VERSION "dbc-export 1 2026.26.6.5"

NS_ :

BS_:

BU_: ADSP APB APP APS APSB BB BMS CC CMP CMPD CP DAS DI DIF DIR DPB EPAS3P EPAS3S EPASTP EPASTS EPBL EPBR ESP EVSE FC GTW HCML HCMR HVP IBST ICR IDB LS OCS1P ODIN PARK PCS PCS2 PLG PM PMF PMR PNCD PTC RADC RCM RCM2 RCM3 RCU SCCM SCM SCS SDCR TAS TCU TCU2 TPMS TRCM UDS UI UIS UMC USM V2G VC VCBATT VCBATT0 VCBATT1 VCBATT2 VCCC VCFRONT VCFRONT1 VCFRONT2 VCLEFT VCRIGHT VCSEAT2L VCSEAT2R VCSEC VEH

BO_ 871 DI_alertMatrix: 8 DI
 SG_ DI_matrixIndex M : 0|4@1+ (1,0) [0|15] "" Vector__XXX
 SG_ DI_a001_frunkSpeedLimitActive m0 : 4|1@1+ (1,0) [0|1] "" Vector__XXX
 SG_ DI_a002_parkButtonDuringStalkReq m0 : 5|1@1+ (1,0) [0|1] "" Vector__XXX
 SG_ DI_a003_suggestedGearOverride m0 : 6|1@1+ (1,0) [0|1] "" Vector__XXX
 SG_ DI_a004_smartShiftUnavailable m0 : 7|1@1+ (1,0) [0|1] "" Vector__XXX
 SG_ DI_a005_stalkPanicked m0 : 8|1@1+ (1,0) [0|1] "" Vector__XXX
 SG_ DI_a006_shifterUnavailable m0 : 9|1@1+ (1,0) [0|1] "" Vector__XXX
 SG_ DI_a007_secGearSelButtonStuck m0 : 10|1@1+ (1,0) [0|1] "" Vector__XXX
 SG_ DI_a010_unintendedReset m0 : 13|1@1+ (1,0) [0|1] "" Vector__XXX
 SG_ DI_a012_accel5VSupply m0 : 15|1@1+ (1,0) [0|1] "" Vector__XXX
 SG_ DI_a013_eccError m0 : 16|1@1+ (1,0) [0|1] "" Vector__XXX
 SG_ DI_a014_secGearSelActivated m0 : 17|1@1+ (1,0) [0|1] "" Vector__XXX
 SG_ DI_a015_immobilizer m0 : 18|1@1+ (1,0) [0|1] "" Vector__XXX
 SG_ DI_a016_parkRequestByPM m0 : 19|1@1+ (1,0) [0|1] "" Vector__XXX
 SG_ DI_a017_hwPedalMonitor m0 : 20|1@1+ (1,0) [0|1] "" Vector__XXX
 SG_ DI_a018_hwLVSupplyUV m0 : 21|1@1+ (1,0) [0|1] "" Vector__XXX
 SG_ DI_a019_hwAccelPedalPower m0 : 22|1@1+ (1,0) [0|1] "" Vector__XXX
 SG_ DI_a020_systemHvilNotClosed m0 : 23|1@1+ (1,0) [0|1] "" Vector__XXX
 SG_ DI_a021_packOvervoltage m0 : 24|1@1+ (1,0) [0|1] "" Vector__XXX
 SG_ DI_a022_hw5vSupplyUV m0 : 25|1@1+ (1,0) [0|1] "" Vector__XXX
 SG_ DI_a023_carNotParked m0 : 26|1@1+ (1,0) [0|1] "" Vector__XXX
 SG_ DI_a024_holdNForNeutral m0 : 27|1@1+ (1,0) [0|1] "" Vector__XXX
 SG_ DI_a025_regenBackfillUnavailable m0 : 28|1@1+ (1,0) [0|1] "" Vector__XXX
 SG_ DI_a026_parkPressedWithHighAPeda m0 : 29|1@1+ (1,0) [0|1] "" Vector__XXX
 SG_ DI_a027_steeringAngleOffsetServi m0 : 30|1@1+ (1,0) [0|1] "" Vector__XXX
 SG_ DI_a028_secondaryShifterMuted m0 : 31|1@1+ (1,0) [0|1] "" Vector__XXX
 SG_ DI_a031_closureAccelerationLimit m0 : 34|1@1+ (1,0) [0|1] "" Vector__XXX
 SG_ DI_a036_sysStandbyUnitLimitedWai m0 : 39|1@1+ (1,0) [0|1] "" Vector__XXX
 SG_ DI_a039_exceptionUndefinedInstru m0 : 42|1@1+ (1,0) [0|1] "" Vector__XXX
 SG_ DI_a040_difMIA m0 : 43|1@1+ (1,0) [0|1] "" Vector__XXX
 SG_ DI_a041_driverBrakeApplyStuck m0 : 44|1@1+ (1,0) [0|1] "" Vector__XXX
 SG_ DI_a042_pmfMIA m0 : 45|1@1+ (1,0) [0|1] "" Vector__XXX
 SG_ DI_a043_pmrMIA m0 : 46|1@1+ (1,0) [0|1] "" Vector__XXX
 SG_ DI_d047_interfacePowerSupplyIssu m0 : 50|1@1+ (1,0) [0|1] "" Vector__XXX
 SG_ DI_a048_ecuLogAvailable m0 : 51|1@1+ (1,0) [0|1] "" Vector__XXX
 SG_ DI_d049_invalidOdometerReading m0 : 52|1@1+ (1,0) [0|1] "" Vector__XXX
 SG_ DI_d050_interfaceUnitCommunicati m0 : 53|1@1+ (1,0) [0|1] "" Vector__XXX
 SG_ DI_a051_batteryOvercurrent m0 : 54|1@1+ (1,0) [0|1] "" Vector__XXX
 SG_ DI_a052_dirMIA m0 : 55|1@1+ (1,0) [0|1] "" Vector__XXX
 SG_ DI_a053_canDataBusC m0 : 56|1@1+ (1,0) [0|1] "" Vector__XXX
 SG_ DI_a054_canOverrunBusC m0 : 57|1@1+ (1,0) [0|1] "" Vector__XXX
 SG_ DI_a055_canHardwareBusC m0 : 58|1@1+ (1,0) [0|1] "" Vector__XXX
 SG_ DI_a056_canDataBusD m0 : 59|1@1+ (1,0) [0|1] "" Vector__XXX
 SG_ DI_a057_canOverrunBusD m0 : 60|1@1+ (1,0) [0|1] "" Vector__XXX
 SG_ DI_a058_canHardwareBusD m0 : 61|1@1+ (1,0) [0|1] "" Vector__XXX
 SG_ DI_a059_canDataBusE m0 : 62|1@1+ (1,0) [0|1] "" Vector__XXX
 SG_ DI_a060_canOverrunBusE m0 : 63|1@1+ (1,0) [0|1] "" Vector__XXX
 SG_ DI_a061_canHardwareBusE m1 : 4|1@1+ (1,0) [0|1] "" Vector__XXX
 SG_ DI_a062_systemLimpMode m1 : 5|1@1+ (1,0) [0|1] "" Vector__XXX
 SG_ DI_a063_systemGracefulPowerOff m1 : 6|1@1+ (1,0) [0|1] "" Vector__XXX
 SG_ DI_a064_pmsrmUnitMiaWithHvDown m1 : 7|1@1+ (1,0) [0|1] "" Vector__XXX
 SG_ DI_a065_canHardwareBusB m1 : 8|1@1+ (1,0) [0|1] "" Vector__XXX
 SG_ DI_a066_canDataBusB m1 : 9|1@1+ (1,0) [0|1] "" Vector__XXX
 SG_ DI_a067_canOverrunBusB m1 : 10|1@1+ (1,0) [0|1] "" Vector__XXX
 SG_ DI_a068_secondaryWheelSpeedIrrat m1 : 11|1@1+ (1,0) [0|1] "" Vector__XXX
 SG_ DI_a070_udsTransactionInitiated m1 : 13|1@1+ (1,0) [0|1] "" Vector__XXX
 SG_ DI_d072_accelPedalSensorIssue m1 : 15|1@1+ (1,0) [0|1] "" Vector__XXX
 SG_ DI_d073_accelPedalVoltSupplyIssu m1 : 16|1@1+ (1,0) [0|1] "" Vector__XXX
 SG_ DI_a074_unintendedResetAutoshift m1 : 17|1@1+ (1,0) [0|1] "" Vector__XXX
 SG_ DI_d075_incorrectImmobilizerKey m1 : 18|1@1+ (1,0) [0|1] "" Vector__XXX
 SG_ DI_a076_lvSupplyOV m1 : 19|1@1+ (1,0) [0|1] "" Vector__XXX
 SG_ DI_a077_lvSupplyUV m1 : 20|1@1+ (1,0) [0|1] "" Vector__XXX
 SG_ DI_a078_adcRefLow m1 : 21|1@1+ (1,0) [0|1] "" Vector__XXX
 SG_ DI_a079_adcRefHigh m1 : 22|1@1+ (1,0) [0|1] "" Vector__XXX
 SG_ DI_a080_accelSynch m1 : 23|1@1+ (1,0) [0|1] "" Vector__XXX
 SG_ DI_a081_accelTrack1 m1 : 24|1@1+ (1,0) [0|1] "" Vector__XXX
 SG_ DI_a082_accelTrack2 m1 : 25|1@1+ (1,0) [0|1] "" Vector__XXX
 SG_ DI_a083_brakePedalSensor m1 : 26|1@1+ (1,0) [0|1] "" Vector__XXX
 SG_ DI_a084_eccTestData0 m1 : 27|1@1+ (1,0) [0|1] "" Vector__XXX
 SG_ DI_a085_proximityInEnable m1 : 28|1@1+ (1,0) [0|1] "" Vector__XXX
 SG_ DI_a086_dpbMIA m1 : 29|1@1+ (1,0) [0|1] "" Vector__XXX
 SG_ DI_a087_gtwMIA m1 : 30|1@1+ (1,0) [0|1] "" Vector__XXX
 SG_ DI_a088_uiMIA m1 : 31|1@1+ (1,0) [0|1] "" Vector__XXX
 SG_ DI_a089_sccmMIA m1 : 32|1@1+ (1,0) [0|1] "" Vector__XXX
 SG_ DI_a090_pmMIA m1 : 33|1@1+ (1,0) [0|1] "" Vector__XXX
 SG_ DI_a091_espMIA m1 : 34|1@1+ (1,0) [0|1] "" Vector__XXX
 SG_ DI_a092_bmsMIA m1 : 35|1@1+ (1,0) [0|1] "" Vector__XXX
 SG_ DI_a093_canHardwareBusA m1 : 36|1@1+ (1,0) [0|1] "" Vector__XXX
 SG_ DI_a094_canDataBusA m1 : 37|1@1+ (1,0) [0|1] "" Vector__XXX
 SG_ DI_a095_canOverrunBusA m1 : 38|1@1+ (1,0) [0|1] "" Vector__XXX
 SG_ DI_a096_memoryError m1 : 39|1@1+ (1,0) [0|1] "" Vector__XXX
 SG_ DI_a097_eepromError m1 : 40|1@1+ (1,0) [0|1] "" Vector__XXX
 SG_ DI_a098_eepromManagerError m1 : 41|1@1+ (1,0) [0|1] "" Vector__XXX
 SG_ DI_a099_threadOverrun m1 : 42|1@1+ (1,0) [0|1] "" Vector__XXX
 SG_ DI_a100_nvramError m1 : 43|1@1+ (1,0) [0|1] "" Vector__XXX
 SG_ DI_a101_eccTestData1 m1 : 44|1@1+ (1,0) [0|1] "" Vector__XXX
 SG_ DI_a102_exceptionPrefetchAbort m1 : 45|1@1+ (1,0) [0|1] "" Vector__XXX
 SG_ DI_a103_bbMIA m1 : 46|1@1+ (1,0) [0|1] "" Vector__XXX
 SG_ DI_a104_proximityIrrational m1 : 47|1@1+ (1,0) [0|1] "" Vector__XXX
 SG_ DI_a105_cpMIA m1 : 48|1@1+ (1,0) [0|1] "" Vector__XXX
 SG_ DI_a106_idleTaskStarving m1 : 49|1@1+ (1,0) [0|1] "" Vector__XXX
 SG_ DI_a107_idbBrakeCircuitPressureO m1 : 50|1@1+ (1,0) [0|1] "" Vector__XXX
 SG_ DI_a108_appMIA m1 : 51|1@1+ (1,0) [0|1] "" Vector__XXX
 SG_ DI_a109_ahbWriteError m1 : 52|1@1+ (1,0) [0|1] "" Vector__XXX
 SG_ DI_a110_brakeMIA m1 : 53|1@1+ (1,0) [0|1] "" Vector__XXX
 SG_ DI_a111_idbMIA m1 : 54|1@1+ (1,0) [0|1] "" Vector__XXX
 SG_ DI_a112_accelTrack1Incons m1 : 55|1@1+ (1,0) [0|1] "" Vector__XXX
 SG_ DI_a113_lowBrakeMCPressure m1 : 56|1@1+ (1,0) [0|1] "" Vector__XXX
 SG_ DI_a114_exceptionDataAbort m1 : 57|1@1+ (1,0) [0|1] "" Vector__XXX
 SG_ DI_a115_exceptionDataAbort2 m1 : 58|1@1+ (1,0) [0|1] "" Vector__XXX
 SG_ DI_a116_motorRecovered m1 : 59|1@1+ (1,0) [0|1] "" Vector__XXX
 SG_ DI_a117_latentFaultCheckTripped m1 : 60|1@1+ (1,0) [0|1] "" Vector__XXX
 SG_ DI_a118_diImmobilizedForFactoryF m1 : 61|1@1+ (1,0) [0|1] "" Vector__XXX
 SG_ DI_a119_latentFaultCheckFailedOn m1 : 62|1@1+ (1,0) [0|1] "" Vector__XXX
 SG_ DI_a120_regenBlendingUnavailable m1 : 63|1@1+ (1,0) [0|1] "" Vector__XXX
 SG_ DI_a121_qualifiedBrakeEventMitig m2 : 4|1@1+ (1,0) [0|1] "" Vector__XXX
 SG_ DI_a122_highStackUsage m2 : 5|1@1+ (1,0) [0|1] "" Vector__XXX
 SG_ DI_a124_cruiseFault m2 : 7|1@1+ (1,0) [0|1] "" Vector__XXX
 SG_ DI_a125_noBatteryPower m2 : 8|1@1+ (1,0) [0|1] "" Vector__XXX
 SG_ DI_a129_epbNotApplied m2 : 12|1@1+ (1,0) [0|1] "" Vector__XXX
 SG_ DI_a130_aebFault m2 : 13|1@1+ (1,0) [0|1] "" Vector__XXX
 SG_ DI_a131_highSpeedWearLimit m2 : 14|1@1+ (1,0) [0|1] "" Vector__XXX
 SG_ DI_a133_vehicleHoldTimedOut m2 : 16|1@1+ (1,0) [0|1] "" Vector__XXX
 SG_ DI_a134_wheelSpeedIrrational m2 : 17|1@1+ (1,0) [0|1] "" Vector__XXX
 SG_ DI_a135_vehicleHoldFault m2 : 18|1@1+ (1,0) [0|1] "" Vector__XXX
 SG_ DI_a137_noCapableDriveUnits m2 : 20|1@1+ (1,0) [0|1] "" Vector__XXX
 SG_ DI_a138_frontUnitDisabled m2 : 21|1@1+ (1,0) [0|1] "" Vector__XXX
 SG_ DI_a139_rearUnitDisabled m2 : 22|1@1+ (1,0) [0|1] "" Vector__XXX
 SG_ DI_a140_ptcMIA m2 : 23|1@1+ (1,0) [0|1] "" Vector__XXX
 SG_ DI_a141_dasMIA m2 : 24|1@1+ (1,0) [0|1] "" Vector__XXX
 SG_ DI_a142_potholeDetected m2 : 25|1@1+ (1,0) [0|1] "" Vector__XXX
 SG_ DI_a143_mcuLimitActive m2 : 26|1@1+ (1,0) [0|1] "" Vector__XXX
 SG_ DI_a144_configMismatch m2 : 27|1@1+ (1,0) [0|1] "" Vector__XXX
 SG_ DI_a146_pbrkPanicEpbFault m2 : 29|1@1+ (1,0) [0|1] "" Vector__XXX
 SG_ DI_a154_vdcRearSteering m2 : 37|1@1+ (1,0) [0|1] "" Vector__XXX
 SG_ DI_a155_vcfrontMIA m2 : 38|1@1+ (1,0) [0|1] "" Vector__XXX
 SG_ DI_a157_rcmMIA m2 : 40|1@1+ (1,0) [0|1] "" Vector__XXX
 SG_ DI_a158_ibstMIA m2 : 41|1@1+ (1,0) [0|1] "" Vector__XXX
 SG_ DI_a159_cruiseSelfCheck m2 : 42|1@1+ (1,0) [0|1] "" Vector__XXX
 SG_ DI_a160_fastLearnComplete m2 : 43|1@1+ (1,0) [0|1] "" Vector__XXX
 SG_ DI_a161_epas3pMIA m2 : 44|1@1+ (1,0) [0|1] "" Vector__XXX
 SG_ DI_a162_shiftDenied m2 : 45|1@1+ (1,0) [0|1] "" Vector__XXX
 SG_ DI_a163_shiftMotorSpeed m2 : 46|1@1+ (1,0) [0|1] "" Vector__XXX
 SG_ DI_a164_brakeOverride m2 : 47|1@1+ (1,0) [0|1] "" Vector__XXX
 SG_ DI_a165_cruiseCancelled m2 : 48|1@1+ (1,0) [0|1] "" Vector__XXX
 SG_ DI_a166_driverLeft m2 : 49|1@1+ (1,0) [0|1] "" Vector__XXX
 SG_ DI_a167_keyNotAuthenticated m2 : 50|1@1+ (1,0) [0|1] "" Vector__XXX
 SG_ DI_a168_proximityDriveDenial m2 : 51|1@1+ (1,0) [0|1] "" Vector__XXX
 SG_ DI_a169_regenOffOverride m2 : 52|1@1+ (1,0) [0|1] "" Vector__XXX
 SG_ DI_a170_tireConfigUpdated m2 : 53|1@1+ (1,0) [0|1] "" Vector__XXX
 SG_ DI_a171_driveRailNotRequested m2 : 54|1@1+ (1,0) [0|1] "" Vector__XXX
 SG_ DI_a172_accelPressedInNP m2 : 55|1@1+ (1,0) [0|1] "" Vector__XXX
 SG_ DI_a173_bothPedalsPressed m2 : 56|1@1+ (1,0) [0|1] "" Vector__XXX
 SG_ DI_a174_notOkToStartDrive m2 : 57|1@1+ (1,0) [0|1] "" Vector__XXX
 SG_ DI_a175_crsNotAvailable m2 : 58|1@1+ (1,0) [0|1] "" Vector__XXX
 SG_ DI_a176_EBRreleased m2 : 59|1@1+ (1,0) [0|1] "" Vector__XXX
 SG_ DI_a177_tireFitmentChanged m2 : 60|1@1+ (1,0) [0|1] "" Vector__XXX
 SG_ DI_a178_steeringAngleOffsetFault m2 : 61|1@1+ (1,0) [0|1] "" Vector__XXX
 SG_ DI_a179_steeringAngleOffsetWarni m2 : 62|1@1+ (1,0) [0|1] "" Vector__XXX
 SG_ DI_a180_crsSeatbeltUnbuckled m2 : 63|1@1+ (1,0) [0|1] "" Vector__XXX
 SG_ DI_a181_rearMotorMode m3 : 4|1@1+ (1,0) [0|1] "" Vector__XXX
 SG_ DI_a182_frontMotorMode m3 : 5|1@1+ (1,0) [0|1] "" Vector__XXX
 SG_ DI_a183_holdReleaseRqrd m3 : 6|1@1+ (1,0) [0|1] "" Vector__XXX
 SG_ DI_a184_autoparkCanceled m3 : 7|1@1+ (1,0) [0|1] "" Vector__XXX
 SG_ DI_a185_autoparkAborted m3 : 8|1@1+ (1,0) [0|1] "" Vector__XXX
 SG_ DI_a186_brakeStand m3 : 9|1@1+ (1,0) [0|1] "" Vector__XXX
 SG_ DI_a187_pedalMisapplication m3 : 10|1@1+ (1,0) [0|1] "" Vector__XXX
 SG_ DI_a188_tireRotationRecommendedG m3 : 11|1@1+ (1,0) [0|1] "" Vector__XXX
 SG_ DI_a189_garageShiftWithPedal m3 : 12|1@1+ (1,0) [0|1] "" Vector__XXX
 SG_ DI_a190_tireRotationRecommended m3 : 13|1@1+ (1,0) [0|1] "" Vector__XXX
 SG_ DI_a191_brakeShiftReq m3 : 14|1@1+ (1,0) [0|1] "" Vector__XXX
 SG_ DI_a192_invalidOdometer m3 : 15|1@1+ (1,0) [0|1] "" Vector__XXX
 SG_ DI_a193_vdcBrakeTorqueFr m3 : 16|1@1+ (1,0) [0|1] "" Vector__XXX
 SG_ DI_a194_vdcBrakeTorqueRe m3 : 17|1@1+ (1,0) [0|1] "" Vector__XXX
 SG_ DI_a195_vdcEspSlipFr m3 : 18|1@1+ (1,0) [0|1] "" Vector__XXX
 SG_ DI_a196_vdcEspSlipRe m3 : 19|1@1+ (1,0) [0|1] "" Vector__XXX
 SG_ DI_a197_vdcEspWheelSaturations m3 : 20|1@1+ (1,0) [0|1] "" Vector__XXX
 SG_ DI_a198_vdcEspMCPressAndSteering m3 : 21|1@1+ (1,0) [0|1] "" Vector__XXX
 SG_ DI_a199_vdcFaulted m3 : 22|1@1+ (1,0) [0|1] "" Vector__XXX
 SG_ DI_a200_vdcModelBasedPlausibilit m3 : 23|1@1+ (1,0) [0|1] "" Vector__XXX
 SG_ DI_a201_decelTorqueLimited m3 : 24|1@1+ (1,0) [0|1] "" Vector__XXX
 SG_ DI_a202_excessHeatUnavailable m3 : 25|1@1+ (1,0) [0|1] "" Vector__XXX
 SG_ DI_a203_TCReducedByADD m3 : 26|1@1+ (1,0) [0|1] "" Vector__XXX
 SG_ DI_a204_vdcRcmLongitudinal m3 : 27|1@1+ (1,0) [0|1] "" Vector__XXX
 SG_ DI_a205_vdcRcmLateral m3 : 28|1@1+ (1,0) [0|1] "" Vector__XXX
 SG_ DI_a206_vdcRcmVertical m3 : 29|1@1+ (1,0) [0|1] "" Vector__XXX
 SG_ DI_a207_vdcPowertrainTorque_dif m3 : 30|1@1+ (1,0) [0|1] "" Vector__XXX
 SG_ DI_a208_vdcPowertrainTorque_dir m3 : 31|1@1+ (1,0) [0|1] "" Vector__XXX
 SG_ DI_a210_vdcOtherControllerStates m3 : 33|1@1+ (1,0) [0|1] "" Vector__XXX
 SG_ DI_a211_vdcMotorSpeed_dif m3 : 34|1@1+ (1,0) [0|1] "" Vector__XXX
 SG_ DI_a212_vdcWheelRotations m3 : 35|1@1+ (1,0) [0|1] "" Vector__XXX
 SG_ DI_a213_lowMuProbabilityChange m3 : 36|1@1+ (1,0) [0|1] "" Vector__XXX
 SG_ DI_a214_vdcWheelSpeedFr m3 : 37|1@1+ (1,0) [0|1] "" Vector__XXX
 SG_ DI_a215_vdcWheelSpeedRe m3 : 38|1@1+ (1,0) [0|1] "" Vector__XXX
 SG_ DI_a216_vdcMBPAlmostTripped m3 : 39|1@1+ (1,0) [0|1] "" Vector__XXX
 SG_ DI_a217_vdcOutputIrrational m3 : 40|1@1+ (1,0) [0|1] "" Vector__XXX
 SG_ DI_a218_vdcOSPreControlActive m3 : 41|1@1+ (1,0) [0|1] "" Vector__XXX
 SG_ DI_a219_vdcOversteerdMzActive m3 : 42|1@1+ (1,0) [0|1] "" Vector__XXX
 SG_ DI_a220_vdcUndersteerDecelActive m3 : 43|1@1+ (1,0) [0|1] "" Vector__XXX
 SG_ DI_a221_vdcUndersteerdMzActive m3 : 44|1@1+ (1,0) [0|1] "" Vector__XXX
 SG_ DI_a222_vdcDisabled m3 : 45|1@1+ (1,0) [0|1] "" Vector__XXX
 SG_ DI_a223_tractionControlDisabled m3 : 46|1@1+ (1,0) [0|1] "" Vector__XXX
 SG_ DI_a224_brakeOverTemp m3 : 47|1@1+ (1,0) [0|1] "" Vector__XXX
 SG_ DI_a225_vyEstimatorDegradedDebug m3 : 48|1@1+ (1,0) [0|1] "" Vector__XXX
 SG_ DI_a226_sysStartConditionNotMet m3 : 49|1@1+ (1,0) [0|1] "" Vector__XXX
 SG_ DI_a227_contactorsNotClosed m3 : 50|1@1+ (1,0) [0|1] "" Vector__XXX
 SG_ DI_a228_brakeTempEstUnavailable m3 : 51|1@1+ (1,0) [0|1] "" Vector__XXX
 SG_ DI_a230_cmpMIA m3 : 53|1@1+ (1,0) [0|1] "" Vector__XXX
 SG_ DI_a231_softSystemLimpMode m3 : 54|1@1+ (1,0) [0|1] "" Vector__XXX
 SG_ DI_a232_velocityEstimatorDegrade m3 : 55|1@1+ (1,0) [0|1] "" Vector__XXX
 SG_ DI_a233_frontWheelImpactDetected m3 : 56|1@1+ (1,0) [0|1] "" Vector__XXX
 SG_ DI_a235_trackModeActive m3 : 58|1@1+ (1,0) [0|1] "" Vector__XXX
 SG_ DI_a236_tasMIA m3 : 59|1@1+ (1,0) [0|1] "" Vector__XXX
 SG_ DI_a237_undersideAbuse m3 : 60|1@1+ (1,0) [0|1] "" Vector__XXX
 SG_ DI_a238_secondaryCollisionMitiga m3 : 61|1@1+ (1,0) [0|1] "" Vector__XXX
 SG_ DI_a239_neutralRequestByPM m3 : 62|1@1+ (1,0) [0|1] "" Vector__XXX
 SG_ DI_a240_torqueSplitStuck m3 : 63|1@1+ (1,0) [0|1] "" Vector__XXX
 SG_ DI_a241_vdcMotorSpeed_dir m4 : 4|1@1+ (1,0) [0|1] "" Vector__XXX
 SG_ DI_a242_vdcTrailerSwayDetected m4 : 5|1@1+ (1,0) [0|1] "" Vector__XXX
 SG_ DI_a243_rcuMIA m4 : 6|1@1+ (1,0) [0|1] "" Vector__XXX
 SG_ DI_a244_vseRLSMassMismatch m4 : 7|1@1+ (1,0) [0|1] "" Vector__XXX
 SG_ DI_a245_opdReducedWithoutEbr m4 : 8|1@1+ (1,0) [0|1] "" Vector__XXX
 SG_ DI_a246_opdUnavailable m4 : 9|1@1+ (1,0) [0|1] "" Vector__XXX
 SG_ DI_a248_vdcPreControlHighDynamic m4 : 11|1@1+ (1,0) [0|1] "" Vector__XXX
 SG_ DI_a249_spinDownLearningInProgre m4 : 12|1@1+ (1,0) [0|1] "" Vector__XXX
 SG_ DI_a250_tasSpeedLimitActive m4 : 13|1@1+ (1,0) [0|1] "" Vector__XXX
 SG_ DI_a251_diPowerOnStateMismatch m4 : 14|1@1+ (1,0) [0|1] "" Vector__XXX
 SG_ DI_a253_accelSynchWarn m4 : 16|1@1+ (1,0) [0|1] "" Vector__XXX
 SG_ DI_a254_vehicleStuckDetected m4 : 17|1@1+ (1,0) [0|1] "" Vector__XXX
 SG_ DI_a255_manualRecoveryMode m4 : 18|1@1+ (1,0) [0|1] "" Vector__XXX

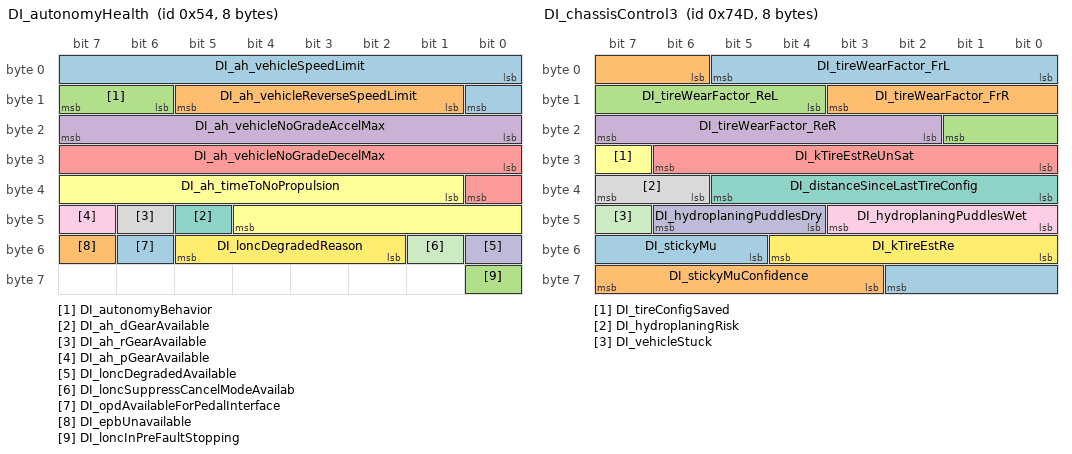
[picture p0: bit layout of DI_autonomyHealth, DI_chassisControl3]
BO_ 84 DI_autonomyHealth: 8 DI
 SG_ DI_ah_vehicleSpeedLimit : 0|9@1+ (1,0) [0|300] "kph" Vector__XXX
 SG_ DI_ah_vehicleReverseSpeedLimit : 9|5@1+ (1,0) [0|31] "kph" Vector__XXX
 SG_ DI_autonomyBehavior : 14|2@1+ (1,0) [0|3] "" Vector__XXX
 SG_ DI_ah_vehicleNoGradeAccelMax : 16|8@1+ (0.04,0) [0|10] "m/s^2" Vector__XXX
 SG_ DI_ah_vehicleNoGradeDecelMax : 24|9@1+ (0.04,0) [0|15] "m/s^2" Vector__XXX
 SG_ DI_ah_timeToNoPropulsion : 33|12@1+ (1,0) [0|4094] "s" Vector__XXX
 SG_ DI_ah_dGearAvailable : 45|1@1+ (1,0) [0|1] "" Vector__XXX
 SG_ DI_ah_rGearAvailable : 46|1@1+ (1,0) [0|1] "" Vector__XXX
 SG_ DI_ah_pGearAvailable : 47|1@1+ (1,0) [0|1] "" Vector__XXX
 SG_ DI_loncDegradedAvailable : 48|1@1+ (1,0) [0|1] "" Vector__XXX
 SG_ DI_loncSuppressCancelModeAvailab : 49|1@1+ (1,0) [0|1] "" Vector__XXX
 SG_ DI_loncDegradedReason : 50|4@1+ (1,0) [0|15] "" Vector__XXX
 SG_ DI_opdAvailableForPedalInterface : 54|1@1+ (1,0) [0|1] "" Vector__XXX
 SG_ DI_epbUnavailable : 55|1@1+ (1,0) [0|1] "" Vector__XXX
 SG_ DI_loncInPreFaultStopping : 56|1@1+ (1,0) [0|1] "" Vector__XXX

BO_ 328 DI_chassisControl: 8 DI
 SG_ DI_chassisControlChecksum : 0|8@1+ (1,0) [0|255] "" Vector__XXX
 SG_ DI_chassisControlCounter : 8|4@1+ (1,0) [0|15] "" Vector__XXX
 SG_ DI_imuOffsetLearnRequest : 12|2@1+ (1,0) [0|3] "" Vector__XXX
 SG_ DI_brakeCommandType : 14|1@1+ (1,0) [0|1] "" Vector__XXX
 SG_ DI_brakeTorqueRequestActive : 15|1@1+ (1,0) [0|1] "" Vector__XXX
 SG_ DI_brakeTorqueCommand : 16|13@1+ (3,0) [0|24573] "Nm" Vector__XXX
 SG_ DI_ptcStateGlobal : 29|2@1+ (1,0) [0|2] "" Vector__XXX
 SG_ DI_ptcActive : 31|1@1+ (1,0) [0|1] "" Vector__XXX
 SG_ DI_vdcState : 32|2@1+ (1,0) [0|3] "" Vector__XXX
 SG_ DI_isAnyVdcControlActive : 34|2@1+ (1,0) [0|3] "" Vector__XXX
 SG_ DI_vdcMode : 36|2@1+ (1,0) [0|3] "" Vector__XXX
 SG_ DI_pedalAssistCurveSelect : 38|4@1+ (1,0) [0|15] "" Vector__XXX
 SG_ DI_isAnyTcActive : 42|1@1+ (1,0) [0|1] "" Vector__XXX
 SG_ DI_VehicleMuConfidence : 43|6@1+ (0.02,0) [0|1.26] "-" Vector__XXX
 SG_ DI_VehicleMu : 49|6@1+ (0.024,0) [0|1.512] "-" Vector__XXX
 SG_ DI_trailerSwayIndex : 55|5@1+ (0.035,0) [0|1] "-" Vector__XXX
 SG_ DI_vdcControlActive : 60|3@1+ (1,0) [0|7] "" Vector__XXX
 SG_ DI_treadDepthAlertSet : 63|1@1+ (1,0) [0|1] "" Vector__XXX

BO_ 1861 DI_chassisControl2: 8 DI
 SG_ DI_gradeAngle : 0|6@1- (0.01,0) [-0.3125|0.31] "rad" Vector__XXX
 SG_ DI_bankAngle : 6|6@1- (0.01,0) [-0.3125|0.31] "rad" Vector__XXX
 SG_ DI_chassisControlVideoRequest : 12|4@1+ (1,0) [0|15] "" Vector__XXX
 SG_ DI_eepDeliveryBitStatus : 16|1@1+ (1,0) [0|1] "" Vector__XXX
 SG_ DI_tireUtilizationRatioFrL : 17|5@1+ (0.0625,0) [0|1.9375] "-" Vector__XXX
 SG_ DI_tireUtilizationRatioFrR : 22|5@1+ (0.0625,0) [0|1.9375] "-" Vector__XXX
 SG_ DI_tireUtilizationRatioReL : 27|5@1+ (0.0625,0) [0|1.9375] "-" Vector__XXX
 SG_ DI_tireUtilizationRatioReR : 32|5@1+ (0.0625,0) [0|1.9375] "-" Vector__XXX
 SG_ DI_counterSteerTarget : 37|2@1+ (1,0) [0|3] "" Vector__XXX
 SG_ DI_splitMuProbability : 39|2@1+ (0.334,0) [0|1] "-" Vector__XXX
 SG_ DI_mzError : 41|2@1+ (1667,0) [0|5000] "Nm" Vector__XXX
 SG_ DI_slipDifferenceFrontRear : 43|3@1- (0.133,0) [-0.52|0.399] "rad" Vector__XXX
 SG_ DI_highFreqYawRate : 46|2@1+ (0.334,0) [0|1] "-" Vector__XXX
 SG_ DI_turnDirection : 48|1@1+ (1,0) [0|1] "" Vector__XXX
 SG_ DI_absolutePreControlRequest : 49|2@1+ (5000,0) [0|15000] "Nm" Vector__XXX
 SG_ DI_oppositeBuildDirFrontAxle : 51|1@1+ (1,0) [0|1] "" Vector__XXX
 SG_ DI_oppositeBuildDirRearAxle : 52|1@1+ (1,0) [0|1] "" Vector__XXX
 SG_ DI_saturatedEffectiveness : 53|1@1+ (1,0) [0|1] "" Vector__XXX
 SG_ DI_driverPanicIndex : 54|2@1+ (0.334,0) [0|1] "-" Vector__XXX
 SG_ DI_learnDownMu : 56|2@1+ (0.334,0) [0|1] "mu" Vector__XXX
 SG_ DI_preControlOpposingTurnDir : 58|1@1+ (1,0) [0|1] "" Vector__XXX
 SG_ DI_driverFxError : 59|2@1+ (1000,0) [0|3000] "N" Vector__XXX
 SG_ DI_targetSaturation : 61|3@1+ (0.572,0) [0|4] "G" Vector__XXX

BO_ 1869 DI_chassisControl3: 8 DI
 SG_ DI_tireWearFactor_FrL : 0|6@1+ (0.00125,0.96) [0.96|1.03875] "ratio" Vector__XXX
 SG_ DI_tireWearFactor_FrR : 6|6@1+ (0.00125,0.96) [0.96|1.03875] "ratio" Vector__XXX
 SG_ DI_tireWearFactor_ReL : 12|6@1+ (0.00125,0.96) [0.96|1.03875] "ratio" Vector__XXX
 SG_ DI_tireWearFactor_ReR : 18|6@1+ (0.00125,0.96) [0.96|1.03875] "ratio" Vector__XXX
 SG_ DI_kTireEstReUnSat : 24|7@1+ (0.001,0.008) [0.008|0.075] "-" Vector__XXX
 SG_ DI_tireConfigSaved : 31|1@1+ (1,0) [0|1] "" Vector__XXX
 SG_ DI_distanceSinceLastTireConfig : 32|6@1+ (500,0) [0|31000] "km" Vector__XXX
 SG_ DI_hydroplaningRisk : 38|2@1+ (0.333333343267,0) [0|1] "-" Vector__XXX
 SG_ DI_hydroplaningPuddlesWet : 40|4@1+ (1,0) [0|15] "-" Vector__XXX
 SG_ DI_hydroplaningPuddlesDry : 44|3@1+ (1,0) [0|7] "-" Vector__XXX
 SG_ DI_vehicleStuck : 47|1@1+ (1,0) [0|1] "" Vector__XXX
 SG_ DI_kTireEstRe : 48|5@1+ (0.001,0.03) [0.03|0.06] "-" Vector__XXX
 SG_ DI_stickyMu : 53|6@1+ (0.025,0) [0|1.575] "-" Vector__XXX
 SG_ DI_stickyMuConfidence : 59|5@1+ (0.1,0) [0|3] "probability" Vector__XXX

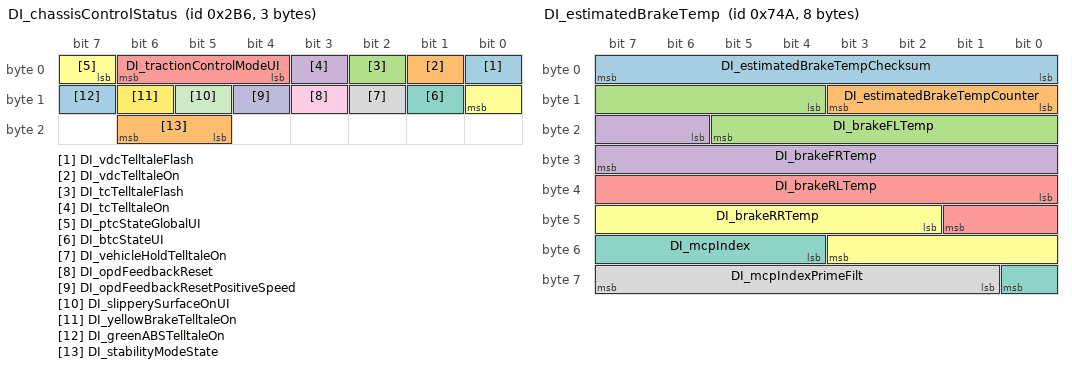
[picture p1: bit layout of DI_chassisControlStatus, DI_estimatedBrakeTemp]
BO_ 694 DI_chassisControlStatus: 3 DI
 SG_ DI_vdcTelltaleFlash : 0|1@1+ (1,0) [0|1] "" Vector__XXX
 SG_ DI_vdcTelltaleOn : 1|1@1+ (1,0) [0|1] "" Vector__XXX
 SG_ DI_tcTelltaleFlash : 2|1@1+ (1,0) [0|1] "" Vector__XXX
 SG_ DI_tcTelltaleOn : 3|1@1+ (1,0) [0|1] "" Vector__XXX
 SG_ DI_tractionControlModeUI : 4|3@1+ (1,0) [0|7] "" Vector__XXX
 SG_ DI_ptcStateGlobalUI : 7|2@1+ (1,0) [0|2] "" Vector__XXX
 SG_ DI_btcStateUI : 9|1@1+ (1,0) [0|1] "" Vector__XXX
 SG_ DI_vehicleHoldTelltaleOn : 10|1@1+ (1,0) [0|1] "" Vector__XXX
 SG_ DI_opdFeedbackReset : 11|1@1+ (1,0) [0|1] "" Vector__XXX
 SG_ DI_opdFeedbackResetPositiveSpeed : 12|1@1+ (1,0) [0|1] "" Vector__XXX
 SG_ DI_slipperySurfaceOnUI : 13|1@1+ (1,0) [0|1] "" Vector__XXX
 SG_ DI_yellowBrakeTelltaleOn : 14|1@1+ (1,0) [0|1] "" Vector__XXX
 SG_ DI_greenABSTelltaleOn : 15|1@1+ (1,0) [0|1] "" Vector__XXX
 SG_ DI_stabilityModeState : 21|2@1+ (1,0) [0|3] "" Vector__XXX

BO_ 2007 DI_debug: 8 DI
 SG_ DI_debugSelector M : 0|8@1+ (1,0) [0|255] "" Vector__XXX
 SG_ DI_regenBackfillCmd m39 : 8|13@1+ (2,0) [0|16382] "Nm" Vector__XXX
 SG_ DI_regenBackfillUnavailableReaso m39 : 21|5@1+ (1,0) [0|31] "" Vector__XXX
 SG_ DI_regenBackfillAbsSatState m39 : 26|2@1+ (1,0) [0|3] "" Vector__XXX
 SG_ DI_sysHeatPowerOptimal m50 : 8|8@1+ (0.08,0) [0|20] "kW" Vector__XXX
 SG_ DI_sysPostPedalMinTorque m53 : 8|15@1+ (0.5,-13000) [-13000|0] "Nm" Vector__XXX
 SG_ DI_sysPostPedalMaxTorque m53 : 24|15@1+ (0.5,0) [0|13000] "Nm" Vector__XXX
 SG_ DI_systemTorqueCommand m53 : 40|16@1- (0.5,0) [-13000|13000] "Nm" Vector__XXX

BO_ 1866 DI_estimatedBrakeTemp: 8 DI
 SG_ DI_estimatedBrakeTempChecksum : 0|8@1+ (1,0) [0|255] "" Vector__XXX
 SG_ DI_estimatedBrakeTempCounter : 8|4@1+ (1,0) [0|15] "" Vector__XXX
 SG_ DI_brakeFLTemp : 12|10@1+ (1,-40) [-40|982] "DegC" Vector__XXX
 SG_ DI_brakeFRTemp : 22|10@1+ (1,-40) [-40|982] "DegC" Vector__XXX
 SG_ DI_brakeRLTemp : 32|10@1+ (1,-40) [-40|982] "DegC" Vector__XXX
 SG_ DI_brakeRRTemp : 42|10@1+ (1,-40) [-40|982] "DegC" Vector__XXX
 SG_ DI_mcpIndex : 52|5@1- (0.05,0.75) [-0.05|1.5] "ratio" Vector__XXX
 SG_ DI_mcpIndexPrimeFilt : 57|7@1- (0.015,0.9) [-0.05|1.84] "ratio" Vector__XXX

BO_ 1623 DI_info: 8 DI
 SG_ DI_infoIndex M : 0|8@1+ (1,0) [0|255] "" Vector__XXX
 SG_ DI_buildType m10 : 8|3@1+ (1,0) [0|7] "" Vector__XXX
 SG_ DI_buildConfigurationId m10 : 16|16@1+ (1,0) [0|65535] "" Vector__XXX
 SG_ DI_hardwareId m10 : 32|8@1+ (1,0) [0|252] "" Vector__XXX
 SG_ DI_componentId m10 : 48|16@1+ (1,0) [0|65535] "" Vector__XXX
 SG_ DI_pcbaId m11 : 16|8@1+ (1,0) [0|255] "" Vector__XXX
 SG_ DI_assemblyId m11 : 24|8@1+ (1,0) [0|255] "" Vector__XXX
 SG_ DI_usageId m11 : 32|16@1+ (1,0) [0|65535] "" Vector__XXX
 SG_ DI_subUsageId m11 : 48|16@1+ (1,0) [0|65535] "" Vector__XXX
 SG_ DI_applicationCrc m13 : 32|32@1+ (1,0) [0|4294967295] "" Vector__XXX
 SG_ DI_appGitHash m17 : 8|56@1+ (1,0) [0|7.20575940379e+16] "" Vector__XXX
 SG_ DI_bootGitHash m18 : 8|56@1+ (1,0) [0|7.20575940379e+16] "" Vector__XXX

BO_ 646 DI_locStatus: 8 DI
 SG_ DI_locStatusChecksum : 0|8@1+ (1,0) [0|255] "" Vector__XXX
 SG_ DI_locStatusCounter : 8|4@1+ (1,0) [0|15] "" Vector__XXX
 SG_ DI_cruiseState : 12|3@1+ (1,0) [0|7] "" Vector__XXX
 SG_ DI_cruiseSetSpeed : 15|9@1+ (0.5,0) [0|255.5] "speed" Vector__XXX
 SG_ DI_cruiseSetSpeedUnits : 24|1@1+ (1,0) [0|1] "" Vector__XXX
 SG_ DI_autoparkState : 25|4@1+ (1,0) [0|14] "" Vector__XXX
 SG_ DI_parkBrakeState : 29|4@1+ (1,0) [0|14] "" Vector__XXX
 SG_ DI_aebState : 33|3@1+ (1,0) [0|6] "" Vector__XXX
 SG_ DI_loncDeactivationReason : 36|2@1+ (1,0) [0|3] "" Vector__XXX
 SG_ DI_vehicleHoldState : 38|3@1+ (1,0) [0|7] "" Vector__XXX
 SG_ DI_summonInPanic : 41|1@1+ (1,0) [0|1] "" Vector__XXX
 SG_ DI_onePedalDrivingState : 42|4@1+ (1,0) [0|15] "" Vector__XXX
 SG_ DI_brakeStandActive : 46|1@1+ (1,0) [0|1] "" Vector__XXX
 SG_ DI_regenBackfillState : 47|2@1+ (1,0) [0|3] "" Vector__XXX
 SG_ DI_cruiseNotAvailableReason : 49|6@1+ (1,0) [0|63] "" Vector__XXX
 SG_ DI_cruiseFaultReason : 55|5@1+ (1,0) [0|31] "" Vector__XXX
 SG_ DI_cruiseCancelReason : 60|4@1+ (1,0) [0|15] "" Vector__XXX

BO_ 1270 DI_locStatus2: 8 DI
 SG_ DI_locStatus2Checksum : 0|8@1+ (1,0) [0|255] "" Vector__XXX
 SG_ DI_locStatus2Counter : 8|4@1+ (1,0) [0|15] "" Vector__XXX
 SG_ DI_doublePedalState : 12|4@1+ (1,0) [0|15] "" Vector__XXX
 SG_ DI_autopilotRequest : 16|1@1+ (1,0) [0|1] "" Vector__XXX
 SG_ DI_rollPreventionState : 17|3@1+ (1,0) [0|7] "" Vector__XXX
 SG_ DI_locIntegratorSaturated : 20|1@1+ (1,0) [0|1] "" Vector__XXX
 SG_ DI_temporaryOpdActiveAfterLoncCa : 21|1@1+ (1,0) [0|1] "" Vector__XXX
 SG_ DI_reapplyOnParkRequest : 22|1@1+ (1,0) [0|1] "" Vector__XXX
 SG_ DI_veDegradedAtStandstill : 23|1@1+ (1,0) [0|1] "" Vector__XXX
 SG_ DI_brakeCpScale : 25|11@1+ (0.005,0) [0|10] "N/N" Vector__XXX
 SG_ DI_rollbackDistance : 36|8@1+ (0.005,0) [0|1.275] "m" Vector__XXX
 SG_ DI_lowMuProbabilityConfidence : 44|4@1+ (0.06666667,0) [0|1] "-" Vector__XXX
 SG_ DI_pedalAssistCurveSelectForSX : 48|4@1+ (1,0) [0|15] "" Vector__XXX
 SG_ DI_longitudinalControlStack : 52|3@1+ (1,0) [1|7] "" Vector__XXX
 SG_ DI_useDasFallbackBrakeCommands : 55|1@1+ (1,0) [0|1] "" Vector__XXX
 SG_ DI_regenBlendingState : 56|2@1+ (1,0) [0|3] "" Vector__XXX
 SG_ DI_executeBatLocStatus2 : 58|1@1+ (1,0) [0|1] "" Vector__XXX

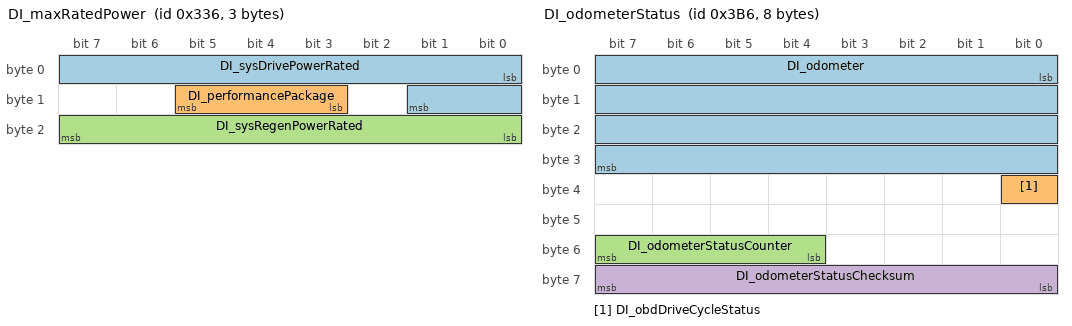
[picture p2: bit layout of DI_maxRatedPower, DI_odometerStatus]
BO_ 822 DI_maxRatedPower: 3 DI
 SG_ DI_sysDrivePowerRated : 0|10@1+ (1,0) [0|1023] "kW" Vector__XXX
 SG_ DI_performancePackage : 11|3@1+ (1,0) [0|6] "" Vector__XXX
 SG_ DI_sysRegenPowerRated : 16|8@1+ (1,-100) [-100|0] "kW" Vector__XXX

BO_ 950 DI_odometerStatus: 8 DI
 SG_ DI_odometer : 0|32@1+ (0.001,0) [0|4294967.294] "km" Vector__XXX
 SG_ DI_obdDriveCycleStatus : 32|1@1+ (1,0) [0|1] "" Vector__XXX
 SG_ DI_odometerStatusCounter : 52|4@1+ (1,0) [0|15] "" Vector__XXX
 SG_ DI_odometerStatusChecksum : 56|8@1+ (1,0) [0|255] "" Vector__XXX

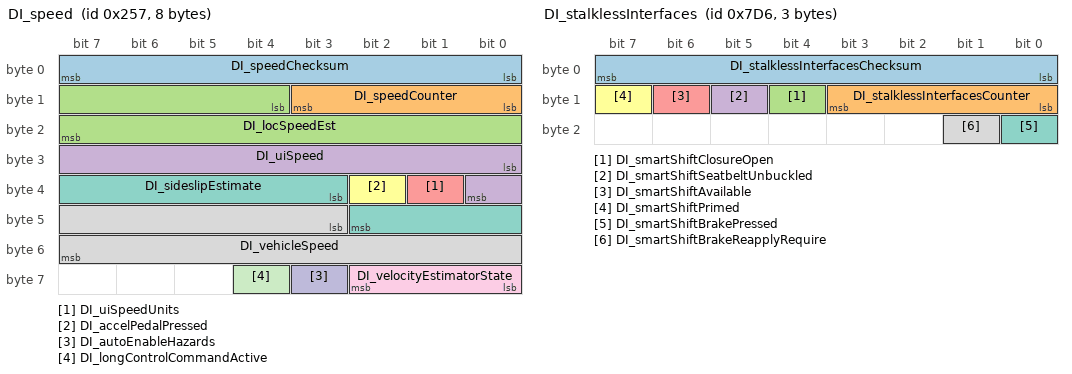
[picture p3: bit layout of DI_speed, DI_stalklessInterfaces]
BO_ 599 DI_speed: 8 DI
 SG_ DI_speedChecksum : 0|8@1+ (1,0) [0|255] "" Vector__XXX
 SG_ DI_speedCounter : 8|4@1+ (1,0) [0|15] "" Vector__XXX
 SG_ DI_locSpeedEst : 12|12@1+ (0.08,-40) [-40|285] "kph" Vector__XXX
 SG_ DI_uiSpeed : 24|9@1+ (1,0) [0|510] "" Vector__XXX
 SG_ DI_uiSpeedUnits : 33|1@1+ (1,0) [0|1] "" Vector__XXX
 SG_ DI_accelPedalPressed : 34|1@1+ (1,0) [0|1] "" Vector__XXX
 SG_ DI_sideslipEstimate : 35|8@1- (0.0025,0) [-0.32|0.3175] "rad" Vector__XXX
 SG_ DI_vehicleSpeed : 43|13@1+ (0.08,-40) [-40|480] "kph" Vector__XXX
 SG_ DI_velocityEstimatorState : 56|3@1+ (1,0) [0|7] "" Vector__XXX
 SG_ DI_autoEnableHazards : 59|1@1+ (1,0) [0|1] "" Vector__XXX
 SG_ DI_longControlCommandActive : 60|1@1+ (1,0) [0|1] "" Vector__XXX

BO_ 2006 DI_stalklessInterfaces: 3 DI
 SG_ DI_stalklessInterfacesChecksum : 0|8@1+ (1,0) [0|255] "" Vector__XXX
 SG_ DI_stalklessInterfacesCounter : 8|4@1+ (1,0) [0|15] "" Vector__XXX
 SG_ DI_smartShiftClosureOpen : 12|1@1+ (1,0) [0|1] "" Vector__XXX
 SG_ DI_smartShiftSeatbeltUnbuckled : 13|1@1+ (1,0) [0|1] "" Vector__XXX
 SG_ DI_smartShiftAvailable : 14|1@1+ (1,0) [0|1] "" Vector__XXX
 SG_ DI_smartShiftPrimed : 15|1@1+ (1,0) [0|1] "" Vector__XXX
 SG_ DI_smartShiftBrakePressed : 16|1@1+ (1,0) [0|1] "" Vector__XXX
 SG_ DI_smartShiftBrakeReapplyRequire : 17|1@1+ (1,0) [0|1] "" Vector__XXX

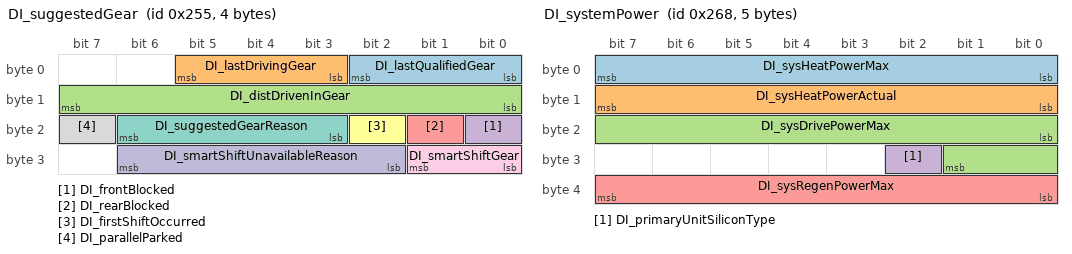
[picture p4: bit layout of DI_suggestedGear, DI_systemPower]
BO_ 597 DI_suggestedGear: 4 DI
 SG_ DI_lastQualifiedGear : 0|3@1+ (1,0) [0|6] "" Vector__XXX
 SG_ DI_lastDrivingGear : 3|3@1+ (1,0) [0|6] "" Vector__XXX
 SG_ DI_distDrivenInGear : 8|8@1+ (0.0235294122249,0) [0|6] "m" Vector__XXX
 SG_ DI_frontBlocked : 16|1@1+ (1,0) [0|1] "" Vector__XXX
 SG_ DI_rearBlocked : 17|1@1+ (1,0) [0|1] "" Vector__XXX
 SG_ DI_firstShiftOccurred : 18|1@1+ (1,0) [0|1] "" Vector__XXX
 SG_ DI_suggestedGearReason : 19|4@1+ (1,0) [0|15] "" Vector__XXX
 SG_ DI_parallelParked : 23|1@1+ (1,0) [0|1] "" Vector__XXX
 SG_ DI_smartShiftGear : 24|2@1+ (1,0) [0|3] "" Vector__XXX
 SG_ DI_smartShiftUnavailableReason : 26|5@1+ (1,0) [1|31] "" Vector__XXX

BO_ 296 DI_systemLimits: 6 DI
 SG_ DI_limitRegenPower : 0|1@1+ (1,0) [0|1] "" Vector__XXX
 SG_ DI_limitIBat : 1|1@1+ (1,0) [0|1] "" Vector__XXX
 SG_ DI_limitVBatLow : 2|1@1+ (1,0) [0|1] "" Vector__XXX
 SG_ DI_limitVBatHigh : 3|1@1+ (1,0) [0|1] "" Vector__XXX
 SG_ DI_limitObstacleDetection : 4|1@1+ (1,0) [0|1] "" Vector__XXX
 SG_ DI_limitSystemLimp : 5|1@1+ (1,0) [0|1] "" Vector__XXX
 SG_ DI_limitSystemGPO : 6|1@1+ (1,0) [0|1] "" Vector__XXX
 SG_ DI_limitShift : 7|1@1+ (1,0) [0|1] "" Vector__XXX
 SG_ DI_limitDriveTorque : 8|1@1+ (1,0) [0|1] "" Vector__XXX
 SG_ DI_limitRegenTorque : 9|1@1+ (1,0) [0|1] "" Vector__XXX
 SG_ DI_limitVehicleSpeed : 10|1@1+ (1,0) [0|1] "" Vector__XXX
 SG_ DI_limitBmsMiaFreeze : 11|1@1+ (1,0) [0|1] "" Vector__XXX
 SG_ DI_limitSystemSpinDownLearning : 12|1@1+ (1,0) [0|1] "" Vector__XXX
 SG_ DI_limitCdp : 13|1@1+ (1,0) [0|1] "" Vector__XXX
 SG_ DI_vehicleSpeedLimitType : 14|2@1+ (1,0) [0|3] "" Vector__XXX
 SG_ DI_vehicleSpeedLimit : 16|9@1+ (1,0) [0|510] "kph" Vector__XXX
 SG_ DI_vehicleSpeedLimitReason : 25|5@1+ (1,0) [0|31] "" Vector__XXX
 SG_ DI_proximity : 30|1@1+ (1,0) [0|1] "" Vector__XXX
 SG_ DI_limitClosureNotClosed : 31|1@1+ (1,0) [0|1] "" Vector__XXX
 SG_ DI_undersideAbuse : 32|1@1+ (1,0) [0|1] "" Vector__XXX
 SG_ DI_immobilizerAuthLevel : 33|2@1+ (1,0) [0|3] "" Vector__XXX
 SG_ DI_manualRecoveryDistanceRemaini : 40|7@1+ (5,0) [0|500] "m" Vector__XXX
 SG_ DI_restrictedDrivingMode : 47|1@1+ (1,0) [0|1] "" Vector__XXX

BO_ 616 DI_systemPower: 5 DI
 SG_ DI_sysHeatPowerMax : 0|8@1+ (0.08,0) [0|20] "kW" Vector__XXX
 SG_ DI_sysHeatPowerActual : 8|8@1+ (0.08,0) [0|20] "kW" Vector__XXX
 SG_ DI_sysDrivePowerMax : 16|10@1+ (1,0) [0|1023] "kW" Vector__XXX
 SG_ DI_primaryUnitSiliconType : 26|1@1+ (1,0) [0|1] "" Vector__XXX
 SG_ DI_sysRegenPowerMax : 32|8@1+ (1,-100) [-100|0] "kW" Vector__XXX

BO_ 280 DI_systemStatus: 8 DI
 SG_ DI_systemStatusChecksum : 0|8@1+ (1,0) [0|255] "" Vector__XXX
 SG_ DI_systemStatusCounter : 8|4@1+ (1,0) [0|15] "" Vector__XXX
 SG_ DI_secondaryGearControlStatus : 12|1@1+ (1,0) [0|1] "" Vector__XXX
 SG_ DI_immobilizerState : 13|3@1+ (1,0) [1|7] "" Vector__XXX
 SG_ DI_systemState : 16|3@1+ (1,0) [0|7] "" Vector__XXX
 SG_ DI_brakePedalState : 19|2@1+ (1,0) [0|3] "" Vector__XXX
 SG_ DI_gear : 21|3@1+ (1,0) [0|6] "" Vector__XXX
 SG_ DI_driveBlocked : 24|3@1+ (1,0) [0|7] "" Vector__XXX
 SG_ DI_hvilSystemStatus : 27|2@1+ (1,0) [0|2] "" Vector__XXX
 SG_ DI_driveModeState : 29|1@1+ (1,0) [0|1] "" Vector__XXX
 SG_ DI_shiftRequestType : 30|2@1+ (1,0) [0|3] "" Vector__XXX
 SG_ DI_accelPedalPos : 32|8@1+ (0.4,0) [0|100] "%" Vector__XXX
 SG_ DI_tractionControlMode : 40|3@1+ (1,0) [0|7] "" Vector__XXX
 SG_ DI_dynoModeAvailable : 43|1@1+ (1,0) [0|1] "" Vector__XXX
 SG_ DI_epbRequest : 44|2@1+ (1,0) [0|3] "" Vector__XXX
 SG_ DI_brakeSource : 46|1@1+ (1,0) [0|1] "" Vector__XXX
 SG_ DI_keepDrivePowerStateRequest : 47|1@1+ (1,0) [0|1] "" Vector__XXX
 SG_ DI_trackModeState : 48|2@1+ (1,0) [0|3] "" Vector__XXX
 SG_ DI_autonomyControlActive : 50|1@1+ (1,0) [0|1] "" Vector__XXX
 SG_ DI_regenLight : 51|1@1+ (1,0) [0|1] "" Vector__XXX
 SG_ DI_vehicleAcceleration : 52|12@1- (0.01,0) [-20.47|20.47] "m/s^2" Vector__XXX

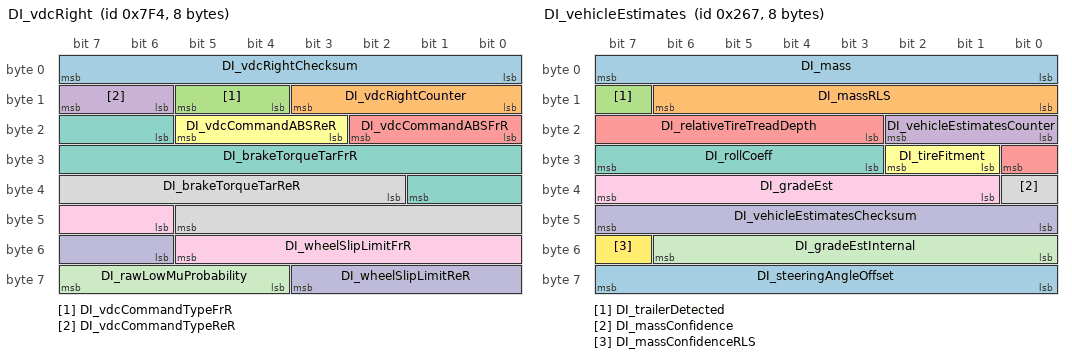
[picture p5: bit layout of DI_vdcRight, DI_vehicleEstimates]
BO_ 2036 DI_vdcRight: 8 DI
 SG_ DI_vdcRightChecksum : 0|8@1+ (1,0) [0|255] "" Vector__XXX
 SG_ DI_vdcRightCounter : 8|4@1+ (1,0) [0|15] "" Vector__XXX
 SG_ DI_vdcCommandTypeFrR : 12|2@1+ (1,0) [0|3] "" Vector__XXX
 SG_ DI_vdcCommandTypeReR : 14|2@1+ (1,0) [0|3] "" Vector__XXX
 SG_ DI_vdcCommandABSFrR : 16|3@1+ (1,0) [0|7] "" Vector__XXX
 SG_ DI_vdcCommandABSReR : 19|3@1+ (1,0) [0|7] "" Vector__XXX
 SG_ DI_brakeTorqueTarFrR : 22|12@1+ (3,-3) [-3|12282] "Nm" Vector__XXX
 SG_ DI_brakeTorqueTarReR : 34|12@1+ (3,-3) [-3|12282] "Nm" Vector__XXX
 SG_ DI_wheelSlipLimitFrR : 46|8@1+ (0.004,-0.004) [-0.004|1] "1" Vector__XXX
 SG_ DI_wheelSlipLimitReR : 54|6@1+ (0.004,-0.004) [-0.004|0.248] "1" Vector__XXX
 SG_ DI_rawLowMuProbability : 60|4@1+ (0.06666667,0) [0|1] "-" Vector__XXX

BO_ 615 DI_vehicleEstimates: 8 DI
 SG_ DI_mass : 0|8@1+ (25,1500) [1500|7850] "kg" Vector__XXX
 SG_ DI_massRLS : 8|7@1+ (45,1500) [1500|7170] "kg" Vector__XXX
 SG_ DI_trailerDetected : 15|1@1+ (1,0) [0|1] "" Vector__XXX
 SG_ DI_vehicleEstimatesCounter : 16|3@1+ (1,0) [0|7] "" Vector__XXX
 SG_ DI_relativeTireTreadDepth : 19|6@1- (0.4,0) [-12.4|12.4] "mm" Vector__XXX
 SG_ DI_tireFitment : 25|2@1+ (1,0) [0|2] "" Vector__XXX
 SG_ DI_rollCoeff : 27|5@1+ (0.001,0) [0|0.03] "g" Vector__XXX
 SG_ DI_massConfidence : 32|1@1+ (1,0) [0|1] "" Vector__XXX
 SG_ DI_gradeEst : 33|7@1- (1,0) [-40|40] "%" Vector__XXX
 SG_ DI_vehicleEstimatesChecksum : 40|8@1+ (1,0) [0|255] "" Vector__XXX
 SG_ DI_gradeEstInternal : 48|7@1- (1,0) [-40|40] "%" Vector__XXX
 SG_ DI_massConfidenceRLS : 55|1@1+ (1,0) [0|1] "" Vector__XXX
 SG_ DI_steeringAngleOffset : 56|8@1- (0.2,0) [-25.6|25.4] "Deg" Vector__XXX

BO_ 1237 DPB_alertLog: 8 DPB
 SG_ DPB_alertID : 0|9@1+ (1,0) [0|511] "" Vector__XXX
 SG_ DPB_alertState : 15|1@1+ (1,0) [0|1] "" Vector__XXX

BO_ 999 DPB_alertMatrix: 8 DPB
 SG_ DPB_matrixIndex M : 0|4@1+ (1,0) [0|15] "" Vector__XXX
 SG_ DPB_a001_pPlungerSensorOffsetHig m0 : 4|1@1+ (1,0) [0|1] "" Vector__XXX
 SG_ DPB_a002_pMC2SensorOffsetHigh m0 : 5|1@1+ (1,0) [0|1] "" Vector__XXX
 SG_ DPB_a003_AswEEPROMReadFailure m0 : 6|1@1+ (1,0) [0|1] "" Vector__XXX
 SG_ DPB_a004_assertionFault m0 : 7|1@1+ (1,0) [0|1] "" Vector__XXX
 SG_ DPB_a005_hardPedalChar m0 : 8|1@1+ (1,0) [0|1] "" Vector__XXX
 SG_ DPB_a006_hardPedalCharGoodCheck m0 : 9|1@1+ (1,0) [0|1] "" Vector__XXX
 SG_ DPB_a007_PMCLeakageDetected m0 : 10|1@1+ (1,0) [0|1] "" Vector__XXX
 SG_ DPB_a008_LiPSPts1Offset m0 : 11|1@1+ (1,0) [0|1] "" Vector__XXX
 SG_ DPB_a009_LiPSPts2Offset m0 : 12|1@1+ (1,0) [0|1] "" Vector__XXX
 SG_ DPB_a010_LiPSPtsConsistency m0 : 13|1@1+ (1,0) [0|1] "" Vector__XXX
 SG_ DPB_a011_PtsNonZeroStage1 m0 : 14|1@1+ (1,0) [0|1] "" Vector__XXX
 SG_ DPB_a012_PtsNonZeroStage2 m0 : 15|1@1+ (1,0) [0|1] "" Vector__XXX
 SG_ DPB_a013_softPedalChar m0 : 16|1@1+ (1,0) [0|1] "" Vector__XXX
 SG_ DPB_a014_CANControllerHWFault m0 : 17|1@1+ (1,0) [0|1] "" Vector__XXX
 SG_ DPB_a015_CAN1BusOff m0 : 18|1@1+ (1,0) [0|1] "" Vector__XXX
 SG_ DPB_a016_CAN2BusOff m0 : 19|1@1+ (1,0) [0|1] "" Vector__XXX
 SG_ DPB_a017_largeLeakageDetected m0 : 20|1@1+ (1,0) [0|1] "" Vector__XXX
 SG_ DPB_a018_largeLeakageDetectedGoo m0 : 21|1@1+ (1,0) [0|1] "" Vector__XXX
 SG_ DPB_a019_DETReportError m0 : 22|1@1+ (1,0) [0|1] "" Vector__XXX
 SG_ DPB_a020_ecuHuMismatch m0 : 23|1@1+ (1,0) [0|1] "" Vector__XXX
 SG_ DPB_a021_brakeSystemOverheatLvl1 m0 : 24|1@1+ (1,0) [0|1] "" Vector__XXX
 SG_ DPB_a022_brakeSystemOverheatLvl2 m0 : 25|1@1+ (1,0) [0|1] "" Vector__XXX
 SG_ DPB_a023_initialPlungerCheckFail m0 : 26|1@1+ (1,0) [0|1] "" Vector__XXX
 SG_ DPB_a024_ESPLDMFailure m0 : 27|1@1+ (1,0) [0|1] "" Vector__XXX
 SG_ DPB_a025_backupCircuitLeakage m0 : 28|1@1+ (1,0) [0|1] "" Vector__XXX
 SG_ DPB_a026_LiPSIDTimeout m0 : 29|1@1+ (1,0) [0|1] "" Vector__XXX
 SG_ DPB_a027_motorTempHighLevel1 m0 : 30|1@1+ (1,0) [0|1] "" Vector__XXX
 SG_ DPB_a028_motorTempHighLevel2 m0 : 31|1@1+ (1,0) [0|1] "" Vector__XXX
 SG_ DPB_a029_motorTestFault m0 : 32|1@1+ (1,0) [0|1] "" Vector__XXX
 SG_ DPB_a030_notShutDownRight m0 : 33|1@1+ (1,0) [0|1] "" Vector__XXX
 SG_ DPB_a031_HWParamReadFailed m0 : 34|1@1+ (1,0) [0|1] "" Vector__XXX
 SG_ DPB_a032_HWParamWriteFailed m0 : 35|1@1+ (1,0) [0|1] "" Vector__XXX
 SG_ DPB_a033_motorDynamicLimited m0 : 36|1@1+ (1,0) [0|1] "" Vector__XXX
 SG_ DPB_a034_lipsMemoryEmpty m0 : 37|1@1+ (1,0) [0|1] "" Vector__XXX
 SG_ DPB_a035_PDURouterinitialization m0 : 38|1@1+ (1,0) [0|1] "" Vector__XXX
 SG_ DPB_a036_lossOfPDUInstanceDetect m0 : 39|1@1+ (1,0) [0|1] "" Vector__XXX
 SG_ DPB_a037_plungerCircuitPressHigh m0 : 40|1@1+ (1,0) [0|1] "" Vector__XXX
 SG_ DPB_a038_plungerCircuitPressHigh m0 : 41|1@1+ (1,0) [0|1] "" Vector__XXX
 SG_ DPB_a039_plungerCircuitPressLow m0 : 42|1@1+ (1,0) [0|1] "" Vector__XXX
 SG_ DPB_a040_plungerCircuitPressLowG m0 : 43|1@1+ (1,0) [0|1] "" Vector__XXX
 SG_ DPB_a041_PSCGearRatioReadFault m0 : 44|1@1+ (1,0) [0|1] "" Vector__XXX
 SG_ DPB_a042_motorLoadPressImplausib m0 : 45|1@1+ (1,0) [0|1] "" Vector__XXX
 SG_ DPB_a043_PSCMotorSizeReadFault m0 : 46|1@1+ (1,0) [0|1] "" Vector__XXX
 SG_ DPB_a044_supplyOvervoltageLvl1 m0 : 47|1@1+ (1,0) [0|1] "" Vector__XXX
 SG_ DPB_a045_supplyOvervoltageLvl2 m0 : 48|1@1+ (1,0) [0|1] "" Vector__XXX
 SG_ DPB_a046_supplyOvervoltageLvl3 m0 : 49|1@1+ (1,0) [0|1] "" Vector__XXX
 SG_ DPB_a047_pPlungerPlausCheckFailu m0 : 50|1@1+ (1,0) [0|1] "" Vector__XXX
 SG_ DPB_a048_supplyUndervoltageLvl1 m0 : 51|1@1+ (1,0) [0|1] "" Vector__XXX
 SG_ DPB_a049_supplyUndervoltageLvl2 m0 : 52|1@1+ (1,0) [0|1] "" Vector__XXX
 SG_ DPB_a050_supplyUndervoltageLvl3 m0 : 53|1@1+ (1,0) [0|1] "" Vector__XXX
 SG_ DPB_a051_PSCVoltageImplausible m0 : 54|1@1+ (1,0) [0|1] "" Vector__XXX
 SG_ DPB_a052_PSIDTimeOut m0 : 55|1@1+ (1,0) [0|1] "" Vector__XXX
 SG_ DPB_a053_hydraulicAssemblyModeAc m0 : 56|1@1+ (1,0) [0|1] "" Vector__XXX
 SG_ DPB_a054_unsupportedHW m0 : 57|1@1+ (1,0) [0|1] "" Vector__XXX
 SG_ DPB_a055_unsupportedSeriesHWDete m0 : 58|1@1+ (1,0) [0|1] "" Vector__XXX
 SG_ DPB_a056_AdcPeripheralFault m0 : 59|1@1+ (1,0) [0|1] "" Vector__XXX
 SG_ DPB_a057_AdcPinTest m0 : 60|1@1+ (1,0) [0|1] "" Vector__XXX
 SG_ DPB_a058_AdcSelftestC5P m0 : 61|1@1+ (1,0) [0|1] "" Vector__XXX
 SG_ DPB_a059_factoryModeActive m0 : 62|1@1+ (1,0) [0|1] "" Vector__XXX
 SG_ DPB_a060_motorBridgeDriverFault m0 : 63|1@1+ (1,0) [0|1] "" Vector__XXX
 SG_ DPB_a061_bridgeSwitchInitError m1 : 4|1@1+ (1,0) [0|1] "" Vector__XXX
 SG_ DPB_a062_loadDumpOnFSLTest m1 : 5|1@1+ (1,0) [0|1] "" Vector__XXX
 SG_ DPB_a063_motorConfigMismatch m1 : 6|1@1+ (1,0) [0|1] "" Vector__XXX
 SG_ DPB_a064_current1OffsetHigh m1 : 7|1@1+ (1,0) [0|1] "" Vector__XXX
 SG_ DPB_a065_current1OffsetLow m1 : 8|1@1+ (1,0) [0|1] "" Vector__XXX
 SG_ DPB_a066_current2OffsetHigh m1 : 9|1@1+ (1,0) [0|1] "" Vector__XXX
 SG_ DPB_a067_current2OffsetLow m1 : 10|1@1+ (1,0) [0|1] "" Vector__XXX
 SG_ DPB_a068_BLMMuxerTimeoutError m1 : 11|1@1+ (1,0) [0|1] "" Vector__XXX
 SG_ DPB_a069_OBDCurrent1OORHigh m1 : 12|1@1+ (1,0) [0|1] "" Vector__XXX
 SG_ DPB_a070_OBDCurrent1OORLow m1 : 13|1@1+ (1,0) [0|1] "" Vector__XXX
 SG_ DPB_a071_OBDCurrent2OORHigh m1 : 14|1@1+ (1,0) [0|1] "" Vector__XXX
 SG_ DPB_a072_OBDCurrent2OORLow m1 : 15|1@1+ (1,0) [0|1] "" Vector__XXX
 SG_ DPB_a073_rotorCosOutOfRangeHigh m1 : 16|1@1+ (1,0) [0|1] "" Vector__XXX
 SG_ DPB_a074_rotorCosOutOfRangeLow m1 : 17|1@1+ (1,0) [0|1] "" Vector__XXX
 SG_ DPB_a075_rotorSinOutOfRangeHigh m1 : 18|1@1+ (1,0) [0|1] "" Vector__XXX
 SG_ DPB_a076_rotorSinOutOfRangeLow m1 : 19|1@1+ (1,0) [0|1] "" Vector__XXX
 SG_ DPB_a077_tempSens1ShortToSupply m1 : 20|1@1+ (1,0) [0|1] "" Vector__XXX
 SG_ DPB_a078_tempSens1ShortToGround m1 : 21|1@1+ (1,0) [0|1] "" Vector__XXX
 SG_ DPB_a079_tempSens2ShortToSupply m1 : 22|1@1+ (1,0) [0|1] "" Vector__XXX
 SG_ DPB_a080_tempSens2ShortToGround m1 : 23|1@1+ (1,0) [0|1] "" Vector__XXX
 SG_ DPB_a081_tempSensImplausVoltage m1 : 24|1@1+ (1,0) [0|1] "" Vector__XXX
 SG_ DPB_a082_chargePumpFault m1 : 25|1@1+ (1,0) [0|1] "" Vector__XXX
 SG_ DPB_a083_chargePumpUndervoltage m1 : 26|1@1+ (1,0) [0|1] "" Vector__XXX
 SG_ DPB_a084_RBCPUException m1 : 27|1@1+ (1,0) [0|1] "" Vector__XXX
 SG_ DPB_a085_infoFailureWrongCUBASHa m1 : 28|1@1+ (1,0) [0|1] "" Vector__XXX
 SG_ DPB_a086_diagHydProtectionPressF m1 : 29|1@1+ (1,0) [0|1] "" Vector__XXX
 SG_ DPB_a087_diagHydProtectionVlvFau m1 : 30|1@1+ (1,0) [0|1] "" Vector__XXX
 SG_ DPB_a088_DMATransferError m1 : 31|1@1+ (1,0) [0|1] "" Vector__XXX
 SG_ DPB_a089_ecuBandgap m1 : 32|1@1+ (1,0) [0|1] "" Vector__XXX
 SG_ DPB_a090_flashFault m1 : 33|1@1+ (1,0) [0|1] "" Vector__XXX
 SG_ DPB_a091_MRGPathTestFault m1 : 34|1@1+ (1,0) [0|1] "" Vector__XXX
 SG_ DPB_a092_decoupleBitTestFault m1 : 35|1@1+ (1,0) [0|1] "" Vector__XXX
 SG_ DPB_a093_ecuBistFaultCtrFault m1 : 36|1@1+ (1,0) [0|1] "" Vector__XXX
 SG_ DPB_a094_ecuClockTestFault m1 : 37|1@1+ (1,0) [0|1] "" Vector__XXX
 SG_ DPB_a095_ecuEnableElHighFault m1 : 38|1@1+ (1,0) [0|1] "" Vector__XXX
 SG_ DPB_a096_ecuEnableElLowFault m1 : 39|1@1+ (1,0) [0|1] "" Vector__XXX
 SG_ DPB_a097_ecuEnableHyHighFault m1 : 40|1@1+ (1,0) [0|1] "" Vector__XXX
 SG_ DPB_a098_ecuEnableHyLowFault m1 : 41|1@1+ (1,0) [0|1] "" Vector__XXX
 SG_ DPB_a099_ecuEnContinuousError m1 : 42|1@1+ (1,0) [0|1] "" Vector__XXX
 SG_ DPB_a100_ecuErrpinCounterFault m1 : 43|1@1+ (1,0) [0|1] "" Vector__XXX
 SG_ DPB_a101_ecuFastWdTestFault m1 : 44|1@1+ (1,0) [0|1] "" Vector__XXX
 SG_ DPB_a102_ecuVrOnWhileWdTimeout m1 : 45|1@1+ (1,0) [0|1] "" Vector__XXX
 SG_ DPB_a103_ecuVrViaSpiFails m1 : 46|1@1+ (1,0) [0|1] "" Vector__XXX
 SG_ DPB_a104_ecuWdStartuptestFault m1 : 47|1@1+ (1,0) [0|1] "" Vector__XXX
 SG_ DPB_a105_ecuWdSContinuousError m1 : 48|1@1+ (1,0) [0|1] "" Vector__XXX
 SG_ DPB_a106_ecuBistCmdTestFault m1 : 49|1@1+ (1,0) [0|1] "" Vector__XXX
 SG_ DPB_a107_vrOnFails m1 : 50|1@1+ (1,0) [0|1] "" Vector__XXX
 SG_ DPB_a108_GTMRefFrequencyError m1 : 51|1@1+ (1,0) [0|1] "" Vector__XXX
 SG_ DPB_a109_GTMTbuMonError m1 : 52|1@1+ (1,0) [0|1] "" Vector__XXX
 SG_ DPB_a110_HWBISTError m1 : 53|1@1+ (1,0) [0|1] "" Vector__XXX
 SG_ DPB_a111_hydraulicHardUndervolta m1 : 54|1@1+ (1,0) [0|1] "" Vector__XXX
 SG_ DPB_a112_hydraulicUndervoltage m1 : 55|1@1+ (1,0) [0|1] "" Vector__XXX
 SG_ DPB_a113_LiPS1SentLineHigh m1 : 56|1@1+ (1,0) [0|1] "" Vector__XXX
 SG_ DPB_a114_LiPS1SentLineLow m1 : 57|1@1+ (1,0) [0|1] "" Vector__XXX
 SG_ DPB_a115_LiPS1SentSensor m1 : 58|1@1+ (1,0) [0|1] "" Vector__XXX
 SG_ DPB_a116_LiPS1SentTransmission m1 : 59|1@1+ (1,0) [0|1] "" Vector__XXX
 SG_ DPB_a117_LiPS2PwmLineHigh m1 : 60|1@1+ (1,0) [0|1] "" Vector__XXX
 SG_ DPB_a118_LiPS2PwmLineLow m1 : 61|1@1+ (1,0) [0|1] "" Vector__XXX
 SG_ DPB_a119_LiPS2PwmTransmission m1 : 62|1@1+ (1,0) [0|1] "" Vector__XXX
 SG_ DPB_a120_LiPSOutOfRangeHigh m1 : 63|1@1+ (1,0) [0|1] "" Vector__XXX
 SG_ DPB_a121_LiPSOutOfRangeLow m2 : 4|1@1+ (1,0) [0|1] "" Vector__XXX
 SG_ DPB_a122_micAsicClkInError m2 : 5|1@1+ (1,0) [0|1] "" Vector__XXX
 SG_ DPB_a123_micAsicInitTestError m2 : 6|1@1+ (1,0) [0|1] "" Vector__XXX
 SG_ DPB_a124_asicOscillatorError m2 : 7|1@1+ (1,0) [0|1] "" Vector__XXX
 SG_ DPB_a125_B6AsicFault m2 : 8|1@1+ (1,0) [0|1] "" Vector__XXX
 SG_ DPB_a126_MICB6TransferError m2 : 9|1@1+ (1,0) [0|1] "" Vector__XXX
 SG_ DPB_a127_hydraulicAsicShortCircu m2 : 10|1@1+ (1,0) [0|1] "" Vector__XXX
 SG_ DPB_a128_micSpiTransferError m2 : 11|1@1+ (1,0) [0|1] "" Vector__XXX
 SG_ DPB_a129_AsicTrimmingNotComplete m2 : 12|1@1+ (1,0) [0|1] "" Vector__XXX
 SG_ DPB_a130_AsicMalfunctionDetected m2 : 13|1@1+ (1,0) [0|1] "" Vector__XXX
 SG_ DPB_a131_ASICOvercurrentOnGPIO25 m2 : 14|1@1+ (1,0) [0|1] "" Vector__XXX
 SG_ DPB_a132_ASICOvercurrentOnGPIO25 m2 : 15|1@1+ (1,0) [0|1] "" Vector__XXX
 SG_ DPB_a133_ASICOvercurrentOnGPIO50 m2 : 16|1@1+ (1,0) [0|1] "" Vector__XXX
 SG_ DPB_a134_ASICOvercurrentOnGPIO50 m2 : 17|1@1+ (1,0) [0|1] "" Vector__XXX
 SG_ DPB_a135_ASICOvercurrentOnGPIO50 m2 : 18|1@1+ (1,0) [0|1] "" Vector__XXX
 SG_ DPB_a136_ASICOvercurrentOnGPIO50 m2 : 19|1@1+ (1,0) [0|1] "" Vector__XXX
 SG_ DPB_a137_ASICOvercurrentOnWRHS m2 : 20|1@1+ (1,0) [0|1] "" Vector__XXX
 SG_ DPB_a138_DIchassisControlCounter m2 : 21|1@1+ (1,0) [0|1] "" Vector__XXX
 SG_ DPB_a139_DIchassisControlChecksu m2 : 22|1@1+ (1,0) [0|1] "" Vector__XXX
 SG_ DPB_a140_DIchassisControlDLC m2 : 23|1@1+ (1,0) [0|1] "" Vector__XXX
 SG_ DPB_a141_DIchassisControlTimeout m2 : 24|1@1+ (1,0) [0|1] "" Vector__XXX
 SG_ DPB_a142_DIsystemStatusCounter m2 : 25|1@1+ (1,0) [0|1] "" Vector__XXX
 SG_ DPB_a143_DIsystemStatusChecksum m2 : 26|1@1+ (1,0) [0|1] "" Vector__XXX
 SG_ DPB_a144_DIsystemStatusDLC m2 : 27|1@1+ (1,0) [0|1] "" Vector__XXX
 SG_ DPB_a145_DIsystemStatusTimeout m2 : 28|1@1+ (1,0) [0|1] "" Vector__XXX
 SG_ DPB_a146_DIFtorqueCounter m2 : 29|1@1+ (1,0) [0|1] "" Vector__XXX
 SG_ DPB_a147_DIFtorqueChecksum m2 : 30|1@1+ (1,0) [0|1] "" Vector__XXX
 SG_ DPB_a148_DIFtorqueDLC m2 : 31|1@1+ (1,0) [0|1] "" Vector__XXX
 SG_ DPB_a149_DIFtorqueTimeout m2 : 32|1@1+ (1,0) [0|1] "" Vector__XXX
 SG_ DPB_a150_DIRtorqueCounter m2 : 33|1@1+ (1,0) [0|1] "" Vector__XXX
 SG_ DPB_a151_DIRtorqueChecksum m2 : 34|1@1+ (1,0) [0|1] "" Vector__XXX
 SG_ DPB_a152_DIRtorqueDLC m2 : 35|1@1+ (1,0) [0|1] "" Vector__XXX
 SG_ DPB_a153_DIRtorqueTimeout m2 : 36|1@1+ (1,0) [0|1] "" Vector__XXX
 SG_ DPB_a154_EPBLstatusCounter m2 : 37|1@1+ (1,0) [0|1] "" Vector__XXX
 SG_ DPB_a155_EPBLstatusChecksum m2 : 38|1@1+ (1,0) [0|1] "" Vector__XXX
 SG_ DPB_a156_EPBLstatusDLC m2 : 39|1@1+ (1,0) [0|1] "" Vector__XXX
 SG_ DPB_a157_EPBLstatusTimeout m2 : 40|1@1+ (1,0) [0|1] "" Vector__XXX
 SG_ DPB_a158_EPBRstatusCounter m2 : 41|1@1+ (1,0) [0|1] "" Vector__XXX
 SG_ DPB_a159_EPBRstatusChecksum m2 : 42|1@1+ (1,0) [0|1] "" Vector__XXX
 SG_ DPB_a160_EPBRstatusDLC m2 : 43|1@1+ (1,0) [0|1] "" Vector__XXX
 SG_ DPB_a161_EPBRstatusTimeout m2 : 44|1@1+ (1,0) [0|1] "" Vector__XXX
 SG_ DPB_a162_ESP_modulator1Counter m2 : 45|1@1+ (1,0) [0|1] "" Vector__XXX
 SG_ DPB_a163_ESP_modulator1Checksum m2 : 46|1@1+ (1,0) [0|1] "" Vector__XXX
 SG_ DPB_a164_ESP_modulator1DLC m2 : 47|1@1+ (1,0) [0|1] "" Vector__XXX
 SG_ DPB_a165_ESP_modulator1Timeout m2 : 48|1@1+ (1,0) [0|1] "" Vector__XXX
 SG_ DPB_a166_ESP_chassis3Counter m2 : 49|1@1+ (1,0) [0|1] "" Vector__XXX
 SG_ DPB_a167_ESP_chassis3Checksum m2 : 50|1@1+ (1,0) [0|1] "" Vector__XXX
 SG_ DPB_a168_ESP_chassis3DLC m2 : 51|1@1+ (1,0) [0|1] "" Vector__XXX
 SG_ DPB_a169_ESP_chassis3Timeout m2 : 52|1@1+ (1,0) [0|1] "" Vector__XXX
 SG_ DPB_a170_ESP_modulator2Counter m2 : 53|1@1+ (1,0) [0|1] "" Vector__XXX
 SG_ DPB_a171_ESP_modulator2Checksum m2 : 54|1@1+ (1,0) [0|1] "" Vector__XXX
 SG_ DPB_a172_ESP_modulator2DLC m2 : 55|1@1+ (1,0) [0|1] "" Vector__XXX
 SG_ DPB_a173_ESP_modulator2Timeout m2 : 56|1@1+ (1,0) [0|1] "" Vector__XXX
 SG_ DPB_a174_ESP_modulator3Counter m2 : 57|1@1+ (1,0) [0|1] "" Vector__XXX
 SG_ DPB_a175_ESP_modulator3Checksum m2 : 58|1@1+ (1,0) [0|1] "" Vector__XXX
 SG_ DPB_a176_ESP_modulator3DLC m2 : 59|1@1+ (1,0) [0|1] "" Vector__XXX
 SG_ DPB_a177_ESP_modulator3Timeout m2 : 60|1@1+ (1,0) [0|1] "" Vector__XXX
 SG_ DPB_a178_PMstate2Counter m2 : 61|1@1+ (1,0) [0|1] "" Vector__XXX
 SG_ DPB_a179_PMstate2Checksum m2 : 62|1@1+ (1,0) [0|1] "" Vector__XXX
 SG_ DPB_a180_PMstate2DLC m2 : 63|1@1+ (1,0) [0|1] "" Vector__XXX
 SG_ DPB_a181_PMstate2Timeout m3 : 4|1@1+ (1,0) [0|1] "" Vector__XXX
 SG_ DPB_a182_RCMInertial2Counter m3 : 5|1@1+ (1,0) [0|1] "" Vector__XXX
 SG_ DPB_a183_RCMInertial2Checksum m3 : 6|1@1+ (1,0) [0|1] "" Vector__XXX
 SG_ DPB_a184_RCMInertial2DLC m3 : 7|1@1+ (1,0) [0|1] "" Vector__XXX
 SG_ DPB_a185_RCMInertial2Timeout m3 : 8|1@1+ (1,0) [0|1] "" Vector__XXX
 SG_ DPB_a186_LVPowerStateTimeout m3 : 9|1@1+ (1,0) [0|1] "" Vector__XXX
 SG_ DPB_a187_LVPowerStateChecksum m3 : 10|1@1+ (1,0) [0|1] "" Vector__XXX
 SG_ DPB_a188_LVPowerStateDLC m3 : 11|1@1+ (1,0) [0|1] "" Vector__XXX
 SG_ DPB_a189_LVPowerStateCounter m3 : 12|1@1+ (1,0) [0|1] "" Vector__XXX
 SG_ DPB_a190_VCLEFTepbmStatusCounter m3 : 13|1@1+ (1,0) [0|1] "" Vector__XXX
 SG_ DPB_a191_VCLEFTepbmStatusChecksu m3 : 14|1@1+ (1,0) [0|1] "" Vector__XXX
 SG_ DPB_a192_VCLEFTepbmStatusDLC m3 : 15|1@1+ (1,0) [0|1] "" Vector__XXX
 SG_ DPB_a193_VCLEFTepbmStatusTimeout m3 : 16|1@1+ (1,0) [0|1] "" Vector__XXX
 SG_ DPB_a194_VCRIGHTepbmStatusCounte m3 : 17|1@1+ (1,0) [0|1] "" Vector__XXX
 SG_ DPB_a195_VCRIGHTepbmStatusChecks m3 : 18|1@1+ (1,0) [0|1] "" Vector__XXX
 SG_ DPB_a196_VCRIGHTepbmStatusDLC m3 : 19|1@1+ (1,0) [0|1] "" Vector__XXX
 SG_ DPB_a197_VCRIGHTepbmStatusTimeou m3 : 20|1@1+ (1,0) [0|1] "" Vector__XXX
 SG_ DPB_a198_CANOvervoltage m3 : 21|1@1+ (1,0) [0|1] "" Vector__XXX
 SG_ DPB_a199_pMC1QFaulty m3 : 22|1@1+ (1,0) [0|1] "" Vector__XXX
 SG_ DPB_a200_ESPRunoutSupportNotAvai m3 : 23|1@1+ (1,0) [0|1] "" Vector__XXX
 SG_ DPB_a201_vehicleSpeedQFaulty m3 : 24|1@1+ (1,0) [0|1] "" Vector__XXX
 SG_ DPB_a202_vehicleStandstillQFault m3 : 25|1@1+ (1,0) [0|1] "" Vector__XXX
 SG_ DPB_a203_ABSNotAvailable m3 : 26|1@1+ (1,0) [0|1] "" Vector__XXX
 SG_ DPB_a204_CANUndervoltage m3 : 27|1@1+ (1,0) [0|1] "" Vector__XXX
 SG_ DPB_a205_NvMWriteCycleExceed m3 : 28|1@1+ (1,0) [0|1] "" Vector__XXX
 SG_ DPB_a206_OSTaskSchemeError m3 : 29|1@1+ (1,0) [0|1] "" Vector__XXX
 SG_ DPB_a207_hydraulicOvervoltage m3 : 30|1@1+ (1,0) [0|1] "" Vector__XXX
 SG_ DPB_a208_pressureSensor1Short m3 : 31|1@1+ (1,0) [0|1] "" Vector__XXX
 SG_ DPB_a209_pressureSensor1High m3 : 32|1@1+ (1,0) [0|1] "" Vector__XXX
 SG_ DPB_a210_pressureSensor1Low m3 : 33|1@1+ (1,0) [0|1] "" Vector__XXX
 SG_ DPB_a211_pressureSensor1Fault m3 : 34|1@1+ (1,0) [0|1] "" Vector__XXX
 SG_ DPB_a212_pressureSensor1Temp m3 : 35|1@1+ (1,0) [0|1] "" Vector__XXX
 SG_ DPB_a213_pressureSensor1Fault m3 : 36|1@1+ (1,0) [0|1] "" Vector__XXX
 SG_ DPB_a214_pressureSensor2Short m3 : 37|1@1+ (1,0) [0|1] "" Vector__XXX
 SG_ DPB_a215_pressureSensor2High m3 : 38|1@1+ (1,0) [0|1] "" Vector__XXX
 SG_ DPB_a216_pressureSensor2Low m3 : 39|1@1+ (1,0) [0|1] "" Vector__XXX
 SG_ DPB_a217_pressureSensor2Fault m3 : 40|1@1+ (1,0) [0|1] "" Vector__XXX
 SG_ DPB_a218_pressureSensor2Temp m3 : 41|1@1+ (1,0) [0|1] "" Vector__XXX
 SG_ DPB_a219_pressureSensor2Fault m3 : 42|1@1+ (1,0) [0|1] "" Vector__XXX
 SG_ DPB_a220_excessiveBoostWakeupsDe m3 : 43|1@1+ (1,0) [0|1] "" Vector__XXX
 SG_ DPB_a221_notShutdownRight m3 : 44|1@1+ (1,0) [0|1] "" Vector__XXX
 SG_ DPB_a222_excessiveEcuResetsDetec m3 : 45|1@1+ (1,0) [0|1] "" Vector__XXX
 SG_ DPB_a223_RAMFault m3 : 46|1@1+ (1,0) [0|1] "" Vector__XXX
 SG_ DPB_a224_brakeBoostLost m3 : 47|1@1+ (1,0) [0|1] "" Vector__XXX
 SG_ DPB_a225_U5VOutOfRange m3 : 48|1@1+ (1,0) [0|1] "" Vector__XXX
 SG_ DPB_a226_U5VTestFault m3 : 49|1@1+ (1,0) [0|1] "" Vector__XXX
 SG_ DPB_a227_brakeFluidLoss m3 : 50|1@1+ (1,0) [0|1] "" Vector__XXX
 SG_ DPB_a228_supplyASICInitFault m3 : 51|1@1+ (1,0) [0|1] "" Vector__XXX
 SG_ DPB_a229_IREFOutOfRange m3 : 52|1@1+ (1,0) [0|1] "" Vector__XXX
 SG_ DPB_a230_OSErrorHook m3 : 53|1@1+ (1,0) [0|1] "" Vector__XXX
 SG_ DPB_a231_stackOverUnderFlow m3 : 54|1@1+ (1,0) [0|1] "" Vector__XXX
 SG_ DPB_a232_systemErrorHook m3 : 55|1@1+ (1,0) [0|1] "" Vector__XXX
 SG_ DPB_a233_systemTaskJitter m3 : 56|1@1+ (1,0) [0|1] "" Vector__XXX
 SG_ DPB_a234_systemTaskOverRun m3 : 57|1@1+ (1,0) [0|1] "" Vector__XXX
 SG_ DPB_a235_UB6PlausiMonFault m3 : 58|1@1+ (1,0) [0|1] "" Vector__XXX
 SG_ DPB_a236_UB6SupplyPathFault m3 : 59|1@1+ (1,0) [0|1] "" Vector__XXX
 SG_ DPB_a237_uCVoltageDividerDrift m3 : 60|1@1+ (1,0) [0|1] "" Vector__XXX
 SG_ DPB_a238_microRegisterFault m3 : 61|1@1+ (1,0) [0|1] "" Vector__XXX
 SG_ DPB_a239_microSafetyFault m3 : 62|1@1+ (1,0) [0|1] "" Vector__XXX
 SG_ DPB_a240_microSafetyLogicFault m3 : 63|1@1+ (1,0) [0|1] "" Vector__XXX
 SG_ DPB_a241_uCSafetyNotification m4 : 4|1@1+ (1,0) [0|1] "" Vector__XXX
 SG_ DPB_a242_uCSafetyNotificationGRA m4 : 5|1@1+ (1,0) [0|1] "" Vector__XXX
 SG_ DPB_a243_microSupplyError m4 : 6|1@1+ (1,0) [0|1] "" Vector__XXX
 SG_ DPB_a244_valvesGenericFault m4 : 7|1@1+ (1,0) [0|1] "" Vector__XXX
 SG_ DPB_a245_valveMV0Fault m4 : 8|1@1+ (1,0) [0|1] "" Vector__XXX
 SG_ DPB_a246_valveMV5Fault m4 : 9|1@1+ (1,0) [0|1] "" Vector__XXX
 SG_ DPB_a247_valveMV6Fault m4 : 10|1@1+ (1,0) [0|1] "" Vector__XXX
 SG_ DPB_a248_valveMV61Fault m4 : 11|1@1+ (1,0) [0|1] "" Vector__XXX
 SG_ DPB_a249_valveMV62Fault m4 : 12|1@1+ (1,0) [0|1] "" Vector__XXX
 SG_ DPB_a250_valveMV7Fault m4 : 13|1@1+ (1,0) [0|1] "" Vector__XXX
 SG_ DPB_a251_valveMV8Fault m4 : 14|1@1+ (1,0) [0|1] "" Vector__XXX
 SG_ DPB_a252_valveMV81Fault m4 : 15|1@1+ (1,0) [0|1] "" Vector__XXX
 SG_ DPB_a253_valveMV82Fault m4 : 16|1@1+ (1,0) [0|1] "" Vector__XXX
 SG_ DPB_a254_valveMV9Fault m4 : 17|1@1+ (1,0) [0|1] "" Vector__XXX
 SG_ DPB_a255_valveRelayShort m4 : 18|1@1+ (1,0) [0|1] "" Vector__XXX
 SG_ DPB_a256_valveRelayActuationFaul m4 : 19|1@1+ (1,0) [0|1] "" Vector__XXX
 SG_ DPB_a257_valveRelayOnContinuous m4 : 20|1@1+ (1,0) [0|1] "" Vector__XXX
 SG_ DPB_a258_valveRelayOffContinuous m4 : 21|1@1+ (1,0) [0|1] "" Vector__XXX
 SG_ DPB_a259_valveRelayTestUndervolt m4 : 22|1@1+ (1,0) [0|1] "" Vector__XXX
 SG_ DPB_a260_valveRelaySafetySwitchF m4 : 23|1@1+ (1,0) [0|1] "" Vector__XXX
 SG_ DPB_a261_WdhAsicWdCmdMissing m4 : 24|1@1+ (1,0) [0|1] "" Vector__XXX
 SG_ DPB_a262_WdhAsicWdErrorCntLimit m4 : 25|1@1+ (1,0) [0|1] "" Vector__XXX
 SG_ DPB_a263_WdhAsicWdErrorCntStuck m4 : 26|1@1+ (1,0) [0|1] "" Vector__XXX
 SG_ DPB_a264_WdhSwBistConCnt m4 : 27|1@1+ (1,0) [0|1] "" Vector__XXX
 SG_ DPB_a265_WdhTaskMonConCnt m4 : 28|1@1+ (1,0) [0|1] "" Vector__XXX
 SG_ DPB_a266_RPSNvMReadFault m4 : 29|1@1+ (1,0) [0|1] "" Vector__XXX
 SG_ DPB_a267_RpsAngleImplausible m4 : 30|1@1+ (1,0) [0|1] "" Vector__XXX
 SG_ DPB_a268_RPSVectorOscillating m4 : 31|1@1+ (1,0) [0|1] "" Vector__XXX
 SG_ DPB_a269_RPSVectorRangeHigh m4 : 32|1@1+ (1,0) [0|1] "" Vector__XXX
 SG_ DPB_a270_RPSVectorRangeLow m4 : 33|1@1+ (1,0) [0|1] "" Vector__XXX
 SG_ DPB_a271_RPSWrongCalibData m4 : 34|1@1+ (1,0) [0|1] "" Vector__XXX
 SG_ DPB_a272_runtimeAssertionFault m4 : 35|1@1+ (1,0) [0|1] "" Vector__XXX
 SG_ DPB_a273_SMMOneRequestsInit m4 : 36|1@1+ (1,0) [0|1] "" Vector__XXX
 SG_ DPB_a274_AswSystemTimeOut m4 : 37|1@1+ (1,0) [0|1] "" Vector__XXX
 SG_ DPB_a275_Ps1Ps2PlausibilityFault m4 : 38|1@1+ (1,0) [0|1] "" Vector__XXX
 SG_ DPB_a276_VCFRONTsensorsCounter m4 : 39|1@1+ (1,0) [0|1] "" Vector__XXX
 SG_ DPB_a277_VCFRONTsensorsChecksum m4 : 40|1@1+ (1,0) [0|1] "" Vector__XXX
 SG_ DPB_a278_VCFRONTsensorsDLC m4 : 41|1@1+ (1,0) [0|1] "" Vector__XXX
 SG_ DPB_a279_VCFRONTsensorsTimeout m4 : 42|1@1+ (1,0) [0|1] "" Vector__XXX
 SG_ DPB_a280_LowBrakeFluid m4 : 43|1@1+ (1,0) [0|1] "" Vector__XXX
 SG_ DPB_a281_brakeFluidOORHigh m4 : 44|1@1+ (1,0) [0|1] "" Vector__XXX
 SG_ DPB_a282_DIbrakeCommandCounter m4 : 45|1@1+ (1,0) [0|1] "" Vector__XXX
 SG_ DPB_a283_DIbrakeCommandChecksum m4 : 46|1@1+ (1,0) [0|1] "" Vector__XXX
 SG_ DPB_a284_DIbrakeCommandDLC m4 : 47|1@1+ (1,0) [0|1] "" Vector__XXX
 SG_ DPB_a285_DIbrakeCommandTimeout m4 : 48|1@1+ (1,0) [0|1] "" Vector__XXX
 SG_ DPB_a286_ebrCmdStateInvalid m4 : 49|1@1+ (1,0) [0|1] "" Vector__XXX
 SG_ DPB_a287_brakeCmdStateInvalid m4 : 50|1@1+ (1,0) [0|1] "" Vector__XXX
 SG_ DPB_a288_PlantDegradedSW m4 : 51|1@1+ (1,0) [0|1] "" Vector__XXX
 SG_ DPB_a289_evacFillNotComplete m4 : 52|1@1+ (1,0) [0|1] "" Vector__XXX
 SG_ DPB_a290_securityInfo m4 : 53|1@1+ (1,0) [0|1] "" Vector__XXX
 SG_ DPB_a291_extDBRRequestTooLow m4 : 54|1@1+ (1,0) [0|1] "" Vector__XXX
 SG_ DPB_a292_CBDS_fillBufferThreshol m4 : 55|1@1+ (1,0) [0|1] "" Vector__XXX
 SG_ DPB_a293_CBDS_fmeInternalEvent m4 : 56|1@1+ (1,0) [0|1] "" Vector__XXX
 SG_ DPB_a294_hbaNormalModeActive m4 : 57|1@1+ (1,0) [0|1] "" Vector__XXX
 SG_ DPB_a295_hbaTrackModeActive m4 : 58|1@1+ (1,0) [0|1] "" Vector__XXX
 SG_ DPB_a296_StatInvalid_DI_FullSNA m4 : 59|1@1+ (1,0) [0|1] "" Vector__XXX
 SG_ DPB_a297_undefinedAlertDetected m4 : 60|1@1+ (1,0) [0|1] "" Vector__XXX
 SG_ DPB_a298_runningPlungerCircuitTe m4 : 61|1@1+ (1,0) [0|1] "" Vector__XXX
 SG_ DPB_a299_PM_locStateCounter m4 : 62|1@1+ (1,0) [0|1] "" Vector__XXX
 SG_ DPB_a300_PM_locStateChecksum m4 : 63|1@1+ (1,0) [0|1] "" Vector__XXX
 SG_ DPB_a301_PM_locStateDLC m5 : 4|1@1+ (1,0) [0|1] "" Vector__XXX
 SG_ DPB_a302_PM_locStateTimeout m5 : 5|1@1+ (1,0) [0|1] "" Vector__XXX
 SG_ DPB_a303_actuatingDIFullTorqueCm m5 : 6|1@1+ (1,0) [0|1] "" Vector__XXX
 SG_ DPB_a304_actuatingDITorqueCmd m5 : 7|1@1+ (1,0) [0|1] "" Vector__XXX
 SG_ DPB_a305_DIbrakeTorqueCommandAnd m5 : 8|1@1+ (1,0) [0|1] "" Vector__XXX
 SG_ DPB_a306_actuatorFallbackBasicMa m5 : 9|1@1+ (1,0) [0|1] "" Vector__XXX
 SG_ DPB_a307_actuatorDegradedMap m5 : 10|1@1+ (1,0) [0|1] "" Vector__XXX
 SG_ DPB_a308_backupMode m5 : 11|1@1+ (1,0) [0|1] "" Vector__XXX
 SG_ DPB_a309_DIFAxleTorqueInvalid m5 : 12|1@1+ (1,0) [0|1] "" Vector__XXX
 SG_ DPB_a310_DIRAxleTorqueInvalid m5 : 13|1@1+ (1,0) [0|1] "" Vector__XXX
 SG_ DPB_a311_postrunDurationTooLong m5 : 14|1@1+ (1,0) [0|1] "" Vector__XXX
 SG_ DPB_a312_continuouslyActivatedVa m5 : 15|1@1+ (1,0) [0|1] "" Vector__XXX
 SG_ DPB_a313_qualifiedBrakeEventDete m5 : 16|1@1+ (1,0) [0|1] "" Vector__XXX
 SG_ DPB_a314_runningCyclicVolumeChec m5 : 17|1@1+ (1,0) [0|1] "" Vector__XXX
 SG_ DPB_a315_runningLeakageAndAirMon m5 : 18|1@1+ (1,0) [0|1] "" Vector__XXX
 SG_ DPB_a316_lowBrakeFluidDetectedOn m5 : 19|1@1+ (1,0) [0|1] "" Vector__XXX
 SG_ DPB_a317_DASredundantBrakingCont m5 : 20|1@1+ (1,0) [0|1] "" Vector__XXX
 SG_ DPB_a318_DASredundantBrakingCont m5 : 21|1@1+ (1,0) [0|1] "" Vector__XXX
 SG_ DPB_a319_DASredundantBrakingCont m5 : 22|1@1+ (1,0) [0|1] "" Vector__XXX
 SG_ DPB_a320_DASredundantBrakingCont m5 : 23|1@1+ (1,0) [0|1] "" Vector__XXX
 SG_ DPB_a321_DASredundantBrakingCont m5 : 24|1@1+ (1,0) [0|1] "" Vector__XXX
 SG_ DPB_a322_DASredundantBrakingCont m5 : 25|1@1+ (1,0) [0|1] "" Vector__XXX
 SG_ DPB_a323_DASredundantBrakingCont m5 : 26|1@1+ (1,0) [0|1] "" Vector__XXX
 SG_ DPB_a324_DASredundantBrakingCont m5 : 27|1@1+ (1,0) [0|1] "" Vector__XXX
 SG_ DPB_a325_DIlocStatus2Checksum m5 : 28|1@1+ (1,0) [0|1] "" Vector__XXX
 SG_ DPB_a326_DIlocStatus2Counter m5 : 29|1@1+ (1,0) [0|1] "" Vector__XXX
 SG_ DPB_a327_DIlocStatus2DLC m5 : 30|1@1+ (1,0) [0|1] "" Vector__XXX
 SG_ DPB_a328_DIlocStatus2Timeout m5 : 31|1@1+ (1,0) [0|1] "" Vector__XXX
 SG_ DPB_a329_standaloneEBRActive m5 : 32|1@1+ (1,0) [0|1] "" Vector__XXX
 SG_ DPB_a330_EMCMain11Checksum m5 : 33|1@1+ (1,0) [0|1] "" Vector__XXX
 SG_ DPB_a331_EMCMain11Counter m5 : 34|1@1+ (1,0) [0|1] "" Vector__XXX
 SG_ DPB_a332_EMCMain11DLC m5 : 35|1@1+ (1,0) [0|1] "" Vector__XXX
 SG_ DPB_a333_EMCMain11Timeout m5 : 36|1@1+ (1,0) [0|1] "" Vector__XXX
 SG_ DPB_a334_EMCMain21Checksum m5 : 37|1@1+ (1,0) [0|1] "" Vector__XXX
 SG_ DPB_a335_EMCMain21Counter m5 : 38|1@1+ (1,0) [0|1] "" Vector__XXX
 SG_ DPB_a336_EMCMain21DLC m5 : 39|1@1+ (1,0) [0|1] "" Vector__XXX
 SG_ DPB_a337_EMCMain21Timeout m5 : 40|1@1+ (1,0) [0|1] "" Vector__XXX

BO_ 1426 EPAS3P_alertLog: 8 EPAS3P
 SG_ EPAS3P_alertID M : 0|8@1+ (1,0) [0|255] "" Vector__XXX
 SG_ EPAS3P_alertState : 15|1@1+ (1,0) [0|1] "" Vector__XXX
 SG_ EPAS3P_a147_transitionReason m147 : 16|2@1+ (1,0) [0|3] "" Vector__XXX
 SG_ EPAS3P_a149_pcbTemp m149 : 16|8@1- (1,60) [-68|187] "degC" Vector__XXX
 SG_ EPAS3P_a150_pcbTemp m150 : 16|8@1- (1,60) [-68|187] "degC" Vector__XXX
 SG_ EPAS3P_a150_phaUMainPathCalcDiff m150 : 24|15@1+ (1,0) [0|32767] "Counts" Vector__XXX
 SG_ EPAS3P_a150_phaVMainPathCalcDiff m150 : 39|15@1+ (1,0) [0|32767] "Counts" Vector__XXX
 SG_ EPAS3P_a150_otherECUAssistStatus m150 : 54|1@1+ (1,0) [0|1] "" Vector__XXX
 SG_ EPAS3P_a155_vehicleSpeed m155 : 16|10@1+ (0.5,0) [0|511.5] "kph" Vector__XXX
 SG_ EPAS3P_a156_vehicleSpeed m156 : 16|10@1+ (0.5,0) [0|511.5] "kph" Vector__XXX
 SG_ EPAS3P_a160_currentSensorStatus m160 : 16|2@1+ (1,0) [0|3] "" Vector__XXX
 SG_ EPAS3P_a160_gateDriverStatus m160 : 18|2@1+ (1,0) [0|3] "" Vector__XXX
 SG_ EPAS3P_a160_highSideDisconnectFe m160 : 20|2@1+ (1,0) [0|3] "" Vector__XXX
 SG_ EPAS3P_a160_phaseDisconnectFetSt m160 : 22|2@1+ (1,0) [0|3] "" Vector__XXX
 SG_ EPAS3P_a160_inverterFetStatus m160 : 24|2@1+ (1,0) [0|3] "" Vector__XXX
 SG_ EPAS3P_a160_hsdFetFailShortTest m160 : 26|2@1+ (1,0) [0|3] "" Vector__XXX
 SG_ EPAS3P_a160_phaDisconnFailOpenTe m160 : 28|2@1+ (1,0) [0|3] "" Vector__XXX
 SG_ EPAS3P_a160_phaDisconnFailShortT m160 : 30|2@1+ (1,0) [0|3] "" Vector__XXX
 SG_ EPAS3P_a160_invFetInitTest m160 : 32|2@1+ (1,0) [0|3] "" Vector__XXX
 SG_ EPAS3P_a160_gateDrvrInitTest m160 : 34|2@1+ (1,0) [0|3] "" Vector__XXX
 SG_ EPAS3P_a160_latentFaultTestTimeo m160 : 36|1@1+ (1,0) [0|1] "" Vector__XXX
 SG_ EPAS3P_a161_pcoMinPhaseBCurrent m161 : 16|12@1- (0.1025,0) [-209.92|209.8175] "Amps" Vector__XXX
 SG_ EPAS3P_a161_pcoMaxPhaseBCurrent m161 : 28|12@1- (0.1025,0) [-209.92|209.8175] "Amps" Vector__XXX
 SG_ EPAS3P_a161_pcoMinPhaseACurrent m161 : 40|12@1- (0.1025,0) [-209.92|209.8175] "Amps" Vector__XXX
 SG_ EPAS3P_a161_pcoMaxPhaseACurrent m161 : 52|12@1- (0.1025,0) [-209.92|209.8175] "Amps" Vector__XXX
 SG_ EPAS3P_a162_vBridgeClosed m162 : 16|16@1+ (0.00537,0) [0|351.92295] "Volts" Vector__XXX
 SG_ EPAS3P_a162_vBridgeOpen m162 : 32|16@1+ (0.00537,0) [0|351.92295] "Volts" Vector__XXX
 SG_ EPAS3P_a163_gateDrvrStatusReg m163 : 16|11@1+ (1,0) [0|2047] "Counts" Vector__XXX
 SG_ EPAS3P_a163_gateDrvrDiag2Reg m163 : 27|9@1+ (1,0) [0|511] "Counts" Vector__XXX
 SG_ EPAS3P_a163_gateDrvrDiag1Reg m163 : 36|9@1+ (1,0) [0|511] "Counts" Vector__XXX
 SG_ EPAS3P_a163_gateDrvrDiag0Reg m163 : 45|9@1+ (1,0) [0|511] "Counts" Vector__XXX
 SG_ EPAS3P_a163_diagStatus m163 : 54|1@1+ (1,0) [0|1] "" Vector__XXX
 SG_ EPAS3P_a163_powerStatus m163 : 55|1@1+ (1,0) [0|1] "" Vector__XXX
 SG_ EPAS3P_a164_dcsRegister0x19 m164 : 16|16@1+ (1,0) [0|65535] "Counts" Vector__XXX
 SG_ EPAS3P_a164_currentSensorRailed m164 : 32|1@1+ (1,0) [0|1] "" Vector__XXX

BO_TX_BU_ 871 : DI;
BO_TX_BU_ 84 : DI;
BO_TX_BU_ 328 : DI;
BO_TX_BU_ 1861 : DI;
BO_TX_BU_ 1869 : DI;
BO_TX_BU_ 694 : DI;
BO_TX_BU_ 2007 : DI;
BO_TX_BU_ 1866 : DI;
BO_TX_BU_ 1623 : DI;
BO_TX_BU_ 646 : DI;
BO_TX_BU_ 1270 : DI;
BO_TX_BU_ 822 : DI;
BO_TX_BU_ 950 : DI;
BO_TX_BU_ 599 : DI;
BO_TX_BU_ 2006 : DI;
BO_TX_BU_ 597 : DI;
BO_TX_BU_ 296 : DI;
BO_TX_BU_ 616 : DI;
BO_TX_BU_ 280 : DI;
BO_TX_BU_ 2036 : DI;
BO_TX_BU_ 615 : DI;
BO_TX_BU_ 1237 : DPB;
BO_TX_BU_ 999 : DPB;
BO_TX_BU_ 1426 : EPAS3P;
CM_ BO_ 871 "Drive inverter message: alert matrix";
CM_ SG_ 871 DI_matrixIndex "Drive inverter: matrix index";
CM_ SG_ 871 DI_a001_frunkSpeedLimitActive "Drive inverter: a001 frunk speed limit active";
CM_ SG_ 871 DI_a002_parkButtonDuringStalkReq "Drive inverter: a002 park button during stalk req";
CM_ SG_ 871 DI_a003_suggestedGearOverride "Drive inverter: a003 suggested gear override";
CM_ SG_ 871 DI_a004_smartShiftUnavailable "Drive inverter: a004 smart shift unavailable";
CM_ SG_ 871 DI_a005_stalkPanicked "Drive inverter: a005 stalk panicked";
CM_ SG_ 871 DI_a006_shifterUnavailable "Drive inverter: a006 shifter unavailable";
CM_ SG_ 871 DI_a007_secGearSelButtonStuck "Drive inverter: a007 sec gear sel button stuck";
CM_ SG_ 871 DI_a010_unintendedReset "Drive inverter: a010 unintended reset";
CM_ SG_ 871 DI_a012_accel5VSupply "Drive inverter: a012 accel5 v supply";
CM_ SG_ 871 DI_a013_eccError "Drive inverter: a013 ecc error";
CM_ SG_ 871 DI_a014_secGearSelActivated "Drive inverter: a014 sec gear sel activated";
CM_ SG_ 871 DI_a015_immobilizer "Drive inverter: a015 immobilizer";
CM_ SG_ 871 DI_a016_parkRequestByPM "Drive inverter: a016 park request by PM";
CM_ SG_ 871 DI_a017_hwPedalMonitor "Drive inverter: a017 hw pedal monitor";
CM_ SG_ 871 DI_a018_hwLVSupplyUV "Drive inverter: a018 hw LV supply UV";
CM_ SG_ 871 DI_a019_hwAccelPedalPower "Drive inverter: a019 hw accel pedal power";
CM_ SG_ 871 DI_a020_systemHvilNotClosed "Drive inverter: a020 system hvil not closed";
CM_ SG_ 871 DI_a021_packOvervoltage "Drive inverter: a021 pack overvoltage";
CM_ SG_ 871 DI_a022_hw5vSupplyUV "Drive inverter: a022 hw5v supply UV";
CM_ SG_ 871 DI_a023_carNotParked "Drive inverter: a023 car not parked";
CM_ SG_ 871 DI_a024_holdNForNeutral "Drive inverter: a024 hold n for neutral";
CM_ SG_ 871 DI_a025_regenBackfillUnavailable "Drive inverter: a025 regen backfill unavailable";
CM_ SG_ 871 DI_a026_parkPressedWithHighAPeda "Drive inverter: a026 park pressed with high a pedal";
CM_ SG_ 871 DI_a027_steeringAngleOffsetServi "Drive inverter: a027 steering angle offset service";
CM_ SG_ 871 DI_a028_secondaryShifterMuted "Drive inverter: a028 secondary shifter muted";
CM_ SG_ 871 DI_a031_closureAccelerationLimit "Drive inverter: a031 closure acceleration limit";
CM_ SG_ 871 DI_a036_sysStandbyUnitLimitedWai "Drive inverter: a036 sys standby unit limited wait";
CM_ SG_ 871 DI_a039_exceptionUndefinedInstru "Drive inverter: a039 exception undefined instruction";
CM_ SG_ 871 DI_a040_difMIA "Drive inverter: a040 dif MIA";
CM_ SG_ 871 DI_a041_driverBrakeApplyStuck "Drive inverter: a041 driver brake apply stuck";
CM_ SG_ 871 DI_a042_pmfMIA "Drive inverter: a042 pmf MIA";
CM_ SG_ 871 DI_a043_pmrMIA "Drive inverter: a043 pmr MIA";
CM_ SG_ 871 DI_d047_interfacePowerSupplyIssu "Drive inverter: d047 interface power supply issue";
CM_ SG_ 871 DI_a048_ecuLogAvailable "Drive inverter: a048 ecu log available";
CM_ SG_ 871 DI_d049_invalidOdometerReading "Drive inverter: d049 invalid odometer reading";
CM_ SG_ 871 DI_d050_interfaceUnitCommunicati "Drive inverter: d050 interface unit communication issue";
CM_ SG_ 871 DI_a051_batteryOvercurrent "Drive inverter: a051 battery overcurrent";
CM_ SG_ 871 DI_a052_dirMIA "Drive inverter: a052 dir MIA";
CM_ SG_ 871 DI_a053_canDataBusC "Drive inverter: a053 can data bus c";
CM_ SG_ 871 DI_a054_canOverrunBusC "Drive inverter: a054 can overrun bus c";
CM_ SG_ 871 DI_a055_canHardwareBusC "Drive inverter: a055 can hardware bus c";
CM_ SG_ 871 DI_a056_canDataBusD "Drive inverter: a056 can data bus d";
CM_ SG_ 871 DI_a057_canOverrunBusD "Drive inverter: a057 can overrun bus d";
CM_ SG_ 871 DI_a058_canHardwareBusD "Drive inverter: a058 can hardware bus d";
CM_ SG_ 871 DI_a059_canDataBusE "Drive inverter: a059 can data bus e";
CM_ SG_ 871 DI_a060_canOverrunBusE "Drive inverter: a060 can overrun bus e";
CM_ SG_ 871 DI_a061_canHardwareBusE "Drive inverter: a061 can hardware bus e";
CM_ SG_ 871 DI_a062_systemLimpMode "Drive inverter: a062 system limp mode";
CM_ SG_ 871 DI_a063_systemGracefulPowerOff "Drive inverter: a063 system graceful power off";
CM_ SG_ 871 DI_a064_pmsrmUnitMiaWithHvDown "Drive inverter: a064 pmsrm unit mia with hv down";
CM_ SG_ 871 DI_a065_canHardwareBusB "Drive inverter: a065 can hardware bus b";
CM_ SG_ 871 DI_a066_canDataBusB "Drive inverter: a066 can data bus b";
CM_ SG_ 871 DI_a067_canOverrunBusB "Drive inverter: a067 can overrun bus b";
CM_ SG_ 871 DI_a068_secondaryWheelSpeedIrrat "Drive inverter: a068 secondary wheel speed irrational";
CM_ SG_ 871 DI_a070_udsTransactionInitiated "Drive inverter: a070 uds transaction initiated";
CM_ SG_ 871 DI_d072_accelPedalSensorIssue "Drive inverter: d072 accel pedal sensor issue";
CM_ SG_ 871 DI_d073_accelPedalVoltSupplyIssu "Drive inverter: d073 accel pedal volt supply issue";
CM_ SG_ 871 DI_a074_unintendedResetAutoshift "Drive inverter: a074 unintended reset autoshift";
CM_ SG_ 871 DI_d075_incorrectImmobilizerKey "Drive inverter: d075 incorrect immobilizer key";
CM_ SG_ 871 DI_a076_lvSupplyOV "Drive inverter: a076 lv supply OV";
CM_ SG_ 871 DI_a077_lvSupplyUV "Drive inverter: a077 lv supply UV";
CM_ SG_ 871 DI_a078_adcRefLow "Drive inverter: a078 adc ref low";
CM_ SG_ 871 DI_a079_adcRefHigh "Drive inverter: a079 adc ref high";
CM_ SG_ 871 DI_a080_accelSynch "Drive inverter: a080 accel synch";
CM_ SG_ 871 DI_a081_accelTrack1 "Drive inverter: a081 accel track1";
CM_ SG_ 871 DI_a082_accelTrack2 "Drive inverter: a082 accel track2";
CM_ SG_ 871 DI_a083_brakePedalSensor "Drive inverter: a083 brake pedal sensor";
CM_ SG_ 871 DI_a084_eccTestData0 "Drive inverter: a084 ecc test data0";
CM_ SG_ 871 DI_a085_proximityInEnable "Drive inverter: a085 proximity in enable";
CM_ SG_ 871 DI_a086_dpbMIA "Drive inverter: a086 dpb MIA";
CM_ SG_ 871 DI_a087_gtwMIA "Drive inverter: a087 gtw MIA";
CM_ SG_ 871 DI_a088_uiMIA "Drive inverter: a088 ui MIA";
CM_ SG_ 871 DI_a089_sccmMIA "Drive inverter: a089 sccm MIA";
CM_ SG_ 871 DI_a090_pmMIA "Drive inverter: a090 pm MIA";
CM_ SG_ 871 DI_a091_espMIA "Drive inverter: a091 esp MIA";
CM_ SG_ 871 DI_a092_bmsMIA "Drive inverter: a092 bms MIA";
CM_ SG_ 871 DI_a093_canHardwareBusA "Drive inverter: a093 can hardware bus a";
CM_ SG_ 871 DI_a094_canDataBusA "Drive inverter: a094 can data bus a";
CM_ SG_ 871 DI_a095_canOverrunBusA "Drive inverter: a095 can overrun bus a";
CM_ SG_ 871 DI_a096_memoryError "Drive inverter: a096 memory error";
CM_ SG_ 871 DI_a097_eepromError "Drive inverter: a097 eeprom error";
CM_ SG_ 871 DI_a098_eepromManagerError "Drive inverter: a098 eeprom manager error";
CM_ SG_ 871 DI_a099_threadOverrun "Drive inverter: a099 thread overrun";
CM_ SG_ 871 DI_a100_nvramError "Drive inverter: a100 nvram error";
CM_ SG_ 871 DI_a101_eccTestData1 "Drive inverter: a101 ecc test data1";
CM_ SG_ 871 DI_a102_exceptionPrefetchAbort "Drive inverter: a102 exception prefetch abort";
CM_ SG_ 871 DI_a103_bbMIA "Drive inverter: a103 bb MIA";
CM_ SG_ 871 DI_a104_proximityIrrational "Drive inverter: a104 proximity irrational";
CM_ SG_ 871 DI_a105_cpMIA "Drive inverter: a105 cp MIA";
CM_ SG_ 871 DI_a106_idleTaskStarving "Drive inverter: a106 idle task starving";
CM_ SG_ 871 DI_a107_idbBrakeCircuitPressureO "Drive inverter: a107 idb brake circuit pressure offset suspect";
CM_ SG_ 871 DI_a108_appMIA "Drive inverter: a108 app MIA";
CM_ SG_ 871 DI_a109_ahbWriteError "Drive inverter: a109 ahb write error";
CM_ SG_ 871 DI_a110_brakeMIA "Drive inverter: a110 brake MIA";
CM_ SG_ 871 DI_a111_idbMIA "Drive inverter: a111 idb MIA";
CM_ SG_ 871 DI_a112_accelTrack1Incons "Drive inverter: a112 accel track1 incons";
CM_ SG_ 871 DI_a113_lowBrakeMCPressure "Drive inverter: a113 low brake MC pressure";
CM_ SG_ 871 DI_a114_exceptionDataAbort "Drive inverter: a114 exception data abort";
CM_ SG_ 871 DI_a115_exceptionDataAbort2 "Drive inverter: a115 exception data abort2";
CM_ SG_ 871 DI_a116_motorRecovered "Drive inverter: a116 motor recovered";
CM_ SG_ 871 DI_a117_latentFaultCheckTripped "Drive inverter: a117 latent fault check tripped";
CM_ SG_ 871 DI_a118_diImmobilizedForFactoryF "Drive inverter: a118 di immobilized for factory failsafe";
CM_ SG_ 871 DI_a119_latentFaultCheckFailedOn "Drive inverter: a119 latent fault check failed once";
CM_ SG_ 871 DI_a120_regenBlendingUnavailable "Drive inverter: a120 regen blending unavailable";
CM_ SG_ 871 DI_a121_qualifiedBrakeEventMitig "Drive inverter: a121 qualified brake event mitigation";
CM_ SG_ 871 DI_a122_highStackUsage "Drive inverter: a122 high stack usage";
CM_ SG_ 871 DI_a124_cruiseFault "Drive inverter: a124 cruise fault";
CM_ SG_ 871 DI_a125_noBatteryPower "Drive inverter: a125 no battery power";
CM_ SG_ 871 DI_a129_epbNotApplied "Drive inverter: a129 epb not applied";
CM_ SG_ 871 DI_a130_aebFault "Drive inverter: a130 aeb fault";
CM_ SG_ 871 DI_a131_highSpeedWearLimit "Drive inverter: a131 high speed wear limit";
CM_ SG_ 871 DI_a133_vehicleHoldTimedOut "Drive inverter: a133 vehicle hold timed out";
CM_ SG_ 871 DI_a134_wheelSpeedIrrational "Drive inverter: a134 wheel speed irrational";
CM_ SG_ 871 DI_a135_vehicleHoldFault "Drive inverter: a135 vehicle hold fault";
CM_ SG_ 871 DI_a137_noCapableDriveUnits "Drive inverter: a137 no capable drive units";
CM_ SG_ 871 DI_a138_frontUnitDisabled "Drive inverter: a138 front unit disabled";
CM_ SG_ 871 DI_a139_rearUnitDisabled "Drive inverter: a139 rear unit disabled";
CM_ SG_ 871 DI_a140_ptcMIA "Drive inverter: a140 ptc MIA";
CM_ SG_ 871 DI_a141_dasMIA "Drive inverter: a141 das MIA";
CM_ SG_ 871 DI_a142_potholeDetected "Drive inverter: a142 pothole detected";
CM_ SG_ 871 DI_a143_mcuLimitActive "Drive inverter: a143 mcu limit active";
CM_ SG_ 871 DI_a144_configMismatch "Drive inverter: a144 config mismatch";
CM_ SG_ 871 DI_a146_pbrkPanicEpbFault "Drive inverter: a146 pbrk panic epb fault";
CM_ SG_ 871 DI_a154_vdcRearSteering "Drive inverter: a154 vdc rear steering";
CM_ SG_ 871 DI_a155_vcfrontMIA "Drive inverter: a155 vcfront MIA";
CM_ SG_ 871 DI_a157_rcmMIA "Drive inverter: a157 rcm MIA";
CM_ SG_ 871 DI_a158_ibstMIA "Drive inverter: a158 ibst MIA";
CM_ SG_ 871 DI_a159_cruiseSelfCheck "Drive inverter: a159 cruise self check";
CM_ SG_ 871 DI_a160_fastLearnComplete "Drive inverter: a160 fast learn complete";
CM_ SG_ 871 DI_a161_epas3pMIA "Drive inverter: a161 epas3p MIA";
CM_ SG_ 871 DI_a162_shiftDenied "Drive inverter: a162 shift denied";
CM_ SG_ 871 DI_a163_shiftMotorSpeed "Drive inverter: a163 shift motor speed";
CM_ SG_ 871 DI_a164_brakeOverride "Drive inverter: a164 brake override";
CM_ SG_ 871 DI_a165_cruiseCancelled "Drive inverter: a165 cruise cancelled";
CM_ SG_ 871 DI_a166_driverLeft "Drive inverter: a166 driver left";
CM_ SG_ 871 DI_a167_keyNotAuthenticated "Drive inverter: a167 key not authenticated";
CM_ SG_ 871 DI_a168_proximityDriveDenial "Drive inverter: a168 proximity drive denial";
CM_ SG_ 871 DI_a169_regenOffOverride "Drive inverter: a169 regen off override";
CM_ SG_ 871 DI_a170_tireConfigUpdated "Drive inverter: a170 tire config updated";
CM_ SG_ 871 DI_a171_driveRailNotRequested "Drive inverter: a171 drive rail not requested";
CM_ SG_ 871 DI_a172_accelPressedInNP "Drive inverter: a172 accel pressed in NP";
CM_ SG_ 871 DI_a173_bothPedalsPressed "Drive inverter: a173 both pedals pressed";
CM_ SG_ 871 DI_a174_notOkToStartDrive "Drive inverter: a174 not ok to start drive";
CM_ SG_ 871 DI_a175_crsNotAvailable "Drive inverter: a175 crs not available";
CM_ SG_ 871 DI_a176_EBRreleased "Drive inverter: a176 EB rreleased";
CM_ SG_ 871 DI_a177_tireFitmentChanged "Drive inverter: a177 tire fitment changed";
CM_ SG_ 871 DI_a178_steeringAngleOffsetFault "Drive inverter: a178 steering angle offset fault";
CM_ SG_ 871 DI_a179_steeringAngleOffsetWarni "Drive inverter: a179 steering angle offset warning";
CM_ SG_ 871 DI_a180_crsSeatbeltUnbuckled "Drive inverter: a180 crs seatbelt unbuckled";
CM_ SG_ 871 DI_a181_rearMotorMode "Drive inverter: a181 rear motor mode";
CM_ SG_ 871 DI_a182_frontMotorMode "Drive inverter: a182 front motor mode";
CM_ SG_ 871 DI_a183_holdReleaseRqrd "Drive inverter: a183 hold release rqrd";
CM_ SG_ 871 DI_a184_autoparkCanceled "Drive inverter: a184 autopark canceled";
CM_ SG_ 871 DI_a185_autoparkAborted "Drive inverter: a185 autopark aborted";
CM_ SG_ 871 DI_a186_brakeStand "Drive inverter: a186 brake stand";
CM_ SG_ 871 DI_a187_pedalMisapplication "Drive inverter: a187 pedal misapplication";
CM_ SG_ 871 DI_a188_tireRotationRecommendedG "Drive inverter: a188 tire rotation recommended ghosted";
CM_ SG_ 871 DI_a189_garageShiftWithPedal "Drive inverter: a189 garage shift with pedal";
CM_ SG_ 871 DI_a190_tireRotationRecommended "Drive inverter: a190 tire rotation recommended";
CM_ SG_ 871 DI_a191_brakeShiftReq "Drive inverter: a191 brake shift req";
CM_ SG_ 871 DI_a192_invalidOdometer "Drive inverter: a192 invalid odometer";
CM_ SG_ 871 DI_a193_vdcBrakeTorqueFr "Drive inverter: a193 vdc brake torque fr";
CM_ SG_ 871 DI_a194_vdcBrakeTorqueRe "Drive inverter: a194 vdc brake torque re";
CM_ SG_ 871 DI_a195_vdcEspSlipFr "Drive inverter: a195 vdc esp slip fr";
CM_ SG_ 871 DI_a196_vdcEspSlipRe "Drive inverter: a196 vdc esp slip re";
CM_ SG_ 871 DI_a197_vdcEspWheelSaturations "Drive inverter: a197 vdc esp wheel saturations";
CM_ SG_ 871 DI_a198_vdcEspMCPressAndSteering "Drive inverter: a198 vdc esp MC press and steering";
CM_ SG_ 871 DI_a199_vdcFaulted "Drive inverter: a199 vdc faulted";
CM_ SG_ 871 DI_a200_vdcModelBasedPlausibilit "Drive inverter: a200 vdc model based plausibility";
CM_ SG_ 871 DI_a201_decelTorqueLimited "Drive inverter: a201 decel torque limited";
CM_ SG_ 871 DI_a202_excessHeatUnavailable "Drive inverter: a202 excess heat unavailable";
CM_ SG_ 871 DI_a203_TCReducedByADD "Drive inverter: a203 TC reduced by ADD";
CM_ SG_ 871 DI_a204_vdcRcmLongitudinal "Drive inverter: a204 vdc rcm longitudinal";
CM_ SG_ 871 DI_a205_vdcRcmLateral "Drive inverter: a205 vdc rcm lateral";
CM_ SG_ 871 DI_a206_vdcRcmVertical "Drive inverter: a206 vdc rcm vertical";
CM_ SG_ 871 DI_a207_vdcPowertrainTorque_dif "Drive inverter: a207 vdc powertrain torque dif";
CM_ SG_ 871 DI_a208_vdcPowertrainTorque_dir "Drive inverter: a208 vdc powertrain torque dir";
CM_ SG_ 871 DI_a210_vdcOtherControllerStates "Drive inverter: a210 vdc other controller states";
CM_ SG_ 871 DI_a211_vdcMotorSpeed_dif "Drive inverter: a211 vdc motor speed dif";
CM_ SG_ 871 DI_a212_vdcWheelRotations "Drive inverter: a212 vdc wheel rotations";
CM_ SG_ 871 DI_a213_lowMuProbabilityChange "Drive inverter: a213 low mu probability change";
CM_ SG_ 871 DI_a214_vdcWheelSpeedFr "Drive inverter: a214 vdc wheel speed fr";
CM_ SG_ 871 DI_a215_vdcWheelSpeedRe "Drive inverter: a215 vdc wheel speed re";
CM_ SG_ 871 DI_a216_vdcMBPAlmostTripped "Drive inverter: a216 vdc MBP almost tripped";
CM_ SG_ 871 DI_a217_vdcOutputIrrational "Drive inverter: a217 vdc output irrational";
CM_ SG_ 871 DI_a218_vdcOSPreControlActive "Drive inverter: a218 vdc OS pre control active";
CM_ SG_ 871 DI_a219_vdcOversteerdMzActive "Drive inverter: a219 vdc oversteerd mz active";
CM_ SG_ 871 DI_a220_vdcUndersteerDecelActive "Drive inverter: a220 vdc understeer decel active";
CM_ SG_ 871 DI_a221_vdcUndersteerdMzActive "Drive inverter: a221 vdc understeerd mz active";
CM_ SG_ 871 DI_a222_vdcDisabled "Drive inverter: a222 vdc disabled";
CM_ SG_ 871 DI_a223_tractionControlDisabled "Drive inverter: a223 traction control disabled";
CM_ SG_ 871 DI_a224_brakeOverTemp "Drive inverter: a224 brake over temp";
CM_ SG_ 871 DI_a225_vyEstimatorDegradedDebug "Drive inverter: a225 vy estimator degraded debug";
CM_ SG_ 871 DI_a226_sysStartConditionNotMet "Drive inverter: a226 sys start condition not met";
CM_ SG_ 871 DI_a227_contactorsNotClosed "Drive inverter: a227 contactors not closed";
CM_ SG_ 871 DI_a228_brakeTempEstUnavailable "Drive inverter: a228 brake temp est unavailable";
CM_ SG_ 871 DI_a230_cmpMIA "Drive inverter: a230 cmp MIA";
CM_ SG_ 871 DI_a231_softSystemLimpMode "Drive inverter: a231 soft system limp mode";
CM_ SG_ 871 DI_a232_velocityEstimatorDegrade "Drive inverter: a232 velocity estimator degraded";
CM_ SG_ 871 DI_a233_frontWheelImpactDetected "Drive inverter: a233 front wheel impact detected";
CM_ SG_ 871 DI_a235_trackModeActive "Drive inverter: a235 track mode active";
CM_ SG_ 871 DI_a236_tasMIA "Drive inverter: a236 tas MIA";
CM_ SG_ 871 DI_a237_undersideAbuse "Drive inverter: a237 underside abuse";
CM_ SG_ 871 DI_a238_secondaryCollisionMitiga "Drive inverter: a238 secondary collision mitigation active";
CM_ SG_ 871 DI_a239_neutralRequestByPM "Drive inverter: a239 neutral request by PM";
CM_ SG_ 871 DI_a240_torqueSplitStuck "Drive inverter: a240 torque split stuck";
CM_ SG_ 871 DI_a241_vdcMotorSpeed_dir "Drive inverter: a241 vdc motor speed dir";
CM_ SG_ 871 DI_a242_vdcTrailerSwayDetected "Drive inverter: a242 vdc trailer sway detected";
CM_ SG_ 871 DI_a243_rcuMIA "Drive inverter: a243 rcu MIA";
CM_ SG_ 871 DI_a244_vseRLSMassMismatch "Drive inverter: a244 vse RLS mass mismatch";
CM_ SG_ 871 DI_a245_opdReducedWithoutEbr "Drive inverter: a245 opd reduced without ebr";
CM_ SG_ 871 DI_a246_opdUnavailable "Drive inverter: a246 opd unavailable";
CM_ SG_ 871 DI_a248_vdcPreControlHighDynamic "Drive inverter: a248 vdc pre control high dynamic active";
CM_ SG_ 871 DI_a249_spinDownLearningInProgre "Drive inverter: a249 spin down learning in progress";
CM_ SG_ 871 DI_a250_tasSpeedLimitActive "Drive inverter: a250 tas speed limit active";
CM_ SG_ 871 DI_a251_diPowerOnStateMismatch "Drive inverter: a251 di power on state mismatch";
CM_ SG_ 871 DI_a253_accelSynchWarn "Drive inverter: a253 accel synch warn";
CM_ SG_ 871 DI_a254_vehicleStuckDetected "Drive inverter: a254 vehicle stuck detected";
CM_ SG_ 871 DI_a255_manualRecoveryMode "Drive inverter: a255 manual recovery mode";
CM_ BO_ 84 "Drive inverter message: autonomy health";
CM_ SG_ 84 DI_ah_vehicleSpeedLimit "Drive inverter: ah vehicle speed limit";
CM_ SG_ 84 DI_ah_vehicleReverseSpeedLimit "Drive inverter: ah vehicle reverse speed limit";
CM_ SG_ 84 DI_autonomyBehavior "Drive inverter: autonomy behavior";
CM_ SG_ 84 DI_ah_vehicleNoGradeAccelMax "Drive inverter: ah vehicle no grade accel max";
CM_ SG_ 84 DI_ah_vehicleNoGradeDecelMax "Drive inverter: ah vehicle no grade decel max";
CM_ SG_ 84 DI_ah_timeToNoPropulsion "Drive inverter: ah time to no propulsion";
CM_ SG_ 84 DI_ah_dGearAvailable "Drive inverter: ah d gear available";
CM_ SG_ 84 DI_ah_rGearAvailable "Drive inverter: ah r gear available";
CM_ SG_ 84 DI_ah_pGearAvailable "Drive inverter: ah p gear available";
CM_ SG_ 84 DI_loncDegradedAvailable "Drive inverter: lonc degraded available";
CM_ SG_ 84 DI_loncSuppressCancelModeAvailab "Drive inverter: lonc suppress cancel mode available";
CM_ SG_ 84 DI_loncDegradedReason "Drive inverter: lonc degraded reason";
CM_ SG_ 84 DI_opdAvailableForPedalInterface "Drive inverter: opd available for pedal interface";
CM_ SG_ 84 DI_epbUnavailable "Drive inverter: epb unavailable";
CM_ SG_ 84 DI_loncInPreFaultStopping "Drive inverter: lonc in pre fault stopping";
CM_ BO_ 328 "Drive inverter message: chassis control";
CM_ SG_ 328 DI_chassisControlChecksum "Drive inverter: chassis control checksum";
CM_ SG_ 328 DI_chassisControlCounter "Drive inverter: chassis control counter";
CM_ SG_ 328 DI_imuOffsetLearnRequest "Drive inverter: imu offset learn request";
CM_ SG_ 328 DI_brakeCommandType "Drive inverter: brake command type";
CM_ SG_ 328 DI_brakeTorqueRequestActive "Drive inverter: brake torque request active";
CM_ SG_ 328 DI_brakeTorqueCommand "Brake torque command to ESP";
CM_ SG_ 328 DI_ptcStateGlobal "Indicates state of Tesla traction control system; raw 3 = signal not available (SNA)";
CM_ SG_ 328 DI_ptcActive "TRUE when pedal-positive (drive) traction control is active";
CM_ SG_ 328 DI_vdcState "Status of VDC";
CM_ SG_ 328 DI_isAnyVdcControlActive "Drive inverter: is any vdc control active";
CM_ SG_ 328 DI_vdcMode "Indicates mode of VDC";
CM_ SG_ 328 DI_pedalAssistCurveSelect "Drive inverter: pedal assist curve select";
CM_ SG_ 328 DI_isAnyTcActive "TRUE when either drive or regen traction control is active";
CM_ SG_ 328 DI_VehicleMuConfidence "Confidence in surface mu estimate for development use only";
CM_ SG_ 328 DI_VehicleMu "Learn-up estimate of surface mu for development use only";
CM_ SG_ 328 DI_trailerSwayIndex "VDC trailer sway index";
CM_ SG_ 328 DI_vdcControlActive "Type of VDC control while VDC is actuating";
CM_ SG_ 328 DI_treadDepthAlertSet "Drive inverter: tread depth alert set";
CM_ BO_ 1861 "Drive inverter message: chassis control2";
CM_ SG_ 1861 DI_gradeAngle "Reports the grade angle.";
CM_ SG_ 1861 DI_bankAngle "Reports the bank angle.";
CM_ SG_ 1861 DI_chassisControlVideoRequest "Drive inverter: chassis control video request";
CM_ SG_ 1861 DI_eepDeliveryBitStatus "Drive inverter: eep delivery bit status";
CM_ SG_ 1861 DI_tireUtilizationRatioFrL "Drive inverter: tire utilization ratio fr l";
CM_ SG_ 1861 DI_tireUtilizationRatioFrR "Drive inverter: tire utilization ratio fr r";
CM_ SG_ 1861 DI_tireUtilizationRatioReL "Drive inverter: tire utilization ratio re l";
CM_ SG_ 1861 DI_tireUtilizationRatioReR "Drive inverter: tire utilization ratio re r";
CM_ SG_ 1861 DI_counterSteerTarget "Drive inverter: counter steer target";
CM_ SG_ 1861 DI_splitMuProbability "Drive inverter: split mu probability";
CM_ SG_ 1861 DI_mzError "Drive inverter: mz error";
CM_ SG_ 1861 DI_slipDifferenceFrontRear "Drive inverter: slip difference front rear";
CM_ SG_ 1861 DI_highFreqYawRate "Drive inverter: high freq yaw rate";
CM_ SG_ 1861 DI_turnDirection "Drive inverter: turn direction";
CM_ SG_ 1861 DI_absolutePreControlRequest "Drive inverter: absolute pre control request";
CM_ SG_ 1861 DI_oppositeBuildDirFrontAxle "Drive inverter: opposite build dir front axle";
CM_ SG_ 1861 DI_oppositeBuildDirRearAxle "Drive inverter: opposite build dir rear axle";
CM_ SG_ 1861 DI_saturatedEffectiveness "Drive inverter: saturated effectiveness";
CM_ SG_ 1861 DI_driverPanicIndex "Drive inverter: driver panic index";
CM_ SG_ 1861 DI_learnDownMu "Drive inverter: learn down mu";
CM_ SG_ 1861 DI_preControlOpposingTurnDir "Drive inverter: pre control opposing turn dir";
CM_ SG_ 1861 DI_driverFxError "Drive inverter: driver fx error";
CM_ SG_ 1861 DI_targetSaturation "Drive inverter: target saturation";
CM_ BO_ 1869 "Drive inverter message: chassis control3";
CM_ SG_ 1869 DI_tireWearFactor_FrL "Drive inverter: tire wear factor fr l";
CM_ SG_ 1869 DI_tireWearFactor_FrR "Drive inverter: tire wear factor fr r";
CM_ SG_ 1869 DI_tireWearFactor_ReL "Drive inverter: tire wear factor re l";
CM_ SG_ 1869 DI_tireWearFactor_ReR "Drive inverter: tire wear factor re r";
CM_ SG_ 1869 DI_kTireEstReUnSat "Drive inverter: k tire est re un sat; raw 127 = signal not available (SNA)";
CM_ SG_ 1869 DI_tireConfigSaved "Drive inverter: tire config saved";
CM_ SG_ 1869 DI_distanceSinceLastTireConfig "distance since odometer reading when Tire Configuration was last run; raw 63 = signal not available (SNA)";
CM_ SG_ 1869 DI_hydroplaningRisk "Drive inverter: hydroplaning risk";
CM_ SG_ 1869 DI_hydroplaningPuddlesWet "Drive inverter: hydroplaning puddles wet";
CM_ SG_ 1869 DI_hydroplaningPuddlesDry "Drive inverter: hydroplaning puddles dry";
CM_ SG_ 1869 DI_vehicleStuck "Drive inverter: vehicle stuck";
CM_ SG_ 1869 DI_kTireEstRe "Drive inverter: k tire est re; raw 31 = signal not available (SNA)";
CM_ SG_ 1869 DI_stickyMu "Drive inverter: sticky mu";
CM_ SG_ 1869 DI_stickyMuConfidence "Drive inverter: sticky mu confidence";
CM_ BO_ 694 "Drive inverter message: chassis control status";
CM_ SG_ 694 DI_vdcTelltaleFlash "Request to flash telltale in UI when VDC is active";
CM_ SG_ 694 DI_vdcTelltaleOn "Request to turn telltale ON in UI when VDC is faulted";
CM_ SG_ 694 DI_tcTelltaleFlash "Request to flash telltale in UI when TC is active";
CM_ SG_ 694 DI_tcTelltaleOn "Request to turn telltale ON in UI when TC is faulted";
CM_ SG_ 694 DI_tractionControlModeUI "Drive inverter: traction control mode UI";
CM_ SG_ 694 DI_ptcStateGlobalUI "Drive inverter: ptc state global UI; raw 3 = signal not available (SNA)";
CM_ SG_ 694 DI_btcStateUI "Drive inverter: btc state UI";
CM_ SG_ 694 DI_vehicleHoldTelltaleOn "Drive inverter: vehicle hold telltale on";
CM_ SG_ 694 DI_opdFeedbackReset "Drive inverter: opd feedback reset";
CM_ SG_ 694 DI_opdFeedbackResetPositiveSpeed "Drive inverter: opd feedback reset positive speeds";
CM_ SG_ 694 DI_slipperySurfaceOnUI "Drive inverter: slippery surface on UI";
CM_ SG_ 694 DI_yellowBrakeTelltaleOn "Request to turn yellow BRAKE telltale ON in UI";
CM_ SG_ 694 DI_greenABSTelltaleOn "Drive inverter: green ABS telltale on";
CM_ SG_ 694 DI_stabilityModeState "Current stability mode setting being honored by the DI";
CM_ BO_ 2007 "Drive inverter message: debug";
CM_ SG_ 2007 DI_debugSelector "Drive inverter: debug selector";
CM_ SG_ 2007 DI_regenBackfillCmd "Drive inverter: regen backfill cmd";
CM_ SG_ 2007 DI_regenBackfillUnavailableReaso "Drive inverter: regen backfill unavailable reason";
CM_ SG_ 2007 DI_regenBackfillAbsSatState "Drive inverter: regen backfill abs sat state";
CM_ SG_ 2007 DI_sysHeatPowerOptimal "Drive inverter: sys heat power optimal";
CM_ SG_ 2007 DI_sysPostPedalMinTorque "Drive inverter: sys post pedal min torque";
CM_ SG_ 2007 DI_sysPostPedalMaxTorque "Drive inverter: sys post pedal max torque";
CM_ SG_ 2007 DI_systemTorqueCommand "Drive inverter: system torque command";
CM_ BO_ 1866 "Drive inverter message: estimated brake temp";
CM_ SG_ 1866 DI_estimatedBrakeTempChecksum "Drive inverter: estimated brake temp checksum";
CM_ SG_ 1866 DI_estimatedBrakeTempCounter "Drive inverter: estimated brake temp counter";
CM_ SG_ 1866 DI_brakeFLTemp "Drive inverter: brake FL temp; raw 1023 = signal not available (SNA)";
CM_ SG_ 1866 DI_brakeFRTemp "Drive inverter: brake FR temp; raw 1023 = signal not available (SNA)";
CM_ SG_ 1866 DI_brakeRLTemp "Drive inverter: brake RL temp; raw 1023 = signal not available (SNA)";
CM_ SG_ 1866 DI_brakeRRTemp "Drive inverter: brake RR temp; raw 1023 = signal not available (SNA)";
CM_ SG_ 1866 DI_mcpIndex "Brake master cylinder pressure index";
CM_ SG_ 1866 DI_mcpIndexPrimeFilt "Filtered brake master cylinder pressure index prime";
CM_ BO_ 1623 "Drive inverter message: info";
CM_ SG_ 1623 DI_infoIndex "Drive inverter: info index";
CM_ SG_ 1623 DI_buildType "Drive inverter: build type";
CM_ SG_ 1623 DI_buildConfigurationId "Drive inverter: build configuration id";
CM_ SG_ 1623 DI_hardwareId "Drive inverter: hardware id";
CM_ SG_ 1623 DI_componentId "Drive inverter: component id";
CM_ SG_ 1623 DI_pcbaId "Drive inverter: pcba id";
CM_ SG_ 1623 DI_assemblyId "Drive inverter: assembly id";
CM_ SG_ 1623 DI_usageId "Drive inverter: usage id";
CM_ SG_ 1623 DI_subUsageId "Drive inverter: sub usage id";
CM_ SG_ 1623 DI_applicationCrc "Drive inverter: application crc";
CM_ SG_ 1623 DI_appGitHash "Drive inverter: app git hash";
CM_ SG_ 1623 DI_bootGitHash "Drive inverter: boot git hash";
CM_ BO_ 646 "Drive inverter message: loc status";
CM_ SG_ 646 DI_locStatusChecksum "Drive inverter: loc status checksum";
CM_ SG_ 646 DI_locStatusCounter "Drive inverter: loc status counter";
CM_ SG_ 646 DI_cruiseState "Cruise control state.";
CM_ SG_ 646 DI_cruiseSetSpeed "Cruise control set point.";
CM_ SG_ 646 DI_cruiseSetSpeedUnits "Drive inverter: cruise set speed units";
CM_ SG_ 646 DI_autoparkState "Drive inverter: autopark state; raw 15 = signal not available (SNA)";
CM_ SG_ 646 DI_parkBrakeState "DI Park Brake control and EPB interface state; raw 15 = signal not available (SNA)";
CM_ SG_ 646 DI_aebState "Reports the Automatic Emergency Braking (AEB) state; raw 7 = signal not available (SNA)";
CM_ SG_ 646 DI_loncDeactivationReason "Drive inverter: lonc deactivation reason";
CM_ SG_ 646 DI_vehicleHoldState "Vehicle hold state.";
CM_ SG_ 646 DI_summonInPanic "Drive inverter: summon in panic";
CM_ SG_ 646 DI_onePedalDrivingState "One Pedal Driving State machine state";
CM_ SG_ 646 DI_brakeStandActive "Detects active brake stand.";
CM_ SG_ 646 DI_regenBackfillState "Regen backfill state";
CM_ SG_ 646 DI_cruiseNotAvailableReason "Drive inverter: cruise not available reason; raw 20 = signal not available (SNA)";
CM_ SG_ 646 DI_cruiseFaultReason "Cruise control fault reason; raw 17 = signal not available (SNA)";
CM_ SG_ 646 DI_cruiseCancelReason "Cruise control cancel reason";
CM_ BO_ 1270 "Drive inverter message: loc status2";
CM_ SG_ 1270 DI_locStatus2Checksum "Drive inverter: loc status2 checksum";
CM_ SG_ 1270 DI_locStatus2Counter "Drive inverter: loc status2 counter";
CM_ SG_ 1270 DI_doublePedalState "Drive inverter: double pedal state";
CM_ SG_ 1270 DI_autopilotRequest "Drive inverter: autopilot request";
CM_ SG_ 1270 DI_rollPreventionState "Drive inverter: roll prevention state";
CM_ SG_ 1270 DI_locIntegratorSaturated "Drive inverter: loc integrator saturated";
CM_ SG_ 1270 DI_temporaryOpdActiveAfterLoncCa "Drive inverter: temporary opd active after lonc cancel";
CM_ SG_ 1270 DI_reapplyOnParkRequest "Drive inverter: reapply on park request";
CM_ SG_ 1270 DI_veDegradedAtStandstill "Drive inverter: ve degraded at standstill";
CM_ SG_ 1270 DI_brakeCpScale "Drive inverter: brake cp scale";
CM_ SG_ 1270 DI_rollbackDistance "Maximum vehicle rollback distance in current stopping event when OPD/Cruise is active";
CM_ SG_ 1270 DI_lowMuProbabilityConfidence "Drive inverter: low mu probability confidence";
CM_ SG_ 1270 DI_pedalAssistCurveSelectForSX "Drive inverter: pedal assist curve select for SX";
CM_ SG_ 1270 DI_longitudinalControlStack "Drive inverter: longitudinal control stack; raw 0 = signal not available (SNA)";
CM_ SG_ 1270 DI_useDasFallbackBrakeCommands "Drive inverter: use das fallback brake commands";
CM_ SG_ 1270 DI_regenBlendingState "Drive inverter: regen blending state";
CM_ SG_ 1270 DI_executeBatLocStatus2 "Drive inverter: execute bat loc status2";
CM_ BO_ 822 "Drive inverter message: max rated power";
CM_ SG_ 822 DI_sysDrivePowerRated "Drive inverter: sys drive power rated; raw 511 = signal not available (SNA)";
CM_ SG_ 822 DI_performancePackage "Drive inverter: performance package; raw 7 = signal not available (SNA)";
CM_ SG_ 822 DI_sysRegenPowerRated "Drive inverter: sys regen power rated; raw 255 = signal not available (SNA)";
CM_ BO_ 950 "Drive inverter message: odometer status";
CM_ SG_ 950 DI_odometer "Total traveled distance; raw 4294967295 = signal not available (SNA)";
CM_ SG_ 950 DI_obdDriveCycleStatus "OBD qualified drive cycle status";
CM_ SG_ 950 DI_odometerStatusCounter "Drive inverter: odometer status counter";
CM_ SG_ 950 DI_odometerStatusChecksum "Drive inverter: odometer status checksum";
CM_ BO_ 599 "Drive inverter message: speed";
CM_ SG_ 599 DI_speedChecksum "Drive inverter: speed checksum";
CM_ SG_ 599 DI_speedCounter "Drive inverter: speed counter";
CM_ SG_ 599 DI_locSpeedEst "Drive inverter: loc speed est; raw 4095 = signal not available (SNA)";
CM_ SG_ 599 DI_uiSpeed "Drive inverter: ui speed; raw 511 = signal not available (SNA)";
CM_ SG_ 599 DI_uiSpeedUnits "Drive inverter: ui speed units";
CM_ SG_ 599 DI_accelPedalPressed "TRUE when the calibrated accel pedal position > 0.0";
CM_ SG_ 599 DI_sideslipEstimate "Drive inverter: sideslip estimate";
CM_ SG_ 599 DI_vehicleSpeed "Reports vehicle speed; raw 8191 = signal not available (SNA)";
CM_ SG_ 599 DI_velocityEstimatorState "Drive inverter: velocity estimator state";
CM_ SG_ 599 DI_autoEnableHazards "Drive inverter: auto enable hazards";
CM_ SG_ 599 DI_longControlCommandActive "Drive inverter: long control command active";
CM_ BO_ 2006 "Drive inverter message: stalkless interfaces";
CM_ SG_ 2006 DI_stalklessInterfacesChecksum "Drive inverter: stalkless interfaces checksum";
CM_ SG_ 2006 DI_stalklessInterfacesCounter "Drive inverter: stalkless interfaces counter";
CM_ SG_ 2006 DI_smartShiftClosureOpen "Drive inverter: smart shift closure open";
CM_ SG_ 2006 DI_smartShiftSeatbeltUnbuckled "Drive inverter: smart shift seatbelt unbuckled";
CM_ SG_ 2006 DI_smartShiftAvailable "Drive inverter: smart shift available";
CM_ SG_ 2006 DI_smartShiftPrimed "Drive inverter: smart shift primed";
CM_ SG_ 2006 DI_smartShiftBrakePressed "Drive inverter: smart shift brake pressed";
CM_ SG_ 2006 DI_smartShiftBrakeReapplyRequire "Drive inverter: smart shift brake reapply required";
CM_ BO_ 597 "Drive inverter message: suggested gear";
CM_ SG_ 597 DI_lastQualifiedGear "Drive inverter: last qualified gear; raw 7 = signal not available (SNA)";
CM_ SG_ 597 DI_lastDrivingGear "Drive inverter: last driving gear; raw 7 = signal not available (SNA)";
CM_ SG_ 597 DI_distDrivenInGear "Drive inverter: dist driven in gear";
CM_ SG_ 597 DI_frontBlocked "Drive inverter: front blocked";
CM_ SG_ 597 DI_rearBlocked "Drive inverter: rear blocked";
CM_ SG_ 597 DI_firstShiftOccurred "Drive inverter: first shift occurred";
CM_ SG_ 597 DI_suggestedGearReason "Reason for the suggested gear";
CM_ SG_ 597 DI_parallelParked "Drive inverter: parallel parked";
CM_ SG_ 597 DI_smartShiftGear "Gear vehicle will shift into if smart shift occurs";
CM_ SG_ 597 DI_smartShiftUnavailableReason "Reports the reason why Smart Shift is unavailable; raw 0 = signal not available (SNA)";
CM_ BO_ 296 "Drive inverter message: system limits";
CM_ SG_ 296 DI_limitRegenPower "TRUE when torque is limited due to regen power limit.";
CM_ SG_ 296 DI_limitIBat "TRUE when torque is limited due to battery current.";
CM_ SG_ 296 DI_limitVBatLow "Drive inverter: limit v bat low";
CM_ SG_ 296 DI_limitVBatHigh "Drive inverter: limit v bat high";
CM_ SG_ 296 DI_limitObstacleDetection "TRUE when torque is limited due to obstacle detected in vehicle path.";
CM_ SG_ 296 DI_limitSystemLimp "Drive inverter: limit system limp";
CM_ SG_ 296 DI_limitSystemGPO "Drive inverter: limit system GPO";
CM_ SG_ 296 DI_limitShift "Drive inverter: limit shift";
CM_ SG_ 296 DI_limitDriveTorque "TRUE when drive torque is limited due to driver torque limit command";
CM_ SG_ 296 DI_limitRegenTorque "TRUE when regen torque is limited due to driver torque limit command";
CM_ SG_ 296 DI_limitVehicleSpeed "Drive inverter: limit vehicle speed";
CM_ SG_ 296 DI_limitBmsMiaFreeze "Drive inverter: limit bms mia freeze";
CM_ SG_ 296 DI_limitSystemSpinDownLearning "Drive inverter: limit system spin down learning";
CM_ SG_ 296 DI_limitCdp "Drive inverter: limit cdp";
CM_ SG_ 296 DI_vehicleSpeedLimitType "Speed limit source/type of DI_vehicleSpeedLimit.";
CM_ SG_ 296 DI_vehicleSpeedLimit "Vehicle speed limit (including powertrain limits) being enforced by the DI and published to the UI; raw 511 = signal not available (SNA)";
CM_ SG_ 296 DI_vehicleSpeedLimitReason "Speed limit reason of DI_vehicleSpeedLimit.";
CM_ SG_ 296 DI_proximity "TRUE if the proximity hardware input signal is active.";
CM_ SG_ 296 DI_limitClosureNotClosed "Drive inverter: limit closure not closed";
CM_ SG_ 296 DI_undersideAbuse "Drive inverter: underside abuse";
CM_ SG_ 296 DI_immobilizerAuthLevel "Immobilizer Authentication Level";
CM_ SG_ 296 DI_manualRecoveryDistanceRemaini "Drive inverter: manual recovery distance remaining; raw 127 = signal not available (SNA)";
CM_ SG_ 296 DI_restrictedDrivingMode "Drive inverter: restricted driving mode";
CM_ BO_ 616 "Drive inverter message: system power";
CM_ SG_ 616 DI_sysHeatPowerMax "Drive inverter: sys heat power max";
CM_ SG_ 616 DI_sysHeatPowerActual "Drive Inverter system heat power";
CM_ SG_ 616 DI_sysDrivePowerMax "Maximum drive power output total for all motors; raw 511 = signal not available (SNA)";
CM_ SG_ 616 DI_primaryUnitSiliconType "Drive inverter: primary unit silicon type";
CM_ SG_ 616 DI_sysRegenPowerMax "Maximum regen power output total for all motors; raw 255 = signal not available (SNA)";
CM_ BO_ 280 "Drive inverter message: system status";
CM_ SG_ 280 DI_systemStatusChecksum "Drive inverter: system status checksum";
CM_ SG_ 280 DI_systemStatusCounter "Drive inverter: system status counter";
CM_ SG_ 280 DI_secondaryGearControlStatus "Indicates if gear control through PRND is being honored";
CM_ SG_ 280 DI_immobilizerState "Detects state of the Drive Inverter (DI) immobilizer; raw 0 = signal not available (SNA)";
CM_ SG_ 280 DI_systemState "DI system state machine state.";
CM_ SG_ 280 DI_brakePedalState "Brake pedal switch signal sensed at the drive inverter.";
CM_ SG_ 280 DI_gear "Detects the current operating gear reported by the drive inverter; raw 7 = signal not available (SNA)";
CM_ SG_ 280 DI_driveBlocked "Reason drive unit is blocked from entering enable";
CM_ SG_ 280 DI_hvilSystemStatus "Aggregated HVIL system status; raw 3 = signal not available (SNA)";
CM_ SG_ 280 DI_driveModeState "System drive mode state";
CM_ SG_ 280 DI_shiftRequestType "Type of most recent shift request";
CM_ SG_ 280 DI_accelPedalPos "Drive Inverter measured accelerator pedal position; raw 255 = signal not available (SNA)";
CM_ SG_ 280 DI_tractionControlMode "Active traction control mode as requested by the driver.";
CM_ SG_ 280 DI_dynoModeAvailable "Reports to the vehicle if the Drive Inverter (DI) will accept a request to enter dyno mode.";
CM_ SG_ 280 DI_epbRequest "Reports Electronic Parking Brake (EPB) requests.";
CM_ SG_ 280 DI_brakeSource "Drive inverter: brake source";
CM_ SG_ 280 DI_keepDrivePowerStateRequest "Reports that the Drive Inverter (DI) expects vehicle power state to remain in drive.";
CM_ SG_ 280 DI_trackModeState "Indicates state of Track mode";
CM_ SG_ 280 DI_autonomyControlActive "Drive inverter: autonomy control active";
CM_ SG_ 280 DI_regenLight "Drive inverter: regen light";
CM_ SG_ 280 DI_vehicleAcceleration "Drive inverter: vehicle acceleration; raw 2048 = signal not available (SNA)";
CM_ BO_ 2036 "Drive inverter message: vdc right";
CM_ SG_ 2036 DI_vdcRightChecksum "Drive inverter: vdc right checksum";
CM_ SG_ 2036 DI_vdcRightCounter "Drive inverter: vdc right counter";
CM_ SG_ 2036 DI_vdcCommandTypeFrR "Drive inverter: vdc command type fr r";
CM_ SG_ 2036 DI_vdcCommandTypeReR "Drive inverter: vdc command type re r";
CM_ SG_ 2036 DI_vdcCommandABSFrR "Drive inverter: vdc command ABS fr r";
CM_ SG_ 2036 DI_vdcCommandABSReR "Drive inverter: vdc command ABS re r";
CM_ SG_ 2036 DI_brakeTorqueTarFrR "Drive inverter: brake torque tar fr r";
CM_ SG_ 2036 DI_brakeTorqueTarReR "Drive inverter: brake torque tar re r";
CM_ SG_ 2036 DI_wheelSlipLimitFrR "Drive inverter: wheel slip limit fr r";
CM_ SG_ 2036 DI_wheelSlipLimitReR "Drive inverter: wheel slip limit re r";
CM_ SG_ 2036 DI_rawLowMuProbability "Drive inverter: raw low mu probability";
CM_ BO_ 615 "Drive inverter message: vehicle estimates";
CM_ SG_ 615 DI_mass "Detects learned mass.";
CM_ SG_ 615 DI_massRLS "Drive inverter: mass RLS";
CM_ SG_ 615 DI_trailerDetected "Drive inverter: trailer detected";
CM_ SG_ 615 DI_vehicleEstimatesCounter "Drive inverter: vehicle estimates counter";
CM_ SG_ 615 DI_relativeTireTreadDepth "Reports estimate of tire wear ratio, represented in estimated tread depth difference between front and rear tires. A positive value indicates the rear tires are more worn than the front tires; raw 32 = signal not available (SNA)";
CM_ SG_ 615 DI_tireFitment "Drive inverter: tire fitment; raw 3 = signal not available (SNA)";
CM_ SG_ 615 DI_rollCoeff "Drive inverter: roll coeff";
CM_ SG_ 615 DI_massConfidence "Drive inverter: mass confidence";
CM_ SG_ 615 DI_gradeEst "Grade estimate reported by the drive inverter.";
CM_ SG_ 615 DI_vehicleEstimatesChecksum "Drive inverter: vehicle estimates checksum";
CM_ SG_ 615 DI_gradeEstInternal "Drive inverter: grade est internal";
CM_ SG_ 615 DI_massConfidenceRLS "Drive inverter: mass confidence RLS";
CM_ SG_ 615 DI_steeringAngleOffset "Steering angle offset learned by vehicle dynamics control (VDC) represented as a hand wheel angle";
CM_ BO_ 1237 "DPB ECU message: alert log";
CM_ SG_ 1237 DPB_alertID "DPB ECU: alert ID";
CM_ SG_ 1237 DPB_alertState "DPB ECU: alert state";
CM_ BO_ 999 "DPB ECU message: alert matrix";
CM_ SG_ 999 DPB_matrixIndex "DPB ECU: matrix index";
CM_ SG_ 999 DPB_a001_pPlungerSensorOffsetHig "DPB ECU: a001 p plunger sensor offset high";
CM_ SG_ 999 DPB_a002_pMC2SensorOffsetHigh "DPB ECU: a002 p MC2 sensor offset high";
CM_ SG_ 999 DPB_a003_AswEEPROMReadFailure "DPB ECU: a003 asw EEPROM read failure";
CM_ SG_ 999 DPB_a004_assertionFault "DPB ECU: a004 assertion fault";
CM_ SG_ 999 DPB_a005_hardPedalChar "DPB ECU: a005 hard pedal char";
CM_ SG_ 999 DPB_a006_hardPedalCharGoodCheck "DPB ECU: a006 hard pedal char good check";
CM_ SG_ 999 DPB_a007_PMCLeakageDetected "DPB ECU: a007 PMC leakage detected";
CM_ SG_ 999 DPB_a008_LiPSPts1Offset "DPB ECU: a008 li PS pts1 offset";
CM_ SG_ 999 DPB_a009_LiPSPts2Offset "DPB ECU: a009 li PS pts2 offset";
CM_ SG_ 999 DPB_a010_LiPSPtsConsistency "DPB ECU: a010 li PS pts consistency";
CM_ SG_ 999 DPB_a011_PtsNonZeroStage1 "DPB ECU: a011 pts non zero stage1";
CM_ SG_ 999 DPB_a012_PtsNonZeroStage2 "DPB ECU: a012 pts non zero stage2";
CM_ SG_ 999 DPB_a013_softPedalChar "DPB ECU: a013 soft pedal char";
CM_ SG_ 999 DPB_a014_CANControllerHWFault "DPB ECU: a014 CAN controller HW fault";
CM_ SG_ 999 DPB_a015_CAN1BusOff "DPB ECU: a015 CAN1 bus off";
CM_ SG_ 999 DPB_a016_CAN2BusOff "DPB ECU: a016 CAN2 bus off";
CM_ SG_ 999 DPB_a017_largeLeakageDetected "DPB ECU: a017 large leakage detected";
CM_ SG_ 999 DPB_a018_largeLeakageDetectedGoo "DPB ECU: a018 large leakage detected good check";
CM_ SG_ 999 DPB_a019_DETReportError "DPB ECU: a019 DET report error";
CM_ SG_ 999 DPB_a020_ecuHuMismatch "DPB ECU: a020 ecu hu mismatch";
CM_ SG_ 999 DPB_a021_brakeSystemOverheatLvl1 "DPB ECU: a021 brake system overheat lvl1";
CM_ SG_ 999 DPB_a022_brakeSystemOverheatLvl2 "DPB ECU: a022 brake system overheat lvl2";
CM_ SG_ 999 DPB_a023_initialPlungerCheckFail "DPB ECU: a023 initial plunger check failed";
CM_ SG_ 999 DPB_a024_ESPLDMFailure "DPB ECU: a024 ESPLDM failure";
CM_ SG_ 999 DPB_a025_backupCircuitLeakage "DPB ECU: a025 backup circuit leakage";
CM_ SG_ 999 DPB_a026_LiPSIDTimeout "DPB ECU: a026 li PSID timeout";
CM_ SG_ 999 DPB_a027_motorTempHighLevel1 "DPB ECU: a027 motor temp high level1";
CM_ SG_ 999 DPB_a028_motorTempHighLevel2 "DPB ECU: a028 motor temp high level2";
CM_ SG_ 999 DPB_a029_motorTestFault "DPB ECU: a029 motor test fault";
CM_ SG_ 999 DPB_a030_notShutDownRight "DPB ECU: a030 not shut down right";
CM_ SG_ 999 DPB_a031_HWParamReadFailed "DPB ECU: a031 HW param read failed";
CM_ SG_ 999 DPB_a032_HWParamWriteFailed "DPB ECU: a032 HW param write failed";
CM_ SG_ 999 DPB_a033_motorDynamicLimited "DPB ECU: a033 motor dynamic limited";
CM_ SG_ 999 DPB_a034_lipsMemoryEmpty "DPB ECU: a034 lips memory empty";
CM_ SG_ 999 DPB_a035_PDURouterinitialization "DPB ECU: a035 PDU routerinitialization failed";
CM_ SG_ 999 DPB_a036_lossOfPDUInstanceDetect "DPB ECU: a036 loss of PDU instance detected";
CM_ SG_ 999 DPB_a037_plungerCircuitPressHigh "DPB ECU: a037 plunger circuit press high";
CM_ SG_ 999 DPB_a038_plungerCircuitPressHigh "DPB ECU: a038 plunger circuit press high good check";
CM_ SG_ 999 DPB_a039_plungerCircuitPressLow "DPB ECU: a039 plunger circuit press low";
CM_ SG_ 999 DPB_a040_plungerCircuitPressLowG "DPB ECU: a040 plunger circuit press low good check";
CM_ SG_ 999 DPB_a041_PSCGearRatioReadFault "DPB ECU: a041 PSC gear ratio read fault";
CM_ SG_ 999 DPB_a042_motorLoadPressImplausib "DPB ECU: a042 motor load press implausible";
CM_ SG_ 999 DPB_a043_PSCMotorSizeReadFault "DPB ECU: a043 PSC motor size read fault";
CM_ SG_ 999 DPB_a044_supplyOvervoltageLvl1 "DPB ECU: a044 supply overvoltage lvl1";
CM_ SG_ 999 DPB_a045_supplyOvervoltageLvl2 "DPB ECU: a045 supply overvoltage lvl2";
CM_ SG_ 999 DPB_a046_supplyOvervoltageLvl3 "DPB ECU: a046 supply overvoltage lvl3";
CM_ SG_ 999 DPB_a047_pPlungerPlausCheckFailu "DPB ECU: a047 p plunger plaus check failure";
CM_ SG_ 999 DPB_a048_supplyUndervoltageLvl1 "DPB ECU: a048 supply undervoltage lvl1";
CM_ SG_ 999 DPB_a049_supplyUndervoltageLvl2 "DPB ECU: a049 supply undervoltage lvl2";
CM_ SG_ 999 DPB_a050_supplyUndervoltageLvl3 "DPB ECU: a050 supply undervoltage lvl3";
CM_ SG_ 999 DPB_a051_PSCVoltageImplausible "DPB ECU: a051 PSC voltage implausible";
CM_ SG_ 999 DPB_a052_PSIDTimeOut "DPB ECU: a052 PSID time out";
CM_ SG_ 999 DPB_a053_hydraulicAssemblyModeAc "DPB ECU: a053 hydraulic assembly mode active";
CM_ SG_ 999 DPB_a054_unsupportedHW "DPB ECU: a054 unsupported HW";
CM_ SG_ 999 DPB_a055_unsupportedSeriesHWDete "DPB ECU: a055 unsupported series HW detected";
CM_ SG_ 999 DPB_a056_AdcPeripheralFault "DPB ECU: a056 adc peripheral fault";
CM_ SG_ 999 DPB_a057_AdcPinTest "DPB ECU: a057 adc pin test";
CM_ SG_ 999 DPB_a058_AdcSelftestC5P "DPB ECU: a058 adc selftest C5 p";
CM_ SG_ 999 DPB_a059_factoryModeActive "DPB ECU: a059 factory mode active";
CM_ SG_ 999 DPB_a060_motorBridgeDriverFault "DPB ECU: a060 motor bridge driver fault";
CM_ SG_ 999 DPB_a061_bridgeSwitchInitError "DPB ECU: a061 bridge switch init error";
CM_ SG_ 999 DPB_a062_loadDumpOnFSLTest "DPB ECU: a062 load dump on FSL test";
CM_ SG_ 999 DPB_a063_motorConfigMismatch "DPB ECU: a063 motor config mismatch";
CM_ SG_ 999 DPB_a064_current1OffsetHigh "DPB ECU: a064 current1 offset high";
CM_ SG_ 999 DPB_a065_current1OffsetLow "DPB ECU: a065 current1 offset low";
CM_ SG_ 999 DPB_a066_current2OffsetHigh "DPB ECU: a066 current2 offset high";
CM_ SG_ 999 DPB_a067_current2OffsetLow "DPB ECU: a067 current2 offset low";
CM_ SG_ 999 DPB_a068_BLMMuxerTimeoutError "DPB ECU: a068 BLM muxer timeout error";
CM_ SG_ 999 DPB_a069_OBDCurrent1OORHigh "DPB ECU: a069 OBD current1 OOR high";
CM_ SG_ 999 DPB_a070_OBDCurrent1OORLow "DPB ECU: a070 OBD current1 OOR low";
CM_ SG_ 999 DPB_a071_OBDCurrent2OORHigh "DPB ECU: a071 OBD current2 OOR high";
CM_ SG_ 999 DPB_a072_OBDCurrent2OORLow "DPB ECU: a072 OBD current2 OOR low";
CM_ SG_ 999 DPB_a073_rotorCosOutOfRangeHigh "DPB ECU: a073 rotor cos out of range high";
CM_ SG_ 999 DPB_a074_rotorCosOutOfRangeLow "DPB ECU: a074 rotor cos out of range low";
CM_ SG_ 999 DPB_a075_rotorSinOutOfRangeHigh "DPB ECU: a075 rotor sin out of range high";
CM_ SG_ 999 DPB_a076_rotorSinOutOfRangeLow "DPB ECU: a076 rotor sin out of range low";
CM_ SG_ 999 DPB_a077_tempSens1ShortToSupply "DPB ECU: a077 temp sens1 short to supply";
CM_ SG_ 999 DPB_a078_tempSens1ShortToGround "DPB ECU: a078 temp sens1 short to ground";
CM_ SG_ 999 DPB_a079_tempSens2ShortToSupply "DPB ECU: a079 temp sens2 short to supply";
CM_ SG_ 999 DPB_a080_tempSens2ShortToGround "DPB ECU: a080 temp sens2 short to ground";
CM_ SG_ 999 DPB_a081_tempSensImplausVoltage "DPB ECU: a081 temp sens implaus voltage";
CM_ SG_ 999 DPB_a082_chargePumpFault "DPB ECU: a082 charge pump fault";
CM_ SG_ 999 DPB_a083_chargePumpUndervoltage "DPB ECU: a083 charge pump undervoltage";
CM_ SG_ 999 DPB_a084_RBCPUException "DPB ECU: a084 RBCPU exception";
CM_ SG_ 999 DPB_a085_infoFailureWrongCUBASHa "DPB ECU: a085 info failure wrong CUBAS handling detected";
CM_ SG_ 999 DPB_a086_diagHydProtectionPressF "DPB ECU: a086 diag hyd protection press fault";
CM_ SG_ 999 DPB_a087_diagHydProtectionVlvFau "DPB ECU: a087 diag hyd protection vlv fault";
CM_ SG_ 999 DPB_a088_DMATransferError "DPB ECU: a088 DMA transfer error";
CM_ SG_ 999 DPB_a089_ecuBandgap "DPB ECU: a089 ecu bandgap";
CM_ SG_ 999 DPB_a090_flashFault "DPB ECU: a090 flash fault";
CM_ SG_ 999 DPB_a091_MRGPathTestFault "DPB ECU: a091 MRG path test fault";
CM_ SG_ 999 DPB_a092_decoupleBitTestFault "DPB ECU: a092 decouple bit test fault";
CM_ SG_ 999 DPB_a093_ecuBistFaultCtrFault "DPB ECU: a093 ecu bist fault ctr fault";
CM_ SG_ 999 DPB_a094_ecuClockTestFault "DPB ECU: a094 ecu clock test fault";
CM_ SG_ 999 DPB_a095_ecuEnableElHighFault "DPB ECU: a095 ecu enable el high fault";
CM_ SG_ 999 DPB_a096_ecuEnableElLowFault "DPB ECU: a096 ecu enable el low fault";
CM_ SG_ 999 DPB_a097_ecuEnableHyHighFault "DPB ECU: a097 ecu enable hy high fault";
CM_ SG_ 999 DPB_a098_ecuEnableHyLowFault "DPB ECU: a098 ecu enable hy low fault";
CM_ SG_ 999 DPB_a099_ecuEnContinuousError "DPB ECU: a099 ecu en continuous error";
CM_ SG_ 999 DPB_a100_ecuErrpinCounterFault "DPB ECU: a100 ecu errpin counter fault";
CM_ SG_ 999 DPB_a101_ecuFastWdTestFault "DPB ECU: a101 ecu fast wd test fault";
CM_ SG_ 999 DPB_a102_ecuVrOnWhileWdTimeout "DPB ECU: a102 ecu vr on while wd timeout";
CM_ SG_ 999 DPB_a103_ecuVrViaSpiFails "DPB ECU: a103 ecu vr via spi fails";
CM_ SG_ 999 DPB_a104_ecuWdStartuptestFault "DPB ECU: a104 ecu wd startuptest fault";
CM_ SG_ 999 DPB_a105_ecuWdSContinuousError "DPB ECU: a105 ecu wd s continuous error";
CM_ SG_ 999 DPB_a106_ecuBistCmdTestFault "DPB ECU: a106 ecu bist cmd test fault";
CM_ SG_ 999 DPB_a107_vrOnFails "DPB ECU: a107 vr on fails";
CM_ SG_ 999 DPB_a108_GTMRefFrequencyError "DPB ECU: a108 GTM ref frequency error";
CM_ SG_ 999 DPB_a109_GTMTbuMonError "DPB ECU: a109 GTM tbu mon error";
CM_ SG_ 999 DPB_a110_HWBISTError "DPB ECU: a110 HWBIST error";
CM_ SG_ 999 DPB_a111_hydraulicHardUndervolta "DPB ECU: a111 hydraulic hard undervoltage";
CM_ SG_ 999 DPB_a112_hydraulicUndervoltage "DPB ECU: a112 hydraulic undervoltage";
CM_ SG_ 999 DPB_a113_LiPS1SentLineHigh "DPB ECU: a113 li PS1 sent line high";
CM_ SG_ 999 DPB_a114_LiPS1SentLineLow "DPB ECU: a114 li PS1 sent line low";
CM_ SG_ 999 DPB_a115_LiPS1SentSensor "DPB ECU: a115 li PS1 sent sensor";
CM_ SG_ 999 DPB_a116_LiPS1SentTransmission "DPB ECU: a116 li PS1 sent transmission";
CM_ SG_ 999 DPB_a117_LiPS2PwmLineHigh "DPB ECU: a117 li PS2 pwm line high";
CM_ SG_ 999 DPB_a118_LiPS2PwmLineLow "DPB ECU: a118 li PS2 pwm line low";
CM_ SG_ 999 DPB_a119_LiPS2PwmTransmission "DPB ECU: a119 li PS2 pwm transmission";
CM_ SG_ 999 DPB_a120_LiPSOutOfRangeHigh "DPB ECU: a120 li PS out of range high";
CM_ SG_ 999 DPB_a121_LiPSOutOfRangeLow "DPB ECU: a121 li PS out of range low";
CM_ SG_ 999 DPB_a122_micAsicClkInError "DPB ECU: a122 mic asic clk in error";
CM_ SG_ 999 DPB_a123_micAsicInitTestError "DPB ECU: a123 mic asic init test error";
CM_ SG_ 999 DPB_a124_asicOscillatorError "DPB ECU: a124 asic oscillator error";
CM_ SG_ 999 DPB_a125_B6AsicFault "DPB ECU: a125 B6 asic fault";
CM_ SG_ 999 DPB_a126_MICB6TransferError "DPB ECU: a126 MICB6 transfer error";
CM_ SG_ 999 DPB_a127_hydraulicAsicShortCircu "DPB ECU: a127 hydraulic asic short circuit";
CM_ SG_ 999 DPB_a128_micSpiTransferError "DPB ECU: a128 mic spi transfer error";
CM_ SG_ 999 DPB_a129_AsicTrimmingNotComplete "DPB ECU: a129 asic trimming not completed";
CM_ SG_ 999 DPB_a130_AsicMalfunctionDetected "DPB ECU: a130 asic malfunction detected";
CM_ SG_ 999 DPB_a131_ASICOvercurrentOnGPIO25 "DPB ECU: a131 ASIC overcurrent on GPIO250 1";
CM_ SG_ 999 DPB_a132_ASICOvercurrentOnGPIO25 "DPB ECU: a132 ASIC overcurrent on GPIO250 2";
CM_ SG_ 999 DPB_a133_ASICOvercurrentOnGPIO50 "DPB ECU: a133 ASIC overcurrent on GPIO50 1";
CM_ SG_ 999 DPB_a134_ASICOvercurrentOnGPIO50 "DPB ECU: a134 ASIC overcurrent on GPIO50 2";
CM_ SG_ 999 DPB_a135_ASICOvercurrentOnGPIO50 "DPB ECU: a135 ASIC overcurrent on GPIO50 3";
CM_ SG_ 999 DPB_a136_ASICOvercurrentOnGPIO50 "DPB ECU: a136 ASIC overcurrent on GPIO50 4";
CM_ SG_ 999 DPB_a137_ASICOvercurrentOnWRHS "DPB ECU: a137 ASIC overcurrent on WRHS";
CM_ SG_ 999 DPB_a138_DIchassisControlCounter "DPB ECU: a138 d ichassis control counter";
CM_ SG_ 999 DPB_a139_DIchassisControlChecksu "DPB ECU: a139 d ichassis control checksum";
CM_ SG_ 999 DPB_a140_DIchassisControlDLC "DPB ECU: a140 d ichassis control DLC";
CM_ SG_ 999 DPB_a141_DIchassisControlTimeout "DPB ECU: a141 d ichassis control timeout";
CM_ SG_ 999 DPB_a142_DIsystemStatusCounter "DPB ECU: a142 d isystem status counter";
CM_ SG_ 999 DPB_a143_DIsystemStatusChecksum "DPB ECU: a143 d isystem status checksum";
CM_ SG_ 999 DPB_a144_DIsystemStatusDLC "DPB ECU: a144 d isystem status DLC";
CM_ SG_ 999 DPB_a145_DIsystemStatusTimeout "DPB ECU: a145 d isystem status timeout";
CM_ SG_ 999 DPB_a146_DIFtorqueCounter "DPB ECU: a146 DI ftorque counter";
CM_ SG_ 999 DPB_a147_DIFtorqueChecksum "DPB ECU: a147 DI ftorque checksum";
CM_ SG_ 999 DPB_a148_DIFtorqueDLC "DPB ECU: a148 DI ftorque DLC";
CM_ SG_ 999 DPB_a149_DIFtorqueTimeout "DPB ECU: a149 DI ftorque timeout";
CM_ SG_ 999 DPB_a150_DIRtorqueCounter "DPB ECU: a150 DI rtorque counter";
CM_ SG_ 999 DPB_a151_DIRtorqueChecksum "DPB ECU: a151 DI rtorque checksum";
CM_ SG_ 999 DPB_a152_DIRtorqueDLC "DPB ECU: a152 DI rtorque DLC";
CM_ SG_ 999 DPB_a153_DIRtorqueTimeout "DPB ECU: a153 DI rtorque timeout";
CM_ SG_ 999 DPB_a154_EPBLstatusCounter "DPB ECU: a154 EPB lstatus counter";
CM_ SG_ 999 DPB_a155_EPBLstatusChecksum "DPB ECU: a155 EPB lstatus checksum";
CM_ SG_ 999 DPB_a156_EPBLstatusDLC "DPB ECU: a156 EPB lstatus DLC";
CM_ SG_ 999 DPB_a157_EPBLstatusTimeout "DPB ECU: a157 EPB lstatus timeout";
CM_ SG_ 999 DPB_a158_EPBRstatusCounter "DPB ECU: a158 EPB rstatus counter";
CM_ SG_ 999 DPB_a159_EPBRstatusChecksum "DPB ECU: a159 EPB rstatus checksum";
CM_ SG_ 999 DPB_a160_EPBRstatusDLC "DPB ECU: a160 EPB rstatus DLC";
CM_ SG_ 999 DPB_a161_EPBRstatusTimeout "DPB ECU: a161 EPB rstatus timeout";
CM_ SG_ 999 DPB_a162_ESP_modulator1Counter "DPB ECU: a162 ESP modulator1 counter";
CM_ SG_ 999 DPB_a163_ESP_modulator1Checksum "DPB ECU: a163 ESP modulator1 checksum";
CM_ SG_ 999 DPB_a164_ESP_modulator1DLC "DPB ECU: a164 ESP modulator1 DLC";
CM_ SG_ 999 DPB_a165_ESP_modulator1Timeout "DPB ECU: a165 ESP modulator1 timeout";
CM_ SG_ 999 DPB_a166_ESP_chassis3Counter "DPB ECU: a166 ESP chassis3 counter";
CM_ SG_ 999 DPB_a167_ESP_chassis3Checksum "DPB ECU: a167 ESP chassis3 checksum";
CM_ SG_ 999 DPB_a168_ESP_chassis3DLC "DPB ECU: a168 ESP chassis3 DLC";
CM_ SG_ 999 DPB_a169_ESP_chassis3Timeout "DPB ECU: a169 ESP chassis3 timeout";
CM_ SG_ 999 DPB_a170_ESP_modulator2Counter "DPB ECU: a170 ESP modulator2 counter";
CM_ SG_ 999 DPB_a171_ESP_modulator2Checksum "DPB ECU: a171 ESP modulator2 checksum";
CM_ SG_ 999 DPB_a172_ESP_modulator2DLC "DPB ECU: a172 ESP modulator2 DLC";
CM_ SG_ 999 DPB_a173_ESP_modulator2Timeout "DPB ECU: a173 ESP modulator2 timeout";
CM_ SG_ 999 DPB_a174_ESP_modulator3Counter "DPB ECU: a174 ESP modulator3 counter";
CM_ SG_ 999 DPB_a175_ESP_modulator3Checksum "DPB ECU: a175 ESP modulator3 checksum";
CM_ SG_ 999 DPB_a176_ESP_modulator3DLC "DPB ECU: a176 ESP modulator3 DLC";
CM_ SG_ 999 DPB_a177_ESP_modulator3Timeout "DPB ECU: a177 ESP modulator3 timeout";
CM_ SG_ 999 DPB_a178_PMstate2Counter "DPB ECU: a178 p mstate2 counter";
CM_ SG_ 999 DPB_a179_PMstate2Checksum "DPB ECU: a179 p mstate2 checksum";
CM_ SG_ 999 DPB_a180_PMstate2DLC "DPB ECU: a180 p mstate2 DLC";
CM_ SG_ 999 DPB_a181_PMstate2Timeout "DPB ECU: a181 p mstate2 timeout";
CM_ SG_ 999 DPB_a182_RCMInertial2Counter "DPB ECU: a182 RCM inertial2 counter";
CM_ SG_ 999 DPB_a183_RCMInertial2Checksum "DPB ECU: a183 RCM inertial2 checksum";
CM_ SG_ 999 DPB_a184_RCMInertial2DLC "DPB ECU: a184 RCM inertial2 DLC";
CM_ SG_ 999 DPB_a185_RCMInertial2Timeout "DPB ECU: a185 RCM inertial2 timeout";
CM_ SG_ 999 DPB_a186_LVPowerStateTimeout "DPB ECU: a186 LV power state timeout";
CM_ SG_ 999 DPB_a187_LVPowerStateChecksum "DPB ECU: a187 LV power state checksum";
CM_ SG_ 999 DPB_a188_LVPowerStateDLC "DPB ECU: a188 LV power state DLC";
CM_ SG_ 999 DPB_a189_LVPowerStateCounter "DPB ECU: a189 LV power state counter";
CM_ SG_ 999 DPB_a190_VCLEFTepbmStatusCounter "DPB ECU: a190 VCLEF tepbm status counter";
CM_ SG_ 999 DPB_a191_VCLEFTepbmStatusChecksu "DPB ECU: a191 VCLEF tepbm status checksum";
CM_ SG_ 999 DPB_a192_VCLEFTepbmStatusDLC "DPB ECU: a192 VCLEF tepbm status DLC";
CM_ SG_ 999 DPB_a193_VCLEFTepbmStatusTimeout "DPB ECU: a193 VCLEF tepbm status timeout";
CM_ SG_ 999 DPB_a194_VCRIGHTepbmStatusCounte "DPB ECU: a194 VCRIGH tepbm status counter";
CM_ SG_ 999 DPB_a195_VCRIGHTepbmStatusChecks "DPB ECU: a195 VCRIGH tepbm status checksum";
CM_ SG_ 999 DPB_a196_VCRIGHTepbmStatusDLC "DPB ECU: a196 VCRIGH tepbm status DLC";
CM_ SG_ 999 DPB_a197_VCRIGHTepbmStatusTimeou "DPB ECU: a197 VCRIGH tepbm status timeout";
CM_ SG_ 999 DPB_a198_CANOvervoltage "DPB ECU: a198 CAN overvoltage";
CM_ SG_ 999 DPB_a199_pMC1QFaulty "DPB ECU: a199 p MC1 q faulty";
CM_ SG_ 999 DPB_a200_ESPRunoutSupportNotAvai "DPB ECU: a200 ESP runout support not available";
CM_ SG_ 999 DPB_a201_vehicleSpeedQFaulty "DPB ECU: a201 vehicle speed q faulty";
CM_ SG_ 999 DPB_a202_vehicleStandstillQFault "DPB ECU: a202 vehicle standstill q faulty";
CM_ SG_ 999 DPB_a203_ABSNotAvailable "DPB ECU: a203 ABS not available";
CM_ SG_ 999 DPB_a204_CANUndervoltage "DPB ECU: a204 CAN undervoltage";
CM_ SG_ 999 DPB_a205_NvMWriteCycleExceed "DPB ECU: a205 nv m write cycle exceed";
CM_ SG_ 999 DPB_a206_OSTaskSchemeError "DPB ECU: a206 OS task scheme error";
CM_ SG_ 999 DPB_a207_hydraulicOvervoltage "DPB ECU: a207 hydraulic overvoltage";
CM_ SG_ 999 DPB_a208_pressureSensor1Short "DPB ECU: a208 pressure sensor1 short";
CM_ SG_ 999 DPB_a209_pressureSensor1High "DPB ECU: a209 pressure sensor1 high";
CM_ SG_ 999 DPB_a210_pressureSensor1Low "DPB ECU: a210 pressure sensor1 low";
CM_ SG_ 999 DPB_a211_pressureSensor1Fault "DPB ECU: a211 pressure sensor1 fault";
CM_ SG_ 999 DPB_a212_pressureSensor1Temp "DPB ECU: a212 pressure sensor1 temp";
CM_ SG_ 999 DPB_a213_pressureSensor1Fault "DPB ECU: a213 pressure sensor1 fault";
CM_ SG_ 999 DPB_a214_pressureSensor2Short "DPB ECU: a214 pressure sensor2 short";
CM_ SG_ 999 DPB_a215_pressureSensor2High "DPB ECU: a215 pressure sensor2 high";
CM_ SG_ 999 DPB_a216_pressureSensor2Low "DPB ECU: a216 pressure sensor2 low";
CM_ SG_ 999 DPB_a217_pressureSensor2Fault "DPB ECU: a217 pressure sensor2 fault";
CM_ SG_ 999 DPB_a218_pressureSensor2Temp "DPB ECU: a218 pressure sensor2 temp";
CM_ SG_ 999 DPB_a219_pressureSensor2Fault "DPB ECU: a219 pressure sensor2 fault";
CM_ SG_ 999 DPB_a220_excessiveBoostWakeupsDe "DPB ECU: a220 excessive boost wakeups detected";
CM_ SG_ 999 DPB_a221_notShutdownRight "DPB ECU: a221 not shutdown right";
CM_ SG_ 999 DPB_a222_excessiveEcuResetsDetec "DPB ECU: a222 excessive ecu resets detected";
CM_ SG_ 999 DPB_a223_RAMFault "DPB ECU: a223 RAM fault";
CM_ SG_ 999 DPB_a224_brakeBoostLost "DPB ECU: a224 brake boost lost";
CM_ SG_ 999 DPB_a225_U5VOutOfRange "DPB ECU: a225 U5 v out of range";
CM_ SG_ 999 DPB_a226_U5VTestFault "DPB ECU: a226 U5 v test fault";
CM_ SG_ 999 DPB_a227_brakeFluidLoss "DPB ECU: a227 brake fluid loss";
CM_ SG_ 999 DPB_a228_supplyASICInitFault "DPB ECU: a228 supply ASIC init fault";
CM_ SG_ 999 DPB_a229_IREFOutOfRange "DPB ECU: a229 IREF out of range";
CM_ SG_ 999 DPB_a230_OSErrorHook "DPB ECU: a230 OS error hook";
CM_ SG_ 999 DPB_a231_stackOverUnderFlow "DPB ECU: a231 stack over under flow";
CM_ SG_ 999 DPB_a232_systemErrorHook "DPB ECU: a232 system error hook";
CM_ SG_ 999 DPB_a233_systemTaskJitter "DPB ECU: a233 system task jitter";
CM_ SG_ 999 DPB_a234_systemTaskOverRun "DPB ECU: a234 system task over run";
CM_ SG_ 999 DPB_a235_UB6PlausiMonFault "DPB ECU: a235 UB6 plausi mon fault";
CM_ SG_ 999 DPB_a236_UB6SupplyPathFault "DPB ECU: a236 UB6 supply path fault";
CM_ SG_ 999 DPB_a237_uCVoltageDividerDrift "DPB ECU: a237 u c voltage divider drift";
CM_ SG_ 999 DPB_a238_microRegisterFault "DPB ECU: a238 micro register fault";
CM_ SG_ 999 DPB_a239_microSafetyFault "DPB ECU: a239 micro safety fault";
CM_ SG_ 999 DPB_a240_microSafetyLogicFault "DPB ECU: a240 micro safety logic fault";
CM_ SG_ 999 DPB_a241_uCSafetyNotification "DPB ECU: a241 u c safety notification";
CM_ SG_ 999 DPB_a242_uCSafetyNotificationGRA "DPB ECU: a242 u c safety notification GRAM";
CM_ SG_ 999 DPB_a243_microSupplyError "DPB ECU: a243 micro supply error";
CM_ SG_ 999 DPB_a244_valvesGenericFault "DPB ECU: a244 valves generic fault";
CM_ SG_ 999 DPB_a245_valveMV0Fault "DPB ECU: a245 valve MV0 fault";
CM_ SG_ 999 DPB_a246_valveMV5Fault "DPB ECU: a246 valve MV5 fault";
CM_ SG_ 999 DPB_a247_valveMV6Fault "DPB ECU: a247 valve MV6 fault";
CM_ SG_ 999 DPB_a248_valveMV61Fault "DPB ECU: a248 valve MV61 fault";
CM_ SG_ 999 DPB_a249_valveMV62Fault "DPB ECU: a249 valve MV62 fault";
CM_ SG_ 999 DPB_a250_valveMV7Fault "DPB ECU: a250 valve MV7 fault";
CM_ SG_ 999 DPB_a251_valveMV8Fault "DPB ECU: a251 valve MV8 fault";
CM_ SG_ 999 DPB_a252_valveMV81Fault "DPB ECU: a252 valve MV81 fault";
CM_ SG_ 999 DPB_a253_valveMV82Fault "DPB ECU: a253 valve MV82 fault";
CM_ SG_ 999 DPB_a254_valveMV9Fault "DPB ECU: a254 valve MV9 fault";
CM_ SG_ 999 DPB_a255_valveRelayShort "DPB ECU: a255 valve relay short";
CM_ SG_ 999 DPB_a256_valveRelayActuationFaul "DPB ECU: a256 valve relay actuation fault";
CM_ SG_ 999 DPB_a257_valveRelayOnContinuous "DPB ECU: a257 valve relay on continuous";
CM_ SG_ 999 DPB_a258_valveRelayOffContinuous "DPB ECU: a258 valve relay off continuous";
CM_ SG_ 999 DPB_a259_valveRelayTestUndervolt "DPB ECU: a259 valve relay test undervoltage";
CM_ SG_ 999 DPB_a260_valveRelaySafetySwitchF "DPB ECU: a260 valve relay safety switch fault";
CM_ SG_ 999 DPB_a261_WdhAsicWdCmdMissing "DPB ECU: a261 wdh asic wd cmd missing";
CM_ SG_ 999 DPB_a262_WdhAsicWdErrorCntLimit "DPB ECU: a262 wdh asic wd error cnt limit";
CM_ SG_ 999 DPB_a263_WdhAsicWdErrorCntStuck "DPB ECU: a263 wdh asic wd error cnt stuck";
CM_ SG_ 999 DPB_a264_WdhSwBistConCnt "DPB ECU: a264 wdh sw bist con cnt";
CM_ SG_ 999 DPB_a265_WdhTaskMonConCnt "DPB ECU: a265 wdh task mon con cnt";
CM_ SG_ 999 DPB_a266_RPSNvMReadFault "DPB ECU: a266 RPS nv m read fault";
CM_ SG_ 999 DPB_a267_RpsAngleImplausible "DPB ECU: a267 rps angle implausible";
CM_ SG_ 999 DPB_a268_RPSVectorOscillating "DPB ECU: a268 RPS vector oscillating";
CM_ SG_ 999 DPB_a269_RPSVectorRangeHigh "DPB ECU: a269 RPS vector range high";
CM_ SG_ 999 DPB_a270_RPSVectorRangeLow "DPB ECU: a270 RPS vector range low";
CM_ SG_ 999 DPB_a271_RPSWrongCalibData "DPB ECU: a271 RPS wrong calib data";
CM_ SG_ 999 DPB_a272_runtimeAssertionFault "DPB ECU: a272 runtime assertion fault";
CM_ SG_ 999 DPB_a273_SMMOneRequestsInit "DPB ECU: a273 SMM one requests init";
CM_ SG_ 999 DPB_a274_AswSystemTimeOut "DPB ECU: a274 asw system time out";
CM_ SG_ 999 DPB_a275_Ps1Ps2PlausibilityFault "DPB ECU: a275 ps1 ps2 plausibility fault";
CM_ SG_ 999 DPB_a276_VCFRONTsensorsCounter "DPB ECU: a276 VCFRON tsensors counter";
CM_ SG_ 999 DPB_a277_VCFRONTsensorsChecksum "DPB ECU: a277 VCFRON tsensors checksum";
CM_ SG_ 999 DPB_a278_VCFRONTsensorsDLC "DPB ECU: a278 VCFRON tsensors DLC";
CM_ SG_ 999 DPB_a279_VCFRONTsensorsTimeout "DPB ECU: a279 VCFRON tsensors timeout";
CM_ SG_ 999 DPB_a280_LowBrakeFluid "DPB ECU: a280 low brake fluid";
CM_ SG_ 999 DPB_a281_brakeFluidOORHigh "DPB ECU: a281 brake fluid OOR high";
CM_ SG_ 999 DPB_a282_DIbrakeCommandCounter "DPB ECU: a282 d ibrake command counter";
CM_ SG_ 999 DPB_a283_DIbrakeCommandChecksum "DPB ECU: a283 d ibrake command checksum";
CM_ SG_ 999 DPB_a284_DIbrakeCommandDLC "DPB ECU: a284 d ibrake command DLC";
CM_ SG_ 999 DPB_a285_DIbrakeCommandTimeout "DPB ECU: a285 d ibrake command timeout";
CM_ SG_ 999 DPB_a286_ebrCmdStateInvalid "DPB ECU: a286 ebr cmd state invalid";
CM_ SG_ 999 DPB_a287_brakeCmdStateInvalid "DPB ECU: a287 brake cmd state invalid";
CM_ SG_ 999 DPB_a288_PlantDegradedSW "DPB ECU: a288 plant degraded SW";
CM_ SG_ 999 DPB_a289_evacFillNotComplete "DPB ECU: a289 evac fill not complete";
CM_ SG_ 999 DPB_a290_securityInfo "DPB ECU: a290 security info";
CM_ SG_ 999 DPB_a291_extDBRRequestTooLow "DPB ECU: a291 ext DBR request too low";
CM_ SG_ 999 DPB_a292_CBDS_fillBufferThreshol "DPB ECU: a292 CBDS fill buffer threshold";
CM_ SG_ 999 DPB_a293_CBDS_fmeInternalEvent "DPB ECU: a293 CBDS fme internal event";
CM_ SG_ 999 DPB_a294_hbaNormalModeActive "DPB ECU: a294 hba normal mode active";
CM_ SG_ 999 DPB_a295_hbaTrackModeActive "DPB ECU: a295 hba track mode active";
CM_ SG_ 999 DPB_a296_StatInvalid_DI_FullSNA "DPB ECU: a296 stat invalid DI full SNA";
CM_ SG_ 999 DPB_a297_undefinedAlertDetected "DPB ECU: a297 undefined alert detected";
CM_ SG_ 999 DPB_a298_runningPlungerCircuitTe "DPB ECU: a298 running plunger circuit test";
CM_ SG_ 999 DPB_a299_PM_locStateCounter "DPB ECU: a299 PM loc state counter";
CM_ SG_ 999 DPB_a300_PM_locStateChecksum "DPB ECU: a300 PM loc state checksum";
CM_ SG_ 999 DPB_a301_PM_locStateDLC "DPB ECU: a301 PM loc state DLC";
CM_ SG_ 999 DPB_a302_PM_locStateTimeout "DPB ECU: a302 PM loc state timeout";
CM_ SG_ 999 DPB_a303_actuatingDIFullTorqueCm "DPB ECU: a303 actuating DI full torque cmd";
CM_ SG_ 999 DPB_a304_actuatingDITorqueCmd "DPB ECU: a304 actuating DI torque cmd";
CM_ SG_ 999 DPB_a305_DIbrakeTorqueCommandAnd "DPB ECU: a305 d ibrake torque command and flag mismatch";
CM_ SG_ 999 DPB_a306_actuatorFallbackBasicMa "DPB ECU: a306 actuator fallback basic map";
CM_ SG_ 999 DPB_a307_actuatorDegradedMap "DPB ECU: a307 actuator degraded map";
CM_ SG_ 999 DPB_a308_backupMode "DPB ECU: a308 backup mode";
CM_ SG_ 999 DPB_a309_DIFAxleTorqueInvalid "DPB ECU: a309 DIF axle torque invalid";
CM_ SG_ 999 DPB_a310_DIRAxleTorqueInvalid "DPB ECU: a310 DIR axle torque invalid";
CM_ SG_ 999 DPB_a311_postrunDurationTooLong "DPB ECU: a311 postrun duration too long";
CM_ SG_ 999 DPB_a312_continuouslyActivatedVa "DPB ECU: a312 continuously activated valves off";
CM_ SG_ 999 DPB_a313_qualifiedBrakeEventDete "DPB ECU: a313 qualified brake event detected";
CM_ SG_ 999 DPB_a314_runningCyclicVolumeChec "DPB ECU: a314 running cyclic volume check";
CM_ SG_ 999 DPB_a315_runningLeakageAndAirMon "DPB ECU: a315 running leakage and air monitoring";
CM_ SG_ 999 DPB_a316_lowBrakeFluidDetectedOn "DPB ECU: a316 low brake fluid detected on hill slope";
CM_ SG_ 999 DPB_a317_DASredundantBrakingCont "DPB ECU: a317 DA sredundant braking control party checksum";
CM_ SG_ 999 DPB_a318_DASredundantBrakingCont "DPB ECU: a318 DA sredundant braking control party counter";
CM_ SG_ 999 DPB_a319_DASredundantBrakingCont "DPB ECU: a319 DA sredundant braking control party DLC";
CM_ SG_ 999 DPB_a320_DASredundantBrakingCont "DPB ECU: a320 DA sredundant braking control party timeout";
CM_ SG_ 999 DPB_a321_DASredundantBrakingCont "DPB ECU: a321 DA sredundant braking control chassis checksum";
CM_ SG_ 999 DPB_a322_DASredundantBrakingCont "DPB ECU: a322 DA sredundant braking control chassis counter";
CM_ SG_ 999 DPB_a323_DASredundantBrakingCont "DPB ECU: a323 DA sredundant braking control chassis DLC";
CM_ SG_ 999 DPB_a324_DASredundantBrakingCont "DPB ECU: a324 DA sredundant braking control chassis timeout";
CM_ SG_ 999 DPB_a325_DIlocStatus2Checksum "DPB ECU: a325 d iloc status2 checksum";
CM_ SG_ 999 DPB_a326_DIlocStatus2Counter "DPB ECU: a326 d iloc status2 counter";
CM_ SG_ 999 DPB_a327_DIlocStatus2DLC "DPB ECU: a327 d iloc status2 DLC";
CM_ SG_ 999 DPB_a328_DIlocStatus2Timeout "DPB ECU: a328 d iloc status2 timeout";
CM_ SG_ 999 DPB_a329_standaloneEBRActive "DPB ECU: a329 standalone EBR active";
CM_ SG_ 999 DPB_a330_EMCMain11Checksum "DPB ECU: a330 EMC main11 checksum";
CM_ SG_ 999 DPB_a331_EMCMain11Counter "DPB ECU: a331 EMC main11 counter";
CM_ SG_ 999 DPB_a332_EMCMain11DLC "DPB ECU: a332 EMC main11 DLC";
CM_ SG_ 999 DPB_a333_EMCMain11Timeout "DPB ECU: a333 EMC main11 timeout";
CM_ SG_ 999 DPB_a334_EMCMain21Checksum "DPB ECU: a334 EMC main21 checksum";
CM_ SG_ 999 DPB_a335_EMCMain21Counter "DPB ECU: a335 EMC main21 counter";
CM_ SG_ 999 DPB_a336_EMCMain21DLC "DPB ECU: a336 EMC main21 DLC";
CM_ SG_ 999 DPB_a337_EMCMain21Timeout "DPB ECU: a337 EMC main21 timeout";
CM_ BO_ 1426 "Electric power steering (primary) message: alert log";
CM_ SG_ 1426 EPAS3P_alertID "Electric power steering (primary): alert ID";
CM_ SG_ 1426 EPAS3P_alertState "Electric power steering (primary): alert state";
CM_ SG_ 1426 EPAS3P_a147_transitionReason "Electric power steering (primary): a147 transition reason";
CM_ SG_ 1426 EPAS3P_a149_pcbTemp "Electric power steering (primary): a149 pcb temp";
CM_ SG_ 1426 EPAS3P_a150_pcbTemp "Electric power steering (primary): a150 pcb temp";
CM_ SG_ 1426 EPAS3P_a150_phaUMainPathCalcDiff "Electric power steering (primary): a150 pha u main path calc diff";
CM_ SG_ 1426 EPAS3P_a150_phaVMainPathCalcDiff "Electric power steering (primary): a150 pha v main path calc diff";
CM_ SG_ 1426 EPAS3P_a150_otherECUAssistStatus "Electric power steering (primary): a150 other ECU assist status flag";
CM_ SG_ 1426 EPAS3P_a155_vehicleSpeed "Electric power steering (primary): a155 vehicle speed";
CM_ SG_ 1426 EPAS3P_a156_vehicleSpeed "Electric power steering (primary): a156 vehicle speed";
CM_ SG_ 1426 EPAS3P_a160_currentSensorStatus "Electric power steering (primary): a160 current sensor status";
CM_ SG_ 1426 EPAS3P_a160_gateDriverStatus "Electric power steering (primary): a160 gate driver status";
CM_ SG_ 1426 EPAS3P_a160_highSideDisconnectFe "Electric power steering (primary): a160 high side disconnect fet status";
CM_ SG_ 1426 EPAS3P_a160_phaseDisconnectFetSt "Electric power steering (primary): a160 phase disconnect fet status";
CM_ SG_ 1426 EPAS3P_a160_inverterFetStatus "Electric power steering (primary): a160 inverter fet status";
CM_ SG_ 1426 EPAS3P_a160_hsdFetFailShortTest "Electric power steering (primary): a160 hsd fet fail short test";
CM_ SG_ 1426 EPAS3P_a160_phaDisconnFailOpenTe "Electric power steering (primary): a160 pha disconn fail open test";
CM_ SG_ 1426 EPAS3P_a160_phaDisconnFailShortT "Electric power steering (primary): a160 pha disconn fail short test";
CM_ SG_ 1426 EPAS3P_a160_invFetInitTest "Electric power steering (primary): a160 inv fet init test";
CM_ SG_ 1426 EPAS3P_a160_gateDrvrInitTest "Electric power steering (primary): a160 gate drvr init test";
CM_ SG_ 1426 EPAS3P_a160_latentFaultTestTimeo "Electric power steering (primary): a160 latent fault test timeout";
CM_ SG_ 1426 EPAS3P_a161_pcoMinPhaseBCurrent "Electric power steering (primary): a161 pco min phase b current";
CM_ SG_ 1426 EPAS3P_a161_pcoMaxPhaseBCurrent "Electric power steering (primary): a161 pco max phase b current";
CM_ SG_ 1426 EPAS3P_a161_pcoMinPhaseACurrent "Electric power steering (primary): a161 pco min phase a current";
CM_ SG_ 1426 EPAS3P_a161_pcoMaxPhaseACurrent "Electric power steering (primary): a161 pco max phase a current";
CM_ SG_ 1426 EPAS3P_a162_vBridgeClosed "Electric power steering (primary): a162 v bridge closed";
CM_ SG_ 1426 EPAS3P_a162_vBridgeOpen "Electric power steering (primary): a162 v bridge open";
CM_ SG_ 1426 EPAS3P_a163_gateDrvrStatusReg "Electric power steering (primary): a163 gate drvr status reg";
CM_ SG_ 1426 EPAS3P_a163_gateDrvrDiag2Reg "Electric power steering (primary): a163 gate drvr diag2 reg";
CM_ SG_ 1426 EPAS3P_a163_gateDrvrDiag1Reg "Electric power steering (primary): a163 gate drvr diag1 reg";
CM_ SG_ 1426 EPAS3P_a163_gateDrvrDiag0Reg "Electric power steering (primary): a163 gate drvr diag0 reg";
CM_ SG_ 1426 EPAS3P_a163_diagStatus "Electric power steering (primary): a163 diag status";
CM_ SG_ 1426 EPAS3P_a163_powerStatus "Electric power steering (primary): a163 power status";
CM_ SG_ 1426 EPAS3P_a164_dcsRegister0x19 "Electric power steering (primary): a164 dcs register0x19";
CM_ SG_ 1426 EPAS3P_a164_currentSensorRailed "Electric power steering (primary): a164 current sensor railed";
BA_DEF_ BO_ "GenMsgCycleTime" INT 0 3600000;
BA_DEF_ BO_ "GenMsgSendType" ENUM "Cyclic","NotUsed","NotUsed","NotUsed","NotUsed","NotUsed","NotUsed","IfActive","NoMsgSendType","NotUsed";
BA_DEF_ BO_ "VFrameFormat" ENUM "StandardCAN","ExtendedCAN","reserved","J1939PG","reserved","reserved","reserved","reserved","reserved","reserved","reserved","reserved","reserved","reserved","StandardCAN_FD","ExtendedCAN_FD";
BA_DEF_ BO_ "CANFD_BRS" ENUM "0","1";
BA_DEF_ SG_ "GenSigSNA" STRING;
BA_DEF_ SG_ "SystemSignalLongSymbol" STRING;
BA_DEF_ SG_ "Confidence" ENUM "validated","plausible","layout-only","contradicted";
BA_DEF_DEF_ "GenMsgCycleTime" 0;
BA_DEF_DEF_ "GenMsgSendType" "NoMsgSendType";
BA_DEF_DEF_ "VFrameFormat" "StandardCAN";
BA_DEF_DEF_ "CANFD_BRS" "1";
BA_DEF_DEF_ "GenSigSNA" "";
BA_DEF_DEF_ "SystemSignalLongSymbol" "";
BA_DEF_DEF_ "Confidence" "layout-only";
BA_ "GenMsgCycleTime" BO_ 871 1000;
BA_ "GenMsgSendType" BO_ 871 0;
BA_ "GenMsgCycleTime" BO_ 84 100;
BA_ "GenMsgSendType" BO_ 84 0;
BA_ "GenMsgCycleTime" BO_ 328 20;
BA_ "GenMsgSendType" BO_ 328 0;
BA_ "GenMsgCycleTime" BO_ 1861 100;
BA_ "GenMsgSendType" BO_ 1861 0;
BA_ "GenMsgCycleTime" BO_ 1869 1000;
BA_ "GenMsgSendType" BO_ 1869 0;
BA_ "GenMsgCycleTime" BO_ 694 100;
BA_ "GenMsgSendType" BO_ 694 0;
BA_ "GenMsgCycleTime" BO_ 2007 100;
BA_ "GenMsgSendType" BO_ 2007 0;
BA_ "GenMsgCycleTime" BO_ 1866 1000;
BA_ "GenMsgSendType" BO_ 1866 0;
BA_ "GenMsgCycleTime" BO_ 1623 1000;
BA_ "GenMsgSendType" BO_ 1623 0;
BA_ "GenMsgCycleTime" BO_ 646 100;
BA_ "GenMsgSendType" BO_ 646 0;
BA_ "GenMsgCycleTime" BO_ 1270 100;
BA_ "GenMsgSendType" BO_ 1270 0;
BA_ "GenMsgCycleTime" BO_ 822 1000;
BA_ "GenMsgSendType" BO_ 822 0;
BA_ "GenMsgCycleTime" BO_ 950 1000;
BA_ "GenMsgSendType" BO_ 950 0;
BA_ "GenMsgCycleTime" BO_ 599 20;
BA_ "GenMsgSendType" BO_ 599 0;
BA_ "GenMsgCycleTime" BO_ 2006 100;
BA_ "GenMsgSendType" BO_ 2006 0;
BA_ "GenMsgCycleTime" BO_ 597 100;
BA_ "GenMsgSendType" BO_ 597 0;
BA_ "GenMsgCycleTime" BO_ 296 100;
BA_ "GenMsgSendType" BO_ 296 0;
BA_ "GenMsgCycleTime" BO_ 616 100;
BA_ "GenMsgSendType" BO_ 616 0;
BA_ "GenMsgCycleTime" BO_ 280 10;
BA_ "GenMsgSendType" BO_ 280 0;
BA_ "GenMsgCycleTime" BO_ 2036 20;
BA_ "GenMsgSendType" BO_ 2036 0;
BA_ "GenMsgCycleTime" BO_ 615 1000;
BA_ "GenMsgSendType" BO_ 615 0;
BA_ "GenMsgCycleTime" BO_ 999 1000;
BA_ "GenMsgSendType" BO_ 999 0;
BA_ "Confidence" SG_ 871 DI_matrixIndex 1;
BA_ "SystemSignalLongSymbol" SG_ 871 DI_a026_parkPressedWithHighAPeda "DI_a026_parkPressedWithHighAPedal";
BA_ "SystemSignalLongSymbol" SG_ 871 DI_a027_steeringAngleOffsetServi "DI_a027_steeringAngleOffsetService";
BA_ "SystemSignalLongSymbol" SG_ 871 DI_a036_sysStandbyUnitLimitedWai "DI_a036_sysStandbyUnitLimitedWait";
BA_ "SystemSignalLongSymbol" SG_ 871 DI_a039_exceptionUndefinedInstru "DI_a039_exceptionUndefinedInstruction";
BA_ "SystemSignalLongSymbol" SG_ 871 DI_d047_interfacePowerSupplyIssu "DI_d047_interfacePowerSupplyIssue";
BA_ "SystemSignalLongSymbol" SG_ 871 DI_d050_interfaceUnitCommunicati "DI_d050_interfaceUnitCommunicationIssue";
BA_ "SystemSignalLongSymbol" SG_ 871 DI_a068_secondaryWheelSpeedIrrat "DI_a068_secondaryWheelSpeedIrrational";
BA_ "SystemSignalLongSymbol" SG_ 871 DI_d073_accelPedalVoltSupplyIssu "DI_d073_accelPedalVoltSupplyIssue";
BA_ "SystemSignalLongSymbol" SG_ 871 DI_a107_idbBrakeCircuitPressureO "DI_a107_idbBrakeCircuitPressureOffsetSuspect";
BA_ "SystemSignalLongSymbol" SG_ 871 DI_a118_diImmobilizedForFactoryF "DI_a118_diImmobilizedForFactoryFailsafe";
BA_ "SystemSignalLongSymbol" SG_ 871 DI_a119_latentFaultCheckFailedOn "DI_a119_latentFaultCheckFailedOnce";
BA_ "SystemSignalLongSymbol" SG_ 871 DI_a121_qualifiedBrakeEventMitig "DI_a121_qualifiedBrakeEventMitigation";
BA_ "SystemSignalLongSymbol" SG_ 871 DI_a179_steeringAngleOffsetWarni "DI_a179_steeringAngleOffsetWarning";
BA_ "SystemSignalLongSymbol" SG_ 871 DI_a188_tireRotationRecommendedG "DI_a188_tireRotationRecommendedGhosted";
BA_ "SystemSignalLongSymbol" SG_ 871 DI_a200_vdcModelBasedPlausibilit "DI_a200_vdcModelBasedPlausibility";
BA_ "SystemSignalLongSymbol" SG_ 871 DI_a232_velocityEstimatorDegrade "DI_a232_velocityEstimatorDegraded";
BA_ "SystemSignalLongSymbol" SG_ 871 DI_a238_secondaryCollisionMitiga "DI_a238_secondaryCollisionMitigationActive";
BA_ "SystemSignalLongSymbol" SG_ 871 DI_a248_vdcPreControlHighDynamic "DI_a248_vdcPreControlHighDynamicActive";
BA_ "SystemSignalLongSymbol" SG_ 871 DI_a249_spinDownLearningInProgre "DI_a249_spinDownLearningInProgress";
BA_ "Confidence" SG_ 84 DI_ah_vehicleSpeedLimit 0;
BA_ "Confidence" SG_ 84 DI_ah_vehicleReverseSpeedLimit 0;
BA_ "Confidence" SG_ 84 DI_autonomyBehavior 0;
BA_ "Confidence" SG_ 84 DI_ah_vehicleNoGradeAccelMax 0;
BA_ "Confidence" SG_ 84 DI_ah_vehicleNoGradeDecelMax 0;
BA_ "Confidence" SG_ 84 DI_ah_timeToNoPropulsion 0;
BA_ "Confidence" SG_ 84 DI_ah_dGearAvailable 0;
BA_ "Confidence" SG_ 84 DI_ah_rGearAvailable 0;
BA_ "Confidence" SG_ 84 DI_ah_pGearAvailable 0;
BA_ "Confidence" SG_ 84 DI_loncDegradedAvailable 0;
BA_ "Confidence" SG_ 84 DI_loncSuppressCancelModeAvailab 0;
BA_ "SystemSignalLongSymbol" SG_ 84 DI_loncSuppressCancelModeAvailab "DI_loncSuppressCancelModeAvailable";
BA_ "Confidence" SG_ 84 DI_loncDegradedReason 0;
BA_ "Confidence" SG_ 84 DI_opdAvailableForPedalInterface 0;
BA_ "Confidence" SG_ 84 DI_epbUnavailable 0;
BA_ "Confidence" SG_ 84 DI_loncInPreFaultStopping 0;
BA_ "Confidence" SG_ 328 DI_chassisControlChecksum 0;
BA_ "Confidence" SG_ 328 DI_chassisControlCounter 0;
BA_ "Confidence" SG_ 328 DI_imuOffsetLearnRequest 0;
BA_ "Confidence" SG_ 328 DI_brakeCommandType 0;
BA_ "Confidence" SG_ 328 DI_brakeTorqueRequestActive 0;
BA_ "Confidence" SG_ 328 DI_brakeTorqueCommand 0;
BA_ "Confidence" SG_ 328 DI_ptcStateGlobal 0;
BA_ "GenSigSNA" SG_ 328 DI_ptcStateGlobal "3";
BA_ "Confidence" SG_ 328 DI_ptcActive 0;
BA_ "Confidence" SG_ 328 DI_vdcState 0;
BA_ "Confidence" SG_ 328 DI_isAnyVdcControlActive 0;
BA_ "Confidence" SG_ 328 DI_vdcMode 0;
BA_ "Confidence" SG_ 328 DI_pedalAssistCurveSelect 0;
BA_ "Confidence" SG_ 328 DI_isAnyTcActive 0;
BA_ "Confidence" SG_ 328 DI_VehicleMuConfidence 0;
BA_ "Confidence" SG_ 328 DI_VehicleMu 0;
BA_ "Confidence" SG_ 328 DI_trailerSwayIndex 0;
BA_ "Confidence" SG_ 328 DI_vdcControlActive 0;
BA_ "Confidence" SG_ 328 DI_treadDepthAlertSet 0;
BA_ "Confidence" SG_ 1861 DI_gradeAngle 0;
BA_ "Confidence" SG_ 1861 DI_bankAngle 0;
BA_ "Confidence" SG_ 1861 DI_chassisControlVideoRequest 0;
BA_ "Confidence" SG_ 1861 DI_eepDeliveryBitStatus 0;
BA_ "Confidence" SG_ 1861 DI_tireUtilizationRatioFrL 0;
BA_ "Confidence" SG_ 1861 DI_tireUtilizationRatioFrR 0;
BA_ "Confidence" SG_ 1861 DI_tireUtilizationRatioReL 0;
BA_ "Confidence" SG_ 1861 DI_tireUtilizationRatioReR 0;
BA_ "Confidence" SG_ 1861 DI_counterSteerTarget 0;
BA_ "Confidence" SG_ 1861 DI_splitMuProbability 0;
BA_ "Confidence" SG_ 1861 DI_mzError 0;
BA_ "Confidence" SG_ 1861 DI_slipDifferenceFrontRear 0;
BA_ "Confidence" SG_ 1861 DI_highFreqYawRate 0;
BA_ "Confidence" SG_ 1861 DI_turnDirection 0;
BA_ "Confidence" SG_ 1861 DI_absolutePreControlRequest 0;
BA_ "Confidence" SG_ 1861 DI_oppositeBuildDirFrontAxle 0;
BA_ "Confidence" SG_ 1861 DI_oppositeBuildDirRearAxle 0;
BA_ "Confidence" SG_ 1861 DI_saturatedEffectiveness 0;
BA_ "Confidence" SG_ 1861 DI_driverPanicIndex 0;
BA_ "Confidence" SG_ 1861 DI_learnDownMu 0;
BA_ "Confidence" SG_ 1861 DI_preControlOpposingTurnDir 0;
BA_ "Confidence" SG_ 1861 DI_driverFxError 0;
BA_ "Confidence" SG_ 1861 DI_targetSaturation 0;
BA_ "Confidence" SG_ 1869 DI_tireWearFactor_FrL 0;
BA_ "Confidence" SG_ 1869 DI_tireWearFactor_FrR 0;
BA_ "Confidence" SG_ 1869 DI_tireWearFactor_ReL 0;
BA_ "Confidence" SG_ 1869 DI_tireWearFactor_ReR 0;
BA_ "Confidence" SG_ 1869 DI_kTireEstReUnSat 0;
BA_ "GenSigSNA" SG_ 1869 DI_kTireEstReUnSat "127";
BA_ "Confidence" SG_ 1869 DI_tireConfigSaved 0;
BA_ "Confidence" SG_ 1869 DI_distanceSinceLastTireConfig 0;
BA_ "GenSigSNA" SG_ 1869 DI_distanceSinceLastTireConfig "63";
BA_ "Confidence" SG_ 1869 DI_hydroplaningRisk 0;
BA_ "Confidence" SG_ 1869 DI_hydroplaningPuddlesWet 0;
BA_ "Confidence" SG_ 1869 DI_hydroplaningPuddlesDry 0;
BA_ "Confidence" SG_ 1869 DI_vehicleStuck 0;
BA_ "Confidence" SG_ 1869 DI_kTireEstRe 0;
BA_ "GenSigSNA" SG_ 1869 DI_kTireEstRe "31";
BA_ "Confidence" SG_ 1869 DI_stickyMu 0;
BA_ "Confidence" SG_ 1869 DI_stickyMuConfidence 0;
BA_ "Confidence" SG_ 694 DI_vdcTelltaleFlash 0;
BA_ "Confidence" SG_ 694 DI_vdcTelltaleOn 0;
BA_ "Confidence" SG_ 694 DI_tcTelltaleFlash 0;
BA_ "Confidence" SG_ 694 DI_tcTelltaleOn 0;
BA_ "Confidence" SG_ 694 DI_tractionControlModeUI 0;
BA_ "Confidence" SG_ 694 DI_ptcStateGlobalUI 0;
BA_ "GenSigSNA" SG_ 694 DI_ptcStateGlobalUI "3";
BA_ "Confidence" SG_ 694 DI_btcStateUI 0;
BA_ "Confidence" SG_ 694 DI_vehicleHoldTelltaleOn 0;
BA_ "Confidence" SG_ 694 DI_opdFeedbackReset 0;
BA_ "Confidence" SG_ 694 DI_opdFeedbackResetPositiveSpeed 0;
BA_ "SystemSignalLongSymbol" SG_ 694 DI_opdFeedbackResetPositiveSpeed "DI_opdFeedbackResetPositiveSpeeds";
BA_ "Confidence" SG_ 694 DI_slipperySurfaceOnUI 0;
BA_ "Confidence" SG_ 694 DI_yellowBrakeTelltaleOn 0;
BA_ "Confidence" SG_ 694 DI_greenABSTelltaleOn 0;
BA_ "Confidence" SG_ 694 DI_stabilityModeState 0;
BA_ "Confidence" SG_ 2007 DI_debugSelector 1;
BA_ "Confidence" SG_ 2007 DI_regenBackfillCmd 0;
BA_ "Confidence" SG_ 2007 DI_regenBackfillUnavailableReaso 0;
BA_ "SystemSignalLongSymbol" SG_ 2007 DI_regenBackfillUnavailableReaso "DI_regenBackfillUnavailableReason";
BA_ "Confidence" SG_ 2007 DI_regenBackfillAbsSatState 0;
BA_ "Confidence" SG_ 2007 DI_sysHeatPowerOptimal 0;
BA_ "Confidence" SG_ 2007 DI_sysPostPedalMinTorque 0;
BA_ "Confidence" SG_ 2007 DI_sysPostPedalMaxTorque 0;
BA_ "Confidence" SG_ 2007 DI_systemTorqueCommand 0;
BA_ "Confidence" SG_ 1866 DI_estimatedBrakeTempChecksum 0;
BA_ "Confidence" SG_ 1866 DI_estimatedBrakeTempCounter 0;
BA_ "Confidence" SG_ 1866 DI_brakeFLTemp 0;
BA_ "GenSigSNA" SG_ 1866 DI_brakeFLTemp "1023";
BA_ "Confidence" SG_ 1866 DI_brakeFRTemp 0;
BA_ "GenSigSNA" SG_ 1866 DI_brakeFRTemp "1023";
BA_ "Confidence" SG_ 1866 DI_brakeRLTemp 0;
BA_ "GenSigSNA" SG_ 1866 DI_brakeRLTemp "1023";
BA_ "Confidence" SG_ 1866 DI_brakeRRTemp 0;
BA_ "GenSigSNA" SG_ 1866 DI_brakeRRTemp "1023";
BA_ "Confidence" SG_ 1866 DI_mcpIndex 0;
BA_ "Confidence" SG_ 1866 DI_mcpIndexPrimeFilt 0;
BA_ "Confidence" SG_ 1623 DI_infoIndex 1;
BA_ "Confidence" SG_ 1623 DI_buildType 0;
BA_ "Confidence" SG_ 1623 DI_buildConfigurationId 0;
BA_ "Confidence" SG_ 1623 DI_hardwareId 0;
BA_ "Confidence" SG_ 1623 DI_componentId 0;
BA_ "Confidence" SG_ 1623 DI_pcbaId 0;
BA_ "Confidence" SG_ 1623 DI_assemblyId 0;
BA_ "Confidence" SG_ 1623 DI_usageId 0;
BA_ "Confidence" SG_ 1623 DI_subUsageId 0;
BA_ "Confidence" SG_ 1623 DI_applicationCrc 0;
BA_ "Confidence" SG_ 1623 DI_appGitHash 0;
BA_ "Confidence" SG_ 1623 DI_bootGitHash 0;
BA_ "Confidence" SG_ 646 DI_locStatusChecksum 0;
BA_ "Confidence" SG_ 646 DI_locStatusCounter 0;
BA_ "Confidence" SG_ 646 DI_cruiseState 0;
BA_ "Confidence" SG_ 646 DI_cruiseSetSpeed 0;
BA_ "Confidence" SG_ 646 DI_cruiseSetSpeedUnits 0;
BA_ "Confidence" SG_ 646 DI_autoparkState 0;
BA_ "GenSigSNA" SG_ 646 DI_autoparkState "15";
BA_ "Confidence" SG_ 646 DI_parkBrakeState 0;
BA_ "GenSigSNA" SG_ 646 DI_parkBrakeState "15";
BA_ "Confidence" SG_ 646 DI_aebState 0;
BA_ "GenSigSNA" SG_ 646 DI_aebState "7";
BA_ "Confidence" SG_ 646 DI_loncDeactivationReason 0;
BA_ "Confidence" SG_ 646 DI_vehicleHoldState 0;
BA_ "Confidence" SG_ 646 DI_summonInPanic 0;
BA_ "Confidence" SG_ 646 DI_onePedalDrivingState 0;
BA_ "Confidence" SG_ 646 DI_brakeStandActive 0;
BA_ "Confidence" SG_ 646 DI_regenBackfillState 0;
BA_ "Confidence" SG_ 646 DI_cruiseNotAvailableReason 0;
BA_ "GenSigSNA" SG_ 646 DI_cruiseNotAvailableReason "20";
BA_ "Confidence" SG_ 646 DI_cruiseFaultReason 0;
BA_ "GenSigSNA" SG_ 646 DI_cruiseFaultReason "17";
BA_ "Confidence" SG_ 646 DI_cruiseCancelReason 0;
BA_ "Confidence" SG_ 1270 DI_locStatus2Checksum 0;
BA_ "Confidence" SG_ 1270 DI_locStatus2Counter 0;
BA_ "Confidence" SG_ 1270 DI_doublePedalState 0;
BA_ "Confidence" SG_ 1270 DI_autopilotRequest 0;
BA_ "Confidence" SG_ 1270 DI_rollPreventionState 0;
BA_ "Confidence" SG_ 1270 DI_locIntegratorSaturated 0;
BA_ "Confidence" SG_ 1270 DI_temporaryOpdActiveAfterLoncCa 0;
BA_ "SystemSignalLongSymbol" SG_ 1270 DI_temporaryOpdActiveAfterLoncCa "DI_temporaryOpdActiveAfterLoncCancel";
BA_ "Confidence" SG_ 1270 DI_reapplyOnParkRequest 0;
BA_ "Confidence" SG_ 1270 DI_veDegradedAtStandstill 0;
BA_ "Confidence" SG_ 1270 DI_brakeCpScale 0;
BA_ "Confidence" SG_ 1270 DI_rollbackDistance 0;
BA_ "Confidence" SG_ 1270 DI_lowMuProbabilityConfidence 0;
BA_ "Confidence" SG_ 1270 DI_pedalAssistCurveSelectForSX 0;
BA_ "Confidence" SG_ 1270 DI_longitudinalControlStack 0;
BA_ "GenSigSNA" SG_ 1270 DI_longitudinalControlStack "0";
BA_ "Confidence" SG_ 1270 DI_useDasFallbackBrakeCommands 0;
BA_ "Confidence" SG_ 1270 DI_regenBlendingState 0;
BA_ "Confidence" SG_ 1270 DI_executeBatLocStatus2 0;
BA_ "Confidence" SG_ 822 DI_sysDrivePowerRated 0;
BA_ "GenSigSNA" SG_ 822 DI_sysDrivePowerRated "511";
BA_ "Confidence" SG_ 822 DI_performancePackage 0;
BA_ "GenSigSNA" SG_ 822 DI_performancePackage "7";
BA_ "Confidence" SG_ 822 DI_sysRegenPowerRated 0;
BA_ "GenSigSNA" SG_ 822 DI_sysRegenPowerRated "255";
BA_ "Confidence" SG_ 950 DI_odometer 0;
BA_ "GenSigSNA" SG_ 950 DI_odometer "4294967295";
BA_ "Confidence" SG_ 950 DI_obdDriveCycleStatus 0;
BA_ "Confidence" SG_ 950 DI_odometerStatusCounter 0;
BA_ "Confidence" SG_ 950 DI_odometerStatusChecksum 0;
BA_ "Confidence" SG_ 599 DI_speedChecksum 0;
BA_ "Confidence" SG_ 599 DI_speedCounter 0;
BA_ "Confidence" SG_ 599 DI_locSpeedEst 0;
BA_ "GenSigSNA" SG_ 599 DI_locSpeedEst "4095";
BA_ "Confidence" SG_ 599 DI_uiSpeed 0;
BA_ "GenSigSNA" SG_ 599 DI_uiSpeed "511";
BA_ "Confidence" SG_ 599 DI_uiSpeedUnits 0;
BA_ "Confidence" SG_ 599 DI_accelPedalPressed 0;
BA_ "Confidence" SG_ 599 DI_sideslipEstimate 0;
BA_ "Confidence" SG_ 599 DI_vehicleSpeed 0;
BA_ "GenSigSNA" SG_ 599 DI_vehicleSpeed "8191";
BA_ "Confidence" SG_ 599 DI_velocityEstimatorState 0;
BA_ "Confidence" SG_ 599 DI_autoEnableHazards 0;
BA_ "Confidence" SG_ 599 DI_longControlCommandActive 0;
BA_ "Confidence" SG_ 2006 DI_stalklessInterfacesChecksum 0;
BA_ "Confidence" SG_ 2006 DI_stalklessInterfacesCounter 0;
BA_ "Confidence" SG_ 2006 DI_smartShiftClosureOpen 0;
BA_ "Confidence" SG_ 2006 DI_smartShiftSeatbeltUnbuckled 0;
BA_ "Confidence" SG_ 2006 DI_smartShiftAvailable 0;
BA_ "Confidence" SG_ 2006 DI_smartShiftPrimed 0;
BA_ "Confidence" SG_ 2006 DI_smartShiftBrakePressed 0;
BA_ "Confidence" SG_ 2006 DI_smartShiftBrakeReapplyRequire 0;
BA_ "SystemSignalLongSymbol" SG_ 2006 DI_smartShiftBrakeReapplyRequire "DI_smartShiftBrakeReapplyRequired";
BA_ "Confidence" SG_ 597 DI_lastQualifiedGear 0;
BA_ "GenSigSNA" SG_ 597 DI_lastQualifiedGear "7";
BA_ "Confidence" SG_ 597 DI_lastDrivingGear 0;
BA_ "GenSigSNA" SG_ 597 DI_lastDrivingGear "7";
BA_ "Confidence" SG_ 597 DI_distDrivenInGear 0;
BA_ "Confidence" SG_ 597 DI_frontBlocked 0;
BA_ "Confidence" SG_ 597 DI_rearBlocked 0;
BA_ "Confidence" SG_ 597 DI_firstShiftOccurred 0;
BA_ "Confidence" SG_ 597 DI_suggestedGearReason 0;
BA_ "Confidence" SG_ 597 DI_parallelParked 0;
BA_ "Confidence" SG_ 597 DI_smartShiftGear 0;
BA_ "Confidence" SG_ 597 DI_smartShiftUnavailableReason 0;
BA_ "GenSigSNA" SG_ 597 DI_smartShiftUnavailableReason "0";
BA_ "Confidence" SG_ 296 DI_limitRegenPower 0;
BA_ "Confidence" SG_ 296 DI_limitIBat 0;
BA_ "Confidence" SG_ 296 DI_limitVBatLow 0;
BA_ "Confidence" SG_ 296 DI_limitVBatHigh 0;
BA_ "Confidence" SG_ 296 DI_limitObstacleDetection 0;
BA_ "Confidence" SG_ 296 DI_limitSystemLimp 0;
BA_ "Confidence" SG_ 296 DI_limitSystemGPO 0;
BA_ "Confidence" SG_ 296 DI_limitShift 0;
BA_ "Confidence" SG_ 296 DI_limitDriveTorque 0;
BA_ "Confidence" SG_ 296 DI_limitRegenTorque 0;
BA_ "Confidence" SG_ 296 DI_limitVehicleSpeed 0;
BA_ "Confidence" SG_ 296 DI_limitBmsMiaFreeze 0;
BA_ "Confidence" SG_ 296 DI_limitSystemSpinDownLearning 0;
BA_ "Confidence" SG_ 296 DI_limitCdp 0;
BA_ "Confidence" SG_ 296 DI_vehicleSpeedLimitType 0;
BA_ "Confidence" SG_ 296 DI_vehicleSpeedLimit 0;
BA_ "GenSigSNA" SG_ 296 DI_vehicleSpeedLimit "511";
BA_ "Confidence" SG_ 296 DI_vehicleSpeedLimitReason 0;
BA_ "Confidence" SG_ 296 DI_proximity 0;
BA_ "Confidence" SG_ 296 DI_limitClosureNotClosed 0;
BA_ "Confidence" SG_ 296 DI_undersideAbuse 0;
BA_ "Confidence" SG_ 296 DI_immobilizerAuthLevel 0;
BA_ "Confidence" SG_ 296 DI_manualRecoveryDistanceRemaini 0;
BA_ "GenSigSNA" SG_ 296 DI_manualRecoveryDistanceRemaini "127";
BA_ "SystemSignalLongSymbol" SG_ 296 DI_manualRecoveryDistanceRemaini "DI_manualRecoveryDistanceRemaining";
BA_ "Confidence" SG_ 296 DI_restrictedDrivingMode 0;
BA_ "Confidence" SG_ 616 DI_sysHeatPowerMax 0;
BA_ "Confidence" SG_ 616 DI_sysHeatPowerActual 0;
BA_ "Confidence" SG_ 616 DI_sysDrivePowerMax 0;
BA_ "GenSigSNA" SG_ 616 DI_sysDrivePowerMax "511";
BA_ "Confidence" SG_ 616 DI_primaryUnitSiliconType 0;
BA_ "Confidence" SG_ 616 DI_sysRegenPowerMax 0;
BA_ "GenSigSNA" SG_ 616 DI_sysRegenPowerMax "255";
BA_ "Confidence" SG_ 280 DI_systemStatusChecksum 0;
BA_ "Confidence" SG_ 280 DI_systemStatusCounter 0;
BA_ "Confidence" SG_ 280 DI_secondaryGearControlStatus 0;
BA_ "Confidence" SG_ 280 DI_immobilizerState 0;
BA_ "GenSigSNA" SG_ 280 DI_immobilizerState "0";
BA_ "Confidence" SG_ 280 DI_systemState 0;
BA_ "Confidence" SG_ 280 DI_brakePedalState 0;
BA_ "Confidence" SG_ 280 DI_gear 0;
BA_ "GenSigSNA" SG_ 280 DI_gear "7";
BA_ "Confidence" SG_ 280 DI_driveBlocked 0;
BA_ "Confidence" SG_ 280 DI_hvilSystemStatus 0;
BA_ "GenSigSNA" SG_ 280 DI_hvilSystemStatus "3";
BA_ "Confidence" SG_ 280 DI_driveModeState 0;
BA_ "Confidence" SG_ 280 DI_shiftRequestType 0;
BA_ "Confidence" SG_ 280 DI_accelPedalPos 0;
BA_ "GenSigSNA" SG_ 280 DI_accelPedalPos "255";
BA_ "Confidence" SG_ 280 DI_tractionControlMode 0;
BA_ "Confidence" SG_ 280 DI_dynoModeAvailable 0;
BA_ "Confidence" SG_ 280 DI_epbRequest 0;
BA_ "Confidence" SG_ 280 DI_brakeSource 0;
BA_ "Confidence" SG_ 280 DI_keepDrivePowerStateRequest 0;
BA_ "Confidence" SG_ 280 DI_trackModeState 0;
BA_ "Confidence" SG_ 280 DI_autonomyControlActive 0;
BA_ "Confidence" SG_ 280 DI_regenLight 0;
BA_ "Confidence" SG_ 280 DI_vehicleAcceleration 0;
BA_ "GenSigSNA" SG_ 280 DI_vehicleAcceleration "2048";
BA_ "Confidence" SG_ 2036 DI_vdcRightChecksum 0;
BA_ "Confidence" SG_ 2036 DI_vdcRightCounter 0;
BA_ "Confidence" SG_ 2036 DI_vdcCommandTypeFrR 0;
BA_ "Confidence" SG_ 2036 DI_vdcCommandTypeReR 0;
BA_ "Confidence" SG_ 2036 DI_vdcCommandABSFrR 0;
BA_ "Confidence" SG_ 2036 DI_vdcCommandABSReR 0;
BA_ "Confidence" SG_ 2036 DI_brakeTorqueTarFrR 0;
BA_ "Confidence" SG_ 2036 DI_brakeTorqueTarReR 0;
BA_ "Confidence" SG_ 2036 DI_wheelSlipLimitFrR 0;
BA_ "Confidence" SG_ 2036 DI_wheelSlipLimitReR 0;
BA_ "Confidence" SG_ 2036 DI_rawLowMuProbability 0;
BA_ "Confidence" SG_ 615 DI_mass 0;
BA_ "Confidence" SG_ 615 DI_massRLS 0;
BA_ "Confidence" SG_ 615 DI_trailerDetected 0;
BA_ "Confidence" SG_ 615 DI_vehicleEstimatesCounter 0;
BA_ "Confidence" SG_ 615 DI_relativeTireTreadDepth 0;
BA_ "GenSigSNA" SG_ 615 DI_relativeTireTreadDepth "32";
BA_ "Confidence" SG_ 615 DI_tireFitment 0;
BA_ "GenSigSNA" SG_ 615 DI_tireFitment "3";
BA_ "Confidence" SG_ 615 DI_rollCoeff 0;
BA_ "Confidence" SG_ 615 DI_massConfidence 0;
BA_ "Confidence" SG_ 615 DI_gradeEst 0;
BA_ "Confidence" SG_ 615 DI_vehicleEstimatesChecksum 0;
BA_ "Confidence" SG_ 615 DI_gradeEstInternal 0;
BA_ "Confidence" SG_ 615 DI_massConfidenceRLS 0;
BA_ "Confidence" SG_ 615 DI_steeringAngleOffset 0;
BA_ "Confidence" SG_ 1237 DPB_alertID 1;
BA_ "Confidence" SG_ 1237 DPB_alertState 1;
BA_ "Confidence" SG_ 999 DPB_matrixIndex 1;
BA_ "SystemSignalLongSymbol" SG_ 999 DPB_a001_pPlungerSensorOffsetHig "DPB_a001_pPlungerSensorOffsetHigh";
BA_ "SystemSignalLongSymbol" SG_ 999 DPB_a018_largeLeakageDetectedGoo "DPB_a018_largeLeakageDetectedGoodCheck";
BA_ "SystemSignalLongSymbol" SG_ 999 DPB_a023_initialPlungerCheckFail "DPB_a023_initialPlungerCheckFailed";
BA_ "SystemSignalLongSymbol" SG_ 999 DPB_a035_PDURouterinitialization "DPB_a035_PDURouterinitializationFailed";
BA_ "SystemSignalLongSymbol" SG_ 999 DPB_a036_lossOfPDUInstanceDetect "DPB_a036_lossOfPDUInstanceDetected";
BA_ "SystemSignalLongSymbol" SG_ 999 DPB_a038_plungerCircuitPressHigh "DPB_a038_plungerCircuitPressHighGoodCheck";
BA_ "SystemSignalLongSymbol" SG_ 999 DPB_a040_plungerCircuitPressLowG "DPB_a040_plungerCircuitPressLowGoodCheck";
BA_ "SystemSignalLongSymbol" SG_ 999 DPB_a042_motorLoadPressImplausib "DPB_a042_motorLoadPressImplausible";
BA_ "SystemSignalLongSymbol" SG_ 999 DPB_a047_pPlungerPlausCheckFailu "DPB_a047_pPlungerPlausCheckFailure";
BA_ "SystemSignalLongSymbol" SG_ 999 DPB_a053_hydraulicAssemblyModeAc "DPB_a053_hydraulicAssemblyModeActive";
BA_ "SystemSignalLongSymbol" SG_ 999 DPB_a055_unsupportedSeriesHWDete "DPB_a055_unsupportedSeriesHWDetected";
BA_ "SystemSignalLongSymbol" SG_ 999 DPB_a085_infoFailureWrongCUBASHa "DPB_a085_infoFailureWrongCUBASHandlingDetected";
BA_ "SystemSignalLongSymbol" SG_ 999 DPB_a086_diagHydProtectionPressF "DPB_a086_diagHydProtectionPressFault";
BA_ "SystemSignalLongSymbol" SG_ 999 DPB_a087_diagHydProtectionVlvFau "DPB_a087_diagHydProtectionVlvFault";
BA_ "SystemSignalLongSymbol" SG_ 999 DPB_a111_hydraulicHardUndervolta "DPB_a111_hydraulicHardUndervoltage";
BA_ "SystemSignalLongSymbol" SG_ 999 DPB_a127_hydraulicAsicShortCircu "DPB_a127_hydraulicAsicShortCircuit";
BA_ "SystemSignalLongSymbol" SG_ 999 DPB_a129_AsicTrimmingNotComplete "DPB_a129_AsicTrimmingNotCompleted";
BA_ "SystemSignalLongSymbol" SG_ 999 DPB_a131_ASICOvercurrentOnGPIO25 "DPB_a131_ASICOvercurrentOnGPIO250_1";
BA_ "SystemSignalLongSymbol" SG_ 999 DPB_a132_ASICOvercurrentOnGPIO25 "DPB_a132_ASICOvercurrentOnGPIO250_2";
BA_ "SystemSignalLongSymbol" SG_ 999 DPB_a133_ASICOvercurrentOnGPIO50 "DPB_a133_ASICOvercurrentOnGPIO50_1";
BA_ "SystemSignalLongSymbol" SG_ 999 DPB_a134_ASICOvercurrentOnGPIO50 "DPB_a134_ASICOvercurrentOnGPIO50_2";
BA_ "SystemSignalLongSymbol" SG_ 999 DPB_a135_ASICOvercurrentOnGPIO50 "DPB_a135_ASICOvercurrentOnGPIO50_3";
BA_ "SystemSignalLongSymbol" SG_ 999 DPB_a136_ASICOvercurrentOnGPIO50 "DPB_a136_ASICOvercurrentOnGPIO50_4";
BA_ "SystemSignalLongSymbol" SG_ 999 DPB_a139_DIchassisControlChecksu "DPB_a139_DIchassisControlChecksum";
BA_ "SystemSignalLongSymbol" SG_ 999 DPB_a191_VCLEFTepbmStatusChecksu "DPB_a191_VCLEFTepbmStatusChecksum";
BA_ "SystemSignalLongSymbol" SG_ 999 DPB_a194_VCRIGHTepbmStatusCounte "DPB_a194_VCRIGHTepbmStatusCounter";
BA_ "SystemSignalLongSymbol" SG_ 999 DPB_a195_VCRIGHTepbmStatusChecks "DPB_a195_VCRIGHTepbmStatusChecksum";
BA_ "SystemSignalLongSymbol" SG_ 999 DPB_a197_VCRIGHTepbmStatusTimeou "DPB_a197_VCRIGHTepbmStatusTimeout";
BA_ "SystemSignalLongSymbol" SG_ 999 DPB_a200_ESPRunoutSupportNotAvai "DPB_a200_ESPRunoutSupportNotAvailable";
BA_ "SystemSignalLongSymbol" SG_ 999 DPB_a202_vehicleStandstillQFault "DPB_a202_vehicleStandstillQFaulty";
BA_ "SystemSignalLongSymbol" SG_ 999 DPB_a220_excessiveBoostWakeupsDe "DPB_a220_excessiveBoostWakeupsDetected";
BA_ "SystemSignalLongSymbol" SG_ 999 DPB_a222_excessiveEcuResetsDetec "DPB_a222_excessiveEcuResetsDetected";
BA_ "SystemSignalLongSymbol" SG_ 999 DPB_a242_uCSafetyNotificationGRA "DPB_a242_uCSafetyNotificationGRAM";
BA_ "SystemSignalLongSymbol" SG_ 999 DPB_a256_valveRelayActuationFaul "DPB_a256_valveRelayActuationFault";
BA_ "SystemSignalLongSymbol" SG_ 999 DPB_a259_valveRelayTestUndervolt "DPB_a259_valveRelayTestUndervoltage";
BA_ "SystemSignalLongSymbol" SG_ 999 DPB_a260_valveRelaySafetySwitchF "DPB_a260_valveRelaySafetySwitchFault";
BA_ "SystemSignalLongSymbol" SG_ 999 DPB_a292_CBDS_fillBufferThreshol "DPB_a292_CBDS_fillBufferThreshold";
BA_ "SystemSignalLongSymbol" SG_ 999 DPB_a298_runningPlungerCircuitTe "DPB_a298_runningPlungerCircuitTest";
BA_ "SystemSignalLongSymbol" SG_ 999 DPB_a303_actuatingDIFullTorqueCm "DPB_a303_actuatingDIFullTorqueCmd";
BA_ "SystemSignalLongSymbol" SG_ 999 DPB_a305_DIbrakeTorqueCommandAnd "DPB_a305_DIbrakeTorqueCommandAndFlagMismatch";
BA_ "SystemSignalLongSymbol" SG_ 999 DPB_a306_actuatorFallbackBasicMa "DPB_a306_actuatorFallbackBasicMap";
BA_ "SystemSignalLongSymbol" SG_ 999 DPB_a312_continuouslyActivatedVa "DPB_a312_continuouslyActivatedValvesOff";
BA_ "SystemSignalLongSymbol" SG_ 999 DPB_a313_qualifiedBrakeEventDete "DPB_a313_qualifiedBrakeEventDetected";
BA_ "SystemSignalLongSymbol" SG_ 999 DPB_a314_runningCyclicVolumeChec "DPB_a314_runningCyclicVolumeCheck";
BA_ "SystemSignalLongSymbol" SG_ 999 DPB_a315_runningLeakageAndAirMon "DPB_a315_runningLeakageAndAirMonitoring";
BA_ "SystemSignalLongSymbol" SG_ 999 DPB_a316_lowBrakeFluidDetectedOn "DPB_a316_lowBrakeFluidDetectedOnHillSlope";
BA_ "SystemSignalLongSymbol" SG_ 999 DPB_a317_DASredundantBrakingCont "DPB_a317_DASredundantBrakingControlPartyChecksum";
BA_ "SystemSignalLongSymbol" SG_ 999 DPB_a318_DASredundantBrakingCont "DPB_a318_DASredundantBrakingControlPartyCounter";
BA_ "SystemSignalLongSymbol" SG_ 999 DPB_a319_DASredundantBrakingCont "DPB_a319_DASredundantBrakingControlPartyDLC";
BA_ "SystemSignalLongSymbol" SG_ 999 DPB_a320_DASredundantBrakingCont "DPB_a320_DASredundantBrakingControlPartyTimeout";
BA_ "SystemSignalLongSymbol" SG_ 999 DPB_a321_DASredundantBrakingCont "DPB_a321_DASredundantBrakingControlChassisChecksum";
BA_ "SystemSignalLongSymbol" SG_ 999 DPB_a322_DASredundantBrakingCont "DPB_a322_DASredundantBrakingControlChassisCounter";
BA_ "SystemSignalLongSymbol" SG_ 999 DPB_a323_DASredundantBrakingCont "DPB_a323_DASredundantBrakingControlChassisDLC";
BA_ "SystemSignalLongSymbol" SG_ 999 DPB_a324_DASredundantBrakingCont "DPB_a324_DASredundantBrakingControlChassisTimeout";
BA_ "Confidence" SG_ 1426 EPAS3P_alertID 1;
BA_ "Confidence" SG_ 1426 EPAS3P_alertState 1;
BA_ "Confidence" SG_ 1426 EPAS3P_a147_transitionReason 1;
BA_ "Confidence" SG_ 1426 EPAS3P_a149_pcbTemp 1;
BA_ "Confidence" SG_ 1426 EPAS3P_a150_pcbTemp 1;
BA_ "Confidence" SG_ 1426 EPAS3P_a150_phaUMainPathCalcDiff 1;
BA_ "Confidence" SG_ 1426 EPAS3P_a150_phaVMainPathCalcDiff 1;
BA_ "SystemSignalLongSymbol" SG_ 1426 EPAS3P_a150_otherECUAssistStatus "EPAS3P_a150_otherECUAssistStatusFlag";
BA_ "Confidence" SG_ 1426 EPAS3P_a155_vehicleSpeed 1;
BA_ "Confidence" SG_ 1426 EPAS3P_a156_vehicleSpeed 1;
BA_ "Confidence" SG_ 1426 EPAS3P_a160_currentSensorStatus 1;
BA_ "Confidence" SG_ 1426 EPAS3P_a160_gateDriverStatus 1;
BA_ "Confidence" SG_ 1426 EPAS3P_a160_highSideDisconnectFe 1;
BA_ "SystemSignalLongSymbol" SG_ 1426 EPAS3P_a160_highSideDisconnectFe "EPAS3P_a160_highSideDisconnectFetStatus";
BA_ "Confidence" SG_ 1426 EPAS3P_a160_phaseDisconnectFetSt 1;
BA_ "SystemSignalLongSymbol" SG_ 1426 EPAS3P_a160_phaseDisconnectFetSt "EPAS3P_a160_phaseDisconnectFetStatus";
BA_ "Confidence" SG_ 1426 EPAS3P_a160_inverterFetStatus 1;
BA_ "Confidence" SG_ 1426 EPAS3P_a160_hsdFetFailShortTest 1;
BA_ "Confidence" SG_ 1426 EPAS3P_a160_phaDisconnFailOpenTe 1;
BA_ "SystemSignalLongSymbol" SG_ 1426 EPAS3P_a160_phaDisconnFailOpenTe "EPAS3P_a160_phaDisconnFailOpenTest";
BA_ "Confidence" SG_ 1426 EPAS3P_a160_phaDisconnFailShortT 1;
BA_ "SystemSignalLongSymbol" SG_ 1426 EPAS3P_a160_phaDisconnFailShortT "EPAS3P_a160_phaDisconnFailShortTest";
BA_ "Confidence" SG_ 1426 EPAS3P_a160_invFetInitTest 1;
BA_ "Confidence" SG_ 1426 EPAS3P_a160_gateDrvrInitTest 1;
BA_ "SystemSignalLongSymbol" SG_ 1426 EPAS3P_a160_latentFaultTestTimeo "EPAS3P_a160_latentFaultTestTimeout";
BA_ "Confidence" SG_ 1426 EPAS3P_a161_pcoMinPhaseBCurrent 1;
BA_ "Confidence" SG_ 1426 EPAS3P_a161_pcoMaxPhaseBCurrent 1;
BA_ "Confidence" SG_ 1426 EPAS3P_a161_pcoMinPhaseACurrent 1;
BA_ "Confidence" SG_ 1426 EPAS3P_a161_pcoMaxPhaseACurrent 1;
BA_ "Confidence" SG_ 1426 EPAS3P_a162_vBridgeClosed 1;
BA_ "Confidence" SG_ 1426 EPAS3P_a162_vBridgeOpen 1;
BA_ "Confidence" SG_ 1426 EPAS3P_a163_gateDrvrStatusReg 1;
BA_ "Confidence" SG_ 1426 EPAS3P_a163_gateDrvrDiag2Reg 1;
BA_ "Confidence" SG_ 1426 EPAS3P_a163_gateDrvrDiag1Reg 1;
BA_ "Confidence" SG_ 1426 EPAS3P_a163_gateDrvrDiag0Reg 1;
BA_ "Confidence" SG_ 1426 EPAS3P_a164_dcsRegister0x19 1;
VAL_ 871 DI_matrixIndex 4 "AlertMatrix4" 3 "AlertMatrix3" 2 "AlertMatrix2" 1 "AlertMatrix1" 0 "AlertMatrix0" ;
VAL_ 84 DI_autonomyBehavior 2 "DRIVERLESS_NO_TAKEOVER" 1 "DRIVERLESS_TAKEOVER" 0 "DRIVER" ;
VAL_ 84 DI_ah_timeToNoPropulsion 4095 "INDEFINITE" ;
VAL_ 84 DI_loncDegradedReason 10 "DI_LONC_DEGRADED_REDUNDANT_BRAKES_ACTIVE" 9 "DI_LONC_DEGRADED_ABS_UNAVAILABLE" 8 "DI_LONC_DEGRADED_ESP_MIA" 7 "DI_LONC_DEGRADED_BRAKE_INVALID" 6 "DI_LONC_DEGRADED_VELOCITY_ESTIMATE_NOT_NORMAL" 5 "DI_LONC_DEGRADED_EBR" 4 "DI_LONC_DEGRADED_VDC_FAULT" 3 "DI_LONC_DEGRADED_TC_FAULT" 2 "DI_LONC_DEGRADED_VHLD_UNAVAILABLE" 1 "DI_LONC_DEGRADED_VHLD_FAULTED" 0 "DI_LONC_DEGRADED_NONE" ;
VAL_ 328 DI_imuOffsetLearnRequest 2 "IMU_FAST_LEARNING_TIME" 1 "IMU_SLOW_LEARNING_DISTANCE" 0 "IMU_OFFSET_LEARNING_OFF" ;
VAL_ 328 DI_brakeCommandType 1 "QUIET" 0 "FAST" ;
VAL_ 328 DI_brakeTorqueRequestActive 1 "ACTIVE" 0 "INACTIVE" ;
VAL_ 328 DI_ptcStateGlobal 3 "GLOBAL_PTC_STATE_SNA" 2 "GLOBAL_PTC_STATE_ON" 1 "GLOBAL_PTC_STATE_BACKUP" 0 "GLOBAL_PTC_STATE_FAULTED" ;
VAL_ 328 DI_ptcActive 1 "ACTIVE" 0 "INACTIVE" ;
VAL_ 328 DI_vdcState 3 "VDC_STATE_STARTUP" 2 "VDC_STATE_NORMAL" 1 "VDC_STATE_BACKUP_A" 0 "VDC_STATE_FAULTED" ;
VAL_ 328 DI_isAnyVdcControlActive 2 "UNUSED_VALUE" 1 "VDC_CONTROL_ACTIVE" 0 "VDC_NO_CONTROL_ACTIVE" ;
VAL_ 328 DI_vdcMode 2 "VDC_MODE_TRACK" 1 "VDC_MODE_ON" 0 "VDC_MODE_OFF" ;
VAL_ 328 DI_pedalAssistCurveSelect 15 "PEDAL_ASSIST_CURVE_15" 12 "PEDAL_ASSIST_CURVE_12" 11 "PEDAL_ASSIST_CURVE_11" 8 "PEDAL_ASSIST_CURVE_8" 6 "PEDAL_ASSIST_CURVE_6" 3 "PEDAL_ASSIST_CURVE_3" 0 "PEDAL_ASSIST_CURVE_0" ;
VAL_ 328 DI_isAnyTcActive 1 "ACTIVE" 0 "INACTIVE" ;
VAL_ 328 DI_vdcControlActive 4 "VDC_DECEL_ACTIVE" 3 "VDC_TRAILER_SWAY_ACTIVE" 2 "VDC_UNDERSTEER_ACTIVE" 1 "VDC_OVERSTEER_ACTIVE" 0 "VDC_NOT_ACTIVE" ;
VAL_ 328 DI_treadDepthAlertSet 1 "TRUE" 0 "FALSE" ;
VAL_ 1861 DI_chassisControlVideoRequest 15 "CHASSIS_CONTROL_EVENT_15" 14 "CHASSIS_CONTROL_EVENT_14" 13 "CHASSIS_CONTROL_EVENT_13" 12 "CHASSIS_CONTROL_EVENT_12" 11 "CHASSIS_CONTROL_EVENT_11" 10 "CHASSIS_CONTROL_EVENT_10" 9 "CHASSIS_CONTROL_EVENT_9" 8 "CHASSIS_CONTROL_EVENT_8" 7 "CHASSIS_CONTROL_EVENT_7" 6 "CHASSIS_CONTROL_EVENT_6" 5 "CHASSIS_CONTROL_EVENT_5" 4 "CHASSIS_CONTROL_EVENT_4" 3 "CHASSIS_CONTROL_EVENT_3" 2 "CHASSIS_CONTROL_EVENT_2" 1 "CHASSIS_CONTROL_EVENT_1" 0 "CHASSIS_CONTROL_EVENT_NONE" ;
VAL_ 1861 DI_counterSteerTarget 2 "EXPIRED" 1 "ACTIVE" 0 "INACTIVE" ;
VAL_ 1861 DI_turnDirection 1 "VDC_TURNING_LEFT" 0 "VDC_TURNING_RIGHT" ;
VAL_ 1861 DI_oppositeBuildDirFrontAxle 1 "TRUE" 0 "FALSE" ;
VAL_ 1861 DI_oppositeBuildDirRearAxle 1 "TRUE" 0 "FALSE" ;
VAL_ 1861 DI_saturatedEffectiveness 1 "TRUE" 0 "FALSE" ;
VAL_ 1861 DI_preControlOpposingTurnDir 1 "TRUE" 0 "FALSE" ;
VAL_ 1869 DI_kTireEstReUnSat 127 "SNA" ;
VAL_ 1869 DI_distanceSinceLastTireConfig 63 "SNA" ;
VAL_ 1869 DI_kTireEstRe 31 "SNA" ;
VAL_ 694 DI_vdcTelltaleFlash 1 "TELLTALE_ON" 0 "TELLTALE_OFF" ;
VAL_ 694 DI_vdcTelltaleOn 1 "TELLTALE_ON" 0 "TELLTALE_OFF" ;
VAL_ 694 DI_tcTelltaleFlash 1 "TELLTALE_ON" 0 "TELLTALE_OFF" ;
VAL_ 694 DI_tcTelltaleOn 1 "TELLTALE_ON" 0 "TELLTALE_OFF" ;
VAL_ 694 DI_tractionControlModeUI 7 "TC_SLIPPERY_SURFACE" 6 "TC_OFFROAD_ASSIST" 5 "TC_DYNO_MODE" 4 "TC_ROLLS_MODE" 3 "TC_DEV_MODE_2" 2 "TC_DEV_MODE_1" 1 "TC_SLIP_START" 0 "TC_NORMAL" ;
VAL_ 694 DI_ptcStateGlobalUI 3 "GLOBAL_PTC_STATE_SNA" 2 "GLOBAL_PTC_STATE_ON" 1 "GLOBAL_PTC_STATE_BACKUP" 0 "GLOBAL_PTC_STATE_FAULTED" ;
VAL_ 694 DI_btcStateUI 1 "ON" 0 "OFF" ;
VAL_ 694 DI_vehicleHoldTelltaleOn 1 "TELLTALE_ON" 0 "TELLTALE_OFF" ;
VAL_ 694 DI_slipperySurfaceOnUI 1 "SLIPPERY_SURFACE_ON" 0 "SLIPPERY_SURFACE_OFF" ;
VAL_ 694 DI_yellowBrakeTelltaleOn 1 "TELLTALE_ON" 0 "TELLTALE_OFF" ;
VAL_ 694 DI_greenABSTelltaleOn 1 "TELLTALE_ON" 0 "TELLTALE_OFF" ;
VAL_ 694 DI_stabilityModeState 2 "REDUCED" 1 "NORMAL" 0 "UNAVAILABLE" ;
VAL_ 2007 DI_debugSelector 75 "longControl" 69 "Mux69" 68 "Mux68" 67 "Mux67" 66 "Mux66" 65 "Mux65" 53 "Mux53" 50 "sysHeat" 45 "aeb" 39 "regenBackfill" 38 "pedalTorque1" 37 "onePedalDriving3" 36 "onePedalDriving2" 35 "onePedalDriving1" 34 "sysPedal" 33 "Mux33" 32 "pwrSat" 2 "Mux2" ;
VAL_ 2007 DI_regenBackfillUnavailableReaso 18 "DI_LATENT_FAULT_TRIP" 17 "EBR_FULL_FAULT" 16 "PM_DISABLE_REQUEST_BPED" 15 "PM_DISABLE_REQUEST_BLEND" 14 "CARBON_CERAMIC_BRAKES" 13 "BRAKE_TEMP" 12 "EBR_FAULT" 11 "PM_DISABLE_REQUEST" 10 "TRACK_MODE_ACTIVE" 9 "VELOCITY_ESTIMATOR_UNAVAILABLE" 8 "TRACTION_CONTROL_UNAVAILABLE" 7 "ACTIVE_DAMPING_UNAVAILABLE" 6 "UI_COASTDOWN_MODE" 5 "SYSTEM_STATE" 4 "NON_DRIVE_GEAR" 3 "EBR_UNAVAILABLE" 2 "UI_DISABLE" 1 "GTW_DISABLE" 0 "NONE" ;
VAL_ 2007 DI_regenBackfillAbsSatState 2 "RAMP_IN" 1 "RAMP_OUT" 0 "IDLE" ;
VAL_ 1866 DI_brakeFLTemp 1023 "SNA" ;
VAL_ 1866 DI_brakeFRTemp 1023 "SNA" ;
VAL_ 1866 DI_brakeRLTemp 1023 "SNA" ;
VAL_ 1866 DI_brakeRRTemp 1023 "SNA" ;
VAL_ 1623 DI_infoIndex 255 "INFO_END" 44 "TRACKING_DATA_5" 43 "TRACKING_DATA_4" 42 "TRACKING_DATA_3" 41 "TRACKING_DATA_2" 40 "TRACKING_DATA_1" 34 "INFO_SUBCOMPONENT2_HWID" 33 "INFO_SUBCOMPONENT_HWID" 32 "INFO_SUBCOMPONENT2_GITHASH" 31 "INFO_SUBCOMPONENT_GITHASH" 23 "INFO_SUBCOMPONENT2" 20 "INFO_UDS_PROTOCOL_BOOTCRC" 19 "INFO_VERSION_DEPRECATED" 18 "INFO_BOOTLOADER_GITHASH" 17 "INFO_APP_GITHASH" 16 "INFO_SUBCOMPONENT" 15 "INFO_BOOTLOADER_CRC" 14 "INFO_BOOTLOADER_SVN" 13 "INFO_APP_CRC" 11 "INFO_PCBAID_ASSYID_USAGEID" 10 "INFO_BUILD_HWID_COMPONENTID" 9 "INFO_DEPRECATED_9" 8 "INFO_DEPRECATED_8" 7 "INFO_DEPRECATED_7" 6 "INFO_DEPRECATED_6" 5 "INFO_DEPRECATED_5" 4 "INFO_DEPRECATED_4" 3 "INFO_DEPRECATED_3" 2 "INFO_DEPRECATED_2" 1 "INFO_DEPRECATED_1" 0 "INFO_DEPRECATED_0" ;
VAL_ 1623 DI_buildType 4 "INFO_MFG_BUILD" 3 "INFO_TRACEABLE_CI_BUILD" 2 "INFO_LOCAL_BUILD" 1 "INFO_PLATFORM_BUILD" 0 "INFO_UNKNOWN_BUILD" ;
VAL_ 1623 DI_hardwareId 252 "CONFIGURABLE_HWID_PLACEHOLDER" ;
VAL_ 646 DI_cruiseState 7 "CRS_STATE_PRE_CANCEL" 6 "CRS_STATE_PRE_FAULT" 5 "CRS_STATE_FAULT" 4 "CRS_STATE_OVERRIDE" 3 "CRS_STATE_STANDSTILL" 2 "CRS_STATE_ENABLED" 1 "CRS_STATE_STANDBY" 0 "CRS_STATE_UNAVAILABLE" ;
VAL_ 646 DI_cruiseSetSpeedUnits 1 "DI_SPEED_KPH" 0 "DI_SPEED_MPH" ;
VAL_ 646 DI_autoparkState 15 "DI_APC_SNA" 9 "DI_APC_SELFPARK_STARTED" 8 "DI_APC_UNPARK_COMPLETE" 7 "DI_APC_RESUMED" 6 "DI_APC_ABORTED" 5 "DI_APC_PAUSED" 4 "DI_APC_COMPLETE" 3 "DI_APC_ACTIVE" 2 "DI_APC_STARTED" 1 "DI_APC_STANDBY" 0 "DI_APC_UNAVAILABLE" ;
VAL_ 646 DI_parkBrakeState 15 "DI_PBRK_SNA" 7 "DI_PBRK_RELEASING" 6 "DI_PBRK_PANIC_SKID" 5 "DI_PBRK_PANIC_EPB" 4 "DI_PBRK_FAULTED" 3 "DI_PBRK_APPLIED" 2 "DI_PBRK_REQUESTED" 1 "DI_PBRK_RELEASED" 0 "DI_PBRK_UNAVAILABLE" ;
VAL_ 646 DI_aebState 7 "AEB_CAN_STATE_SNA" 5 "AEB_CAN_STATE_UNAVAILABLE_ALERT" 4 "AEB_CAN_STATE_FAULT" 3 "AEB_CAN_STATE_STANDSTILL" 2 "AEB_CAN_STATE_ENABLED" 1 "AEB_CAN_STATE_STANDBY" 0 "AEB_CAN_STATE_UNAVAILABLE" ;
VAL_ 646 DI_loncDeactivationReason 3 "ABORT" 2 "DAS_CANCEL" 1 "USER_CANCEL" 0 "NO_CANCEL" ;
VAL_ 646 DI_vehicleHoldState 7 "DI_VHLD_STATE_INIT" 6 "DI_VHLD_STATE_FAULT" 5 "DI_VHLD_STATE_PARK" 4 "DI_VHLD_STATE_BLEND_OUT" 3 "DI_VHLD_STATE_STANDSTILL" 2 "DI_VHLD_STATE_BLEND_IN" 1 "DI_VHLD_STATE_STANDBY" 0 "DI_VHLD_STATE_UNAVAILABLE" ;
VAL_ 646 DI_onePedalDrivingState 8 "DI_OPD_NUM_STATES" 7 "DI_OPD_MOTOR_BLEND_IN" 6 "DI_OPD_NO_MOTOR" 5 "DI_OPD_MOTOR_BLEND_OUT_ACTIVE" 4 "DI_OPD_MOTOR_BLEND_OUT_PENDING" 3 "DI_OPD_NOMINAL" 2 "DI_OPD_STANDBY" 1 "DI_OPD_QUICK_BRAKE_RAMP" 0 "DI_OPD_UNAVAILABLE" ;
VAL_ 646 DI_regenBackfillState 2 "BFILL_ACTIVE" 1 "BFILL_STANDBY" 0 "BFILL_UNAVAILABLE" ;
VAL_ 646 DI_cruiseNotAvailableReason 50 "DI_CRUISE_NOT_AVAILABLE_AIR_COMPRESSOR_FAULT" 49 "DI_CRUISE_NOT_AVAILABLE_ABS_FAULT" 48 "DI_CRUISE_NOT_AVAILABLE_DRIVERLESS_AUTONOMY_BEHAVIOR" 47 "DI_CRUISE_NOT_AVAILABLE_EPB_DYNAMIC_APPLY" 46 "DI_CRUISE_NOT_AVAILABLE_SGS_REQUEST" 45 "DI_CRUISE_NOT_AVAILABLE_VDC_FAULT" 44 "DI_CRUISE_NOT_AVAILABLE_ACCEL_JERK_OUT_OF_ISO_BOUNDS" 43 "DI_CRUISE_NOT_AVAILABLE_REDUNDANT_BRAKES_ACTIVE" 42 "DI_CRUISE_NOT_AVAILABLE_ABS_UNAVAILABLE" 41 "DI_CRUISE_NOT_AVAILABLE_LONC_DEGRADED" 40 "DI_CRUISE_NOT_AVAILABLE_FACTORY_MODE" 39 "DI_CRUISE_NOT_AVAILABLE_EPB_FAULT" 38 "DI_CRUISE_NOT_AVAILABLE_AEB_STACK_UNAVAILABLE" 37 "DI_CRUISE_NOT_AVAILABLE_AEB_STACK_EVENT_INACTIVE" 36 "DI_CRUISE_NOT_AVAILABLE_DFLK_ENGAGED" 35 "DI_CRUISE_NOT_AVAILABLE_INTERFACE_NOT_SUPPORTED" 34 "DI_CRUISE_NOT_AVAILABLE_CANCEL_ACTIVE" 33 "DI_CRUISE_NOT_AVAILABLE_CONTROL_STACK_SWITCH" 32 "DI_CRUISE_NOT_AVAILABLE_SHIFT_OUTSIDE_SPEED_THRESHOLD" 31 "DI_CRUISE_NOT_AVAILABLE_SHIFT_TIMEOUT" 30 "DI_CRUISE_NOT_AVAILABLE_OFFROAD_MODE_ACTIVE" 29 "DI_CRUISE_NOT_AVAILABLE_DAS_CONTROL_MIA" 28 "DI_CRUISE_NOT_AVAILABLE_UNIT0_FAULT" 27 "DI_CRUISE_NOT_AVAILABLE_BRAKE_TEMPERATURE" 26 "DI_CRUISE_NOT_AVAILABLE_ACC_BACKWARD_AT_HIGH_FORWARD_SPEED" 25 "DI_CRUISE_NOT_AVAILABLE_DAS_SET_SPEED_TOO_HIGH_IN_REVERSE" 24 "DI_CRUISE_NOT_AVAILABLE_MOTOR_SPEED_TOO_HIGH_IN_REVERSE" 23 "DI_CRUISE_NOT_AVAILABLE_VHLD_UNAVAILABLE" 22 "DI_CRUISE_NOT_AVAILABLE_CRUISE_FAULTED" 21 "DI_CRUISE_NOT_AVAILABLE_TRACK_MODE_ACTIVE" 20 "DI_CRUISE_NOT_AVAILABLE_DAS_SNA" 19 "DI_CRUISE_NOT_AVAILABLE_UI_MIA" 18 "DI_CRUISE_NOT_AVAILABLE_WAIT_INIT" 17 "DI_CRUISE_NOT_AVAILABLE_VEL_EST" 16 "DI_CRUISE_NOT_AVAILABLE_MAX_SPEED" 15 "DI_CRUISE_NOT_AVAILABLE_MIN_SPEED" 14 "DI_CRUISE_NOT_AVAILABLE_AEB" 13 "DI_CRUISE_NOT_AVAILABLE_CONFIG" 12 "DI_CRUISE_NOT_AVAILABLE_DI_STATE" 11 "DI_CRUISE_NOT_AVAILABLE_MOTOR_SPEED" 10 "DI_CRUISE_NOT_AVAILABLE_EBR" 9 "DI_CRUISE_NOT_AVAILABLE_VALET_MODE" 8 "DI_CRUISE_NOT_AVAILABLE_SEAT_BELT_UNBUCKLED" 7 "DI_CRUISE_NOT_AVAILABLE_CLOSURE_OPEN" 6 "DI_CRUISE_NOT_AVAILABLE_ACC_CANCEL" 5 "DI_CRUISE_NOT_AVAILABLE_ABS_ACTIVE" 4 "DI_CRUISE_NOT_AVAILABLE_TC_ACTIVE" 3 "DI_CRUISE_NOT_AVAILABLE_VDC_ACTIVE_OR_DEGRADED" 2 "DI_CRUISE_NOT_AVAILABLE_VDC_OR_TC_OFF" 1 "DI_CRUISE_NOT_AVAILABLE_NO_ALERT" 0 "DI_CRUISE_NOT_AVAILABLE_NONE" ;
VAL_ 646 DI_cruiseFaultReason 22 "DI_CRUISE_FAULT_VHLD_FAULTED" 21 "DI_CRUISE_FAULT_CONFIG_MISMATCH" 20 "DI_CRUISE_FAULT_EPB_MIA" 19 "DI_CRUISE_FAULT_ACCEL_JERK_OUT_OF_ISO_BOUNDS" 17 "DI_CRUISE_FAULT_DAS_SNA" 16 "DI_CRUISE_FAULT_VELOCITY_ESTIMATE_NOT_NORMAL" 15 "DI_CRUISE_FAULT_ACCEL_OUT_OF_BOUNDS" 14 "DI_CRUISE_FAULT_EBR_FAULT" 13 "DI_CRUISE_FAULT_TC_FAULT" 12 "DI_CRUISE_FAULT_ESP_MIA" 11 "DI_CRUISE_FAULT_VDC_FAULT" 10 "DI_CRUISE_FAULT_EPB_FAULT" 9 "DI_CRUISE_FAULT_BRAKE_MIA" 8 "DI_CRUISE_FAULT_CRS_STATE_MISM" 7 "DI_CRUISE_FAULT_ABS_MIA" 6 "DI_CRUISE_FAULT_CRUISE_SCCM_MIA" 5 "DI_CRUISE_FAULT_BRAKE_INVALID" 4 "DI_CRUISE_FAULT_STALK" 3 "DI_CRUISE_FAULT_PM_REQUEST" 2 "DI_CRUISE_FAULT_PM_MIA" 1 "DI_CRUISE_FAULT_MOTOR_SPEED_MISMATCH" 0 "DI_CRUISE_FAULT_NONE" ;
VAL_ 646 DI_cruiseCancelReason 11 "DI_CRUISE_CANCEL_DAS_MIA_PEDAL_APPLY" 10 "DI_CRUISE_CANCEL_ACC_FSD_EXIT" 9 "DI_CRUISE_CANCEL_SHIFT_REQUEST" 8 "DI_CRUISE_CANCEL_ACCEL_OVERRIDE_IN_REVERSE" 7 "DI_CRUISE_CANCEL_DAS" 6 "DI_CRUISE_CANCEL_PARK" 5 "DI_CRUISE_CANCEL_GEAR" 4 "DI_CRUISE_CANCEL_STALK" 3 "DI_CRUISE_CANCEL_BRAKE" 2 "DI_CRUISE_CANCEL_SKID" 1 "DI_CRUISE_CANCEL_APC_REQUEST" 0 "DI_CRUISE_CANCEL_NONE" ;
VAL_ 1270 DI_doublePedalState 12 "DBL_BRKSTAND_TRQ_RAMPUP_DONE" 11 "DBL_BRKSTAND_LAUNCH" 10 "DBL_BRKSTAND_TRQ_HOLD" 9 "DBL_BRKSTAND_INIT_TRQ_RAMPUP" 8 "DBL_BRKSTAND_ARMED2" 7 "DBL_BRKSTAND_ARMED1" 6 "DBL_BRKOVR_RAMPUP" 5 "DBL_BRKOVR_RAMPDOWN" 4 "DBL_BRKPRESS_PREOVR" 3 "DBL_BRKPRESS_RAMPUP" 2 "DBL_BRKPRESS_RAMPDOWN" 1 "DBL_DRIVING" 0 "DBL_IDLE" ;
VAL_ 1270 DI_autopilotRequest 1 "DI_AP_RQST_ACTIVATE" 0 "DI_AP_RQST_IDLE" ;
VAL_ 1270 DI_rollPreventionState 7 "DI_RP_STATE_INIT" 6 "DI_RP_STATE_FAULT" 5 "DI_RP_STATE_MAX_BRAKE_TORQUE" 4 "DI_RP_STATE_HOLD" 3 "DI_RP_STATE_BUILD" 2 "DI_RP_STATE_READY" 1 "DI_RP_STATE_STANDBY" 0 "DI_RP_STATE_UNAVAILABLE" ;
VAL_ 1270 DI_pedalAssistCurveSelectForSX 15 "PEDAL_ASSIST_CURVE_15" 12 "PEDAL_ASSIST_CURVE_12" 11 "PEDAL_ASSIST_CURVE_11" 8 "PEDAL_ASSIST_CURVE_8" 6 "PEDAL_ASSIST_CURVE_6" 3 "PEDAL_ASSIST_CURVE_3" 0 "PEDAL_ASSIST_CURVE_0" ;
VAL_ 1270 DI_longitudinalControlStack 7 "VELOCITY_PROFILE_CONTROL_SUPPRESS_CANCEL" 6 "DIRECT_TORQUE_CONTROL" 5 "DIRECT_PEDAL_CONTROL" 4 "AEB_CONTROL" 3 "VELOCITY_PROFILE_CONTROL" 2 "LONC_TORQUE_PROFILER" 1 "LEGACY_CRUISE" 0 "REQUEST_SNA" ;
VAL_ 1270 DI_regenBlendingState 3 "BLEND_FRICTION_ONLY" 2 "BLEND_ACTIVE" 1 "BLEND_STANDBY" 0 "BLEND_UNAVAILABLE" ;
VAL_ 822 DI_sysDrivePowerRated 511 "SNA" ;
VAL_ 822 DI_performancePackage 7 "SNA" 6 "PERFORMANCE_2022" 5 "BASE_PLUS_2022" 4 "BASE_2022" 3 "BASE_PLUS" 2 "BASE_2024" 1 "PERFORMANCE" 0 "BASE" ;
VAL_ 822 DI_sysRegenPowerRated 255 "SNA" ;
VAL_ 950 DI_odometer 4294967295 "SNA" ;
VAL_ 599 DI_locSpeedEst 4095 "SNA" ;
VAL_ 599 DI_uiSpeed 511 "DI_UI_SPEED_SNA" ;
VAL_ 599 DI_uiSpeedUnits 1 "DI_SPEED_KPH" 0 "DI_SPEED_MPH" ;
VAL_ 599 DI_vehicleSpeed 8191 "SNA" ;
VAL_ 599 DI_velocityEstimatorState 5 "VE_STATE_BACKUP_MOTOR" 4 "VE_STATE_BACKUP_WHEELS_B" 3 "VE_STATE_BACKUP_WHEELS_A" 2 "VE_STATE_WHEELS_REDUCED" 1 "VE_STATE_WHEELS_NORMAL" 0 "VE_STATE_NOT_INITIALIZED" ;
VAL_ 597 DI_lastQualifiedGear 7 "DI_GEAR_SNA" 4 "DI_GEAR_D" 3 "DI_GEAR_N" 2 "DI_GEAR_R" 1 "DI_GEAR_P" 0 "DI_GEAR_INVALID" ;
VAL_ 597 DI_lastDrivingGear 7 "DI_GEAR_SNA" 4 "DI_GEAR_D" 3 "DI_GEAR_N" 2 "DI_GEAR_R" 1 "DI_GEAR_P" 0 "DI_GEAR_INVALID" ;
VAL_ 597 DI_suggestedGearReason 14 "REASON_1ST_SHFT_PAR_PARK_NO_USS" 13 "REASON_AP_NOT_READY" 12 "REASON_EEPROM" 11 "REASON_AP_MIA" 10 "REASON_AP_NOT_CONFIDENT" 9 "REASON_AP" 8 "REASON_SUB_SHFT" 7 "REASON_SUB_SHFT_PAR_PARK" 6 "REASON_SUB_SHFT_RE_BLCK_PAR_PARK" 5 "REASON_SUB_SHFT_RE_BLCK" 4 "REASON_1ST_SHFT_FR_BLCK_PAR_PARK" 3 "REASON_1ST_SHFT_RE_BLCK" 2 "REASON_1ST_SHFT_FR_BLCK" 1 "REASON_1ST_SHFT_PAR_PARK" 0 "REASON_RETRACE" ;
VAL_ 597 DI_smartShiftGear 2 "REVERSE" 1 "DRIVE" 0 "NONE" ;
VAL_ 597 DI_smartShiftUnavailableReason 18 "SMART_SHIFT_UNAVAILABLE_DAS_MIA" 17 "SMART_SHIFT_UNAVAILABLE_DAS_NOT_CONFIDENT" 16 "SMART_SHIFT_UNAVAILABLE_DISPLAY_ERROR" 15 "SMART_SHIFT_UNAVAILABLE_VDC_UNAVAILABLE" 14 "SMART_SHIFT_UNAVAILABLE_VHLD_UNAVAILABLE" 13 "SMART_SHIFT_UNAVAILABLE_OPD_UNAVAILABLE" 12 "SMART_SHIFT_UNAVAILABLE_BLS_UNKNOWN" 11 "SMART_SHIFT_UNAVAILABLE_IBST_MIA" 10 "SMART_SHIFT_SILENT_UNAVAILABLE_AEB_ACTIVE" 9 "SMART_SHIFT_SILENT_UNAVAILABLE_CRUISE_REGULATING" 8 "SMART_SHIFT_SILENT_UNAVAILABLE_GTW_NOT_QUALIFIED" 7 "SMART_SHIFT_SILENT_UNAVAILABLE_SGS_ACTIVE" 6 "SMART_SHIFT_SILENT_UNAVAILABLE_CLOSURE_OPEN" 5 "SMART_SHIFT_SILENT_UNAVAILABLE_CHARGE_CABLE_CONNECTED" 4 "SMART_SHIFT_SILENT_UNAVAILABLE_DRIVER_BUCKLED_QF" 3 "SMART_SHIFT_SILENT_UNAVAILABLE_NON_STANDARD_MODE" 2 "SMART_SHIFT_SILENT_UNAVAILABLE_UI_DISABLE" 1 "SMART_SHIFT_UNAVAILABLE_NONE" 0 "SMART_SHIFT_UNAVAILABLE_SNA" ;
VAL_ 296 DI_vehicleSpeedLimitType 2 "POWERTRAIN" 1 "USER" 0 "NONE" ;
VAL_ 296 DI_vehicleSpeedLimit 511 "SNA" ;
VAL_ 296 DI_vehicleSpeedLimitReason 16 "MANUAL_RECOVERY_MODE" 15 "FACTORY_BRAKE_BURNISHING" 14 "TAS_OFFROAD" 13 "SLIP_START_LIMIT" 12 "LV_DEGRADED" 11 "MAX_TIRE_TYPE" 10 "USER" 9 "FRUNK_OPEN" 8 "DAS_PEDAL_CONTROL" 7 "TAS" 6 "TRAILER_MODE" 5 "MAX_CAR_CONFIG" 4 "SERVICE_MODE" 3 "FACTORY_MODE" 2 "FACTORY_LOW_BRAKE_FLUID" 1 "DRIVE_UNIT_LIMIT" 0 "NONE" ;
VAL_ 296 DI_immobilizerAuthLevel 3 "IMMOBILIZER_AUTH_LEVEL_MANUAL_RECOVERY" 2 "IMMOBILIZER_AUTH_LEVEL_AUTONOMY" 1 "IMMOBILIZER_AUTH_LEVEL_USER_DRIVE" 0 "IMMOBILIZER_AUTH_LEVEL_NONE" ;
VAL_ 296 DI_manualRecoveryDistanceRemaini 127 "SNA" ;
VAL_ 296 DI_restrictedDrivingMode 1 "RESTRICTED_DRIVING_MANUAL_RECOVERY" 0 "RESTRICTED_DRIVING_MODE_NONE" ;
VAL_ 616 DI_sysDrivePowerMax 511 "SNA" ;
VAL_ 616 DI_primaryUnitSiliconType 1 "IGBT" 0 "MOSFET" ;
VAL_ 616 DI_sysRegenPowerMax 255 "SNA" ;
VAL_ 280 DI_secondaryGearControlStatus 1 "ACTIVE" 0 "NOT_ACTIVE" ;
VAL_ 280 DI_immobilizerState 6 "DI_IMM_STATE_FAULT" 5 "DI_IMM_STATE_RESET" 4 "DI_IMM_STATE_IDLE" 3 "DI_IMM_STATE_DISARMED" 2 "DI_IMM_STATE_AUTHENTICATING" 1 "DI_IMM_STATE_REQUEST" 0 "DI_IMM_STATE_INIT_SNA" ;
VAL_ 280 DI_systemState 5 "DI_SYS_ENABLE" 4 "DI_SYS_ABORT" 3 "DI_SYS_FAULT" 2 "DI_SYS_STANDBY" 1 "DI_SYS_IDLE" 0 "DI_SYS_UNAVAILABLE" ;
VAL_ 280 DI_brakePedalState 2 "INVALID" 1 "ON" 0 "OFF" ;
VAL_ 280 DI_gear 7 "DI_GEAR_SNA" 4 "DI_GEAR_D" 3 "DI_GEAR_N" 2 "DI_GEAR_R" 1 "DI_GEAR_P" 0 "DI_GEAR_INVALID" ;
VAL_ 280 DI_driveBlocked 4 "DRIVE_BLOCKED_TRUNK" 3 "DRIVE_BLOCKED_FALCON" 2 "DRIVE_BLOCKED_PROX" 1 "DRIVE_BLOCKED_FRUNK" 0 "DRIVE_BLOCKED_NONE" ;
VAL_ 280 DI_hvilSystemStatus 3 "SNA" 2 "CLOSED" 1 "OPEN" 0 "DISABLED" ;
VAL_ 280 DI_driveModeState 1 "DM_STATE_DRIVE" 0 "DM_STATE_NONDRIVE" ;
VAL_ 280 DI_shiftRequestType 3 "SMART_SHIFT" 2 "CCCM_SHIFT" 1 "GTW_SHIFT" 0 "NONE" ;
VAL_ 280 DI_accelPedalPos 255 "SNA" ;
VAL_ 280 DI_tractionControlMode 7 "TC_SLIPPERY_SURFACE" 6 "TC_OFFROAD_ASSIST" 5 "TC_DYNO_MODE" 4 "TC_ROLLS_MODE" 3 "TC_DEV_MODE_2" 2 "TC_DEV_MODE_1" 1 "TC_SLIP_START" 0 "TC_NORMAL" ;
VAL_ 280 DI_epbRequest 2 "DI_EPBREQUEST_UNPARK" 1 "DI_EPBREQUEST_PARK" 0 "DI_EPBREQUEST_NO_REQUEST" ;
VAL_ 280 DI_brakeSource 1 "DI" 0 "DAS" ;
VAL_ 280 DI_keepDrivePowerStateRequest 1 "KEEP_ALIVE" 0 "NO_REQUEST" ;
VAL_ 280 DI_trackModeState 2 "TRACK_MODE_ON" 1 "TRACK_MODE_AVAILABLE" 0 "TRACK_MODE_UNAVAILABLE" ;
VAL_ 280 DI_vehicleAcceleration -2048 "SNA" ;
VAL_ 2036 DI_vdcCommandTypeFrR 3 "VDC_SLIP_COMMAND" 2 "VDC_TORQUE_COMMAND" 1 "BTC_TORQUE_COMMAND" 0 "NO_TORQUE_COMMAND" ;
VAL_ 2036 DI_vdcCommandTypeReR 3 "VDC_SLIP_COMMAND" 2 "VDC_TORQUE_COMMAND" 1 "BTC_TORQUE_COMMAND" 0 "NO_TORQUE_COMMAND" ;
VAL_ 2036 DI_vdcCommandABSFrR 4 "MODIFY_BY_ABS_NO_GMA_NO_EBD" 3 "MODIFY_BY_ABS_NO_GMA" 2 "MODIFY_BY_ABS_ALL" 1 "FEED_THROUGH" 0 "NO_COMMAND" ;
VAL_ 2036 DI_vdcCommandABSReR 4 "MODIFY_BY_ABS_NO_GMA_NO_EBD" 3 "MODIFY_BY_ABS_NO_GMA" 2 "MODIFY_BY_ABS_ALL" 1 "FEED_THROUGH" 0 "NO_COMMAND" ;
VAL_ 2036 DI_brakeTorqueTarFrR 0 "NO_COMMAND" ;
VAL_ 2036 DI_brakeTorqueTarReR 0 "NO_COMMAND" ;
VAL_ 2036 DI_wheelSlipLimitFrR 0 "NO_COMMAND" ;
VAL_ 2036 DI_wheelSlipLimitReR 0 "NO_COMMAND" ;
VAL_ 615 DI_trailerDetected 1 "TRAILER_DETECTED" 0 "TRAILER_NOT_DETECTED" ;
VAL_ 615 DI_relativeTireTreadDepth -32 "SNA" ;
VAL_ 615 DI_tireFitment 3 "FITMENT_SNA" 1 "FITMENT_STAGGERED" 0 "FITMENT_SQUARE" ;
VAL_ 615 DI_massConfidence 1 "MASS_CONFIDED" 0 "MASS_NOT_CONFIDED" ;
VAL_ 615 DI_massConfidenceRLS 1 "MASS_CONFIDED" 0 "MASS_NOT_CONFIDED" ;
VAL_ 1237 DPB_alertID 337 "a337_EMCMain21Timeout" 336 "a336_EMCMain21DLC" 335 "a335_EMCMain21Counter" 334 "a334_EMCMain21Checksum" 333 "a333_EMCMain11Timeout" 332 "a332_EMCMain11DLC" 331 "a331_EMCMain11Counter" 330 "a330_EMCMain11Checksum" 329 "a329_standaloneEBRActive" 328 "a328_DIlocStatus2Timeout" 327 "a327_DIlocStatus2DLC" 326 "a326_DIlocStatus2Counter" 325 "a325_DIlocStatus2Checksum" 324 "a324_DASredundantBrakingControlChassisTimeout" 323 "a323_DASredundantBrakingControlChassisDLC" 322 "a322_DASredundantBrakingControlChassisCounter" 321 "a321_DASredundantBrakingControlChassisChecksum" 320 "a320_DASredundantBrakingControlPartyTimeout" 319 "a319_DASredundantBrakingControlPartyDLC" 318 "a318_DASredundantBrakingControlPartyCounter" 317 "a317_DASredundantBrakingControlPartyChecksum" 316 "a316_lowBrakeFluidDetectedOnHillSlope" 315 "a315_runningLeakageAndAirMonitoring" 314 "a314_runningCyclicVolumeCheck" 313 "a313_qualifiedBrakeEventDetected" 312 "a312_continuouslyActivatedValvesOff" 311 "a311_postrunDurationTooLong" 310 "a310_DIRAxleTorqueInvalid" 309 "a309_DIFAxleTorqueInvalid" 308 "a308_backupMode" 307 "a307_actuatorDegradedMap" 306 "a306_actuatorFallbackBasicMap" 305 "a305_DIbrakeTorqueCommandAndFlagMismatch" 304 "a304_actuatingDITorqueCmd" 303 "a303_actuatingDIFullTorqueCmd" 302 "a302_PM_locStateTimeout" 301 "a301_PM_locStateDLC" 300 "a300_PM_locStateChecksum" 299 "a299_PM_locStateCounter" 298 "a298_runningPlungerCircuitTest" 297 "a297_undefinedAlertDetected" 296 "a296_StatInvalid_DI_FullSNA" 295 "a295_hbaTrackModeActive" 294 "a294_hbaNormalModeActive" 293 "a293_CBDS_fmeInternalEvent" 292 "a292_CBDS_fillBufferThreshold" 291 "a291_extDBRRequestTooLow" 290 "a290_securityInfo" 289 "a289_evacFillNotComplete" 288 "a288_PlantDegradedSW" 287 "a287_brakeCmdStateInvalid" 286 "a286_ebrCmdStateInvalid" 285 "a285_DIbrakeCommandTimeout" 284 "a284_DIbrakeCommandDLC" 283 "a283_DIbrakeCommandChecksum" 282 "a282_DIbrakeCommandCounter" 281 "a281_brakeFluidOORHigh" 280 "a280_LowBrakeFluid" 279 "a279_VCFRONTsensorsTimeout" 278 "a278_VCFRONTsensorsDLC" 277 "a277_VCFRONTsensorsChecksum" 276 "a276_VCFRONTsensorsCounter" 275 "a275_Ps1Ps2PlausibilityFault" 274 "a274_AswSystemTimeOut" 273 "a273_SMMOneRequestsInit" 272 "a272_runtimeAssertionFault" 271 "a271_RPSWrongCalibData" 270 "a270_RPSVectorRangeLow" 269 "a269_RPSVectorRangeHigh" 268 "a268_RPSVectorOscillating" 267 "a267_RpsAngleImplausible" 266 "a266_RPSNvMReadFault" 265 "a265_WdhTaskMonConCnt" 264 "a264_WdhSwBistConCnt" 263 "a263_WdhAsicWdErrorCntStuck" 262 "a262_WdhAsicWdErrorCntLimit" 261 "a261_WdhAsicWdCmdMissing" 260 "a260_valveRelaySafetySwitchFault" 259 "a259_valveRelayTestUndervoltage" 258 "a258_valveRelayOffContinuous" 257 "a257_valveRelayOnContinuous" 256 "a256_valveRelayActuationFault" 255 "a255_valveRelayShort" 254 "a254_valveMV9Fault" 253 "a253_valveMV82Fault" 252 "a252_valveMV81Fault" 251 "a251_valveMV8Fault" 250 "a250_valveMV7Fault" 249 "a249_valveMV62Fault" 248 "a248_valveMV61Fault" 247 "a247_valveMV6Fault" 246 "a246_valveMV5Fault" 245 "a245_valveMV0Fault" 244 "a244_valvesGenericFault" 243 "a243_microSupplyError" 242 "a242_uCSafetyNotificationGRAM" 241 "a241_uCSafetyNotification" 240 "a240_microSafetyLogicFault" 239 "a239_microSafetyFault" 238 "a238_microRegisterFault" 237 "a237_uCVoltageDividerDrift" 236 "a236_UB6SupplyPathFault" 235 "a235_UB6PlausiMonFault" 234 "a234_systemTaskOverRun" 233 "a233_systemTaskJitter" 232 "a232_systemErrorHook" 231 "a231_stackOverUnderFlow" 230 "a230_OSErrorHook" 229 "a229_IREFOutOfRange" 228 "a228_supplyASICInitFault" 227 "a227_brakeFluidLoss" 226 "a226_U5VTestFault" 225 "a225_U5VOutOfRange" 224 "a224_brakeBoostLost" 223 "a223_RAMFault" 222 "a222_excessiveEcuResetsDetected" 221 "a221_notShutdownRight" 220 "a220_excessiveBoostWakeupsDetected" 219 "a219_pressureSensor2Fault" 218 "a218_pressureSensor2Temp" 217 "a217_pressureSensor2Fault" 216 "a216_pressureSensor2Low" 215 "a215_pressureSensor2High" 214 "a214_pressureSensor2Short" 213 "a213_pressureSensor1Fault" 212 "a212_pressureSensor1Temp" 211 "a211_pressureSensor1Fault" 210 "a210_pressureSensor1Low" 209 "a209_pressureSensor1High" 208 "a208_pressureSensor1Short" 207 "a207_hydraulicOvervoltage" 206 "a206_OSTaskSchemeError" 205 "a205_NvMWriteCycleExceed" 204 "a204_CANUndervoltage" 203 "a203_ABSNotAvailable" 202 "a202_vehicleStandstillQFaulty" 201 "a201_vehicleSpeedQFaulty" 200 "a200_ESPRunoutSupportNotAvailable" 199 "a199_pMC1QFaulty" 198 "a198_CANOvervoltage" 197 "a197_VCRIGHTepbmStatusTimeout" 196 "a196_VCRIGHTepbmStatusDLC" 195 "a195_VCRIGHTepbmStatusChecksum" 194 "a194_VCRIGHTepbmStatusCounter" 193 "a193_VCLEFTepbmStatusTimeout" 192 "a192_VCLEFTepbmStatusDLC" 191 "a191_VCLEFTepbmStatusChecksum" 190 "a190_VCLEFTepbmStatusCounter" 189 "a189_LVPowerStateCounter" 188 "a188_LVPowerStateDLC" 187 "a187_LVPowerStateChecksum" 186 "a186_LVPowerStateTimeout" 185 "a185_RCMInertial2Timeout" 184 "a184_RCMInertial2DLC" 183 "a183_RCMInertial2Checksum" 182 "a182_RCMInertial2Counter" 181 "a181_PMstate2Timeout" 180 "a180_PMstate2DLC" 179 "a179_PMstate2Checksum" 178 "a178_PMstate2Counter" 177 "a177_ESP_modulator3Timeout" 176 "a176_ESP_modulator3DLC" 175 "a175_ESP_modulator3Checksum" 174 "a174_ESP_modulator3Counter" 173 "a173_ESP_modulator2Timeout" 172 "a172_ESP_modulator2DLC" 171 "a171_ESP_modulator2Checksum" 170 "a170_ESP_modulator2Counter" 169 "a169_ESP_chassis3Timeout" 168 "a168_ESP_chassis3DLC" 167 "a167_ESP_chassis3Checksum" 166 "a166_ESP_chassis3Counter" 165 "a165_ESP_modulator1Timeout" 164 "a164_ESP_modulator1DLC" 163 "a163_ESP_modulator1Checksum" 162 "a162_ESP_modulator1Counter" 161 "a161_EPBRstatusTimeout" 160 "a160_EPBRstatusDLC" 159 "a159_EPBRstatusChecksum" 158 "a158_EPBRstatusCounter" 157 "a157_EPBLstatusTimeout" 156 "a156_EPBLstatusDLC" 155 "a155_EPBLstatusChecksum" 154 "a154_EPBLstatusCounter" 153 "a153_DIRtorqueTimeout" 152 "a152_DIRtorqueDLC" 151 "a151_DIRtorqueChecksum" 150 "a150_DIRtorqueCounter" 149 "a149_DIFtorqueTimeout" 148 "a148_DIFtorqueDLC" 147 "a147_DIFtorqueChecksum" 146 "a146_DIFtorqueCounter" 145 "a145_DIsystemStatusTimeout" 144 "a144_DIsystemStatusDLC" 143 "a143_DIsystemStatusChecksum" 142 "a142_DIsystemStatusCounter" 141 "a141_DIchassisControlTimeout" 140 "a140_DIchassisControlDLC" 139 "a139_DIchassisControlChecksum" 138 "a138_DIchassisControlCounter" 137 "a137_ASICOvercurrentOnWRHS" 136 "a136_ASICOvercurrentOnGPIO50_4" 135 "a135_ASICOvercurrentOnGPIO50_3" 134 "a134_ASICOvercurrentOnGPIO50_2" 133 "a133_ASICOvercurrentOnGPIO50_1" 132 "a132_ASICOvercurrentOnGPIO250_2" 131 "a131_ASICOvercurrentOnGPIO250_1" 130 "a130_AsicMalfunctionDetected" 129 "a129_AsicTrimmingNotCompleted" 128 "a128_micSpiTransferError" 127 "a127_hydraulicAsicShortCircuit" 126 "a126_MICB6TransferError" 125 "a125_B6AsicFault" 124 "a124_asicOscillatorError" 123 "a123_micAsicInitTestError" 122 "a122_micAsicClkInError" 121 "a121_LiPSOutOfRangeLow" 120 "a120_LiPSOutOfRangeHigh" 119 "a119_LiPS2PwmTransmission" 118 "a118_LiPS2PwmLineLow" 117 "a117_LiPS2PwmLineHigh" 116 "a116_LiPS1SentTransmission" 115 "a115_LiPS1SentSensor" 114 "a114_LiPS1SentLineLow" 113 "a113_LiPS1SentLineHigh" 112 "a112_hydraulicUndervoltage" 111 "a111_hydraulicHardUndervoltage" 110 "a110_HWBISTError" 109 "a109_GTMTbuMonError" 108 "a108_GTMRefFrequencyError" 107 "a107_vrOnFails" 106 "a106_ecuBistCmdTestFault" 105 "a105_ecuWdSContinuousError" 104 "a104_ecuWdStartuptestFault" 103 "a103_ecuVrViaSpiFails" 102 "a102_ecuVrOnWhileWdTimeout" 101 "a101_ecuFastWdTestFault" 100 "a100_ecuErrpinCounterFault" 99 "a099_ecuEnContinuousError" 98 "a098_ecuEnableHyLowFault" 97 "a097_ecuEnableHyHighFault" 96 "a096_ecuEnableElLowFault" 95 "a095_ecuEnableElHighFault" 94 "a094_ecuClockTestFault" 93 "a093_ecuBistFaultCtrFault" 92 "a092_decoupleBitTestFault" 91 "a091_MRGPathTestFault" 90 "a090_flashFault" 89 "a089_ecuBandgap" 88 "a088_DMATransferError" 87 "a087_diagHydProtectionVlvFault" 86 "a086_diagHydProtectionPressFault" 85 "a085_infoFailureWrongCUBASHandlingDetected" 84 "a084_RBCPUException" 83 "a083_chargePumpUndervoltage" 82 "a082_chargePumpFault" 81 "a081_tempSensImplausVoltage" 80 "a080_tempSens2ShortToGround" 79 "a079_tempSens2ShortToSupply" 78 "a078_tempSens1ShortToGround" 77 "a077_tempSens1ShortToSupply" 76 "a076_rotorSinOutOfRangeLow" 75 "a075_rotorSinOutOfRangeHigh" 74 "a074_rotorCosOutOfRangeLow" 73 "a073_rotorCosOutOfRangeHigh" 72 "a072_OBDCurrent2OORLow" 71 "a071_OBDCurrent2OORHigh" 70 "a070_OBDCurrent1OORLow" 69 "a069_OBDCurrent1OORHigh" 68 "a068_BLMMuxerTimeoutError" 67 "a067_current2OffsetLow" 66 "a066_current2OffsetHigh" 65 "a065_current1OffsetLow" 64 "a064_current1OffsetHigh" 63 "a063_motorConfigMismatch" 62 "a062_loadDumpOnFSLTest" 61 "a061_bridgeSwitchInitError" 60 "a060_motorBridgeDriverFault" 59 "a059_factoryModeActive" 58 "a058_AdcSelftestC5P" 57 "a057_AdcPinTest" 56 "a056_AdcPeripheralFault" 55 "a055_unsupportedSeriesHWDetected" 54 "a054_unsupportedHW" 53 "a053_hydraulicAssemblyModeActive" 52 "a052_PSIDTimeOut" 51 "a051_PSCVoltageImplausible" 50 "a050_supplyUndervoltageLvl3" 49 "a049_supplyUndervoltageLvl2" 48 "a048_supplyUndervoltageLvl1" 47 "a047_pPlungerPlausCheckFailure" 46 "a046_supplyOvervoltageLvl3" 45 "a045_supplyOvervoltageLvl2" 44 "a044_supplyOvervoltageLvl1" 43 "a043_PSCMotorSizeReadFault" 42 "a042_motorLoadPressImplausible" 41 "a041_PSCGearRatioReadFault" 40 "a040_plungerCircuitPressLowGoodCheck" 39 "a039_plungerCircuitPressLow" 38 "a038_plungerCircuitPressHighGoodCheck" 37 "a037_plungerCircuitPressHigh" 36 "a036_lossOfPDUInstanceDetected" 35 "a035_PDURouterinitializationFailed" 34 "a034_lipsMemoryEmpty" 33 "a033_motorDynamicLimited" 32 "a032_HWParamWriteFailed" 31 "a031_HWParamReadFailed" 30 "a030_notShutDownRight" 29 "a029_motorTestFault" 28 "a028_motorTempHighLevel2" 27 "a027_motorTempHighLevel1" 26 "a026_LiPSIDTimeout" 25 "a025_backupCircuitLeakage" 24 "a024_ESPLDMFailure" 23 "a023_initialPlungerCheckFailed" 22 "a022_brakeSystemOverheatLvl2" 21 "a021_brakeSystemOverheatLvl1" 20 "a020_ecuHuMismatch" 19 "a019_DETReportError" 18 "a018_largeLeakageDetectedGoodCheck" 17 "a017_largeLeakageDetected" 16 "a016_CAN2BusOff" 15 "a015_CAN1BusOff" 14 "a014_CANControllerHWFault" 13 "a013_softPedalChar" 12 "a012_PtsNonZeroStage2" 11 "a011_PtsNonZeroStage1" 10 "a010_LiPSPtsConsistency" 9 "a009_LiPSPts2Offset" 8 "a008_LiPSPts1Offset" 7 "a007_PMCLeakageDetected" 6 "a006_hardPedalCharGoodCheck" 5 "a005_hardPedalChar" 4 "a004_assertionFault" 3 "a003_AswEEPROMReadFailure" 2 "a002_pMC2SensorOffsetHigh" 1 "a001_pPlungerSensorOffsetHigh" 0 "ALERT_DO_NOT_USE_ZERO" ;
VAL_ 1237 DPB_alertState 1 "SET" 0 "CLEARED" ;
VAL_ 999 DPB_matrixIndex 5 "AlertMatrix5" 4 "AlertMatrix4" 3 "AlertMatrix3" 2 "AlertMatrix2" 1 "AlertMatrix1" 0 "AlertMatrix0" ;
VAL_ 1426 EPAS3P_alertID 171 "a171_difCsError" 170 "a170_difCntError" 169 "a169_difMia" 168 "a168_torsionBarTorqueQfDegraded" 167 "a167_epbStatusCsError" 166 "a166_epbStatusCntError" 165 "a165_epbStatusMia" 164 "a164_initTestDCSInfo" 163 "a163_initTestGateDrvrInfo" 162 "a162_initTestHSDFetInfo" 161 "a161_initTestPhaDisconnInfo" 160 "a160_latentFaultTestResult" 159 "a159_pmState2CsError" 158 "a158_pmState2CntError" 157 "a157_pmState2Mia" 156 "a156_angleSensorDivergence" 155 "a155_backupEacActive" 154 "a154_assistTorqueDisabled" 153 "a153_dcsInitOffset" 152 "a152_dcsDiagReg" 151 "a151_dcsCboot" 150 "a150_currentSensOffsetDetect" 149 "a149_currentSensPathSwitch" 148 "a148_vMaxAssist" 147 "a147_backupVehSpeed" 146 "a146_diSpdCsError" 145 "a145_diSpdCntError" 144 "a144_diSpdMia" 137 "a137_piCtrlCounter85" 136 "a136_piCtrlCounter50" 135 "a135_piCtrlCounter25" 134 "a134_motFeedFwdCounter85" 133 "a133_motFeedFwdCounter50" 132 "a132_motFeedFwdCounter25" 131 "a131_phaseFeedbackError" 130 "a130_sasOffsetNotCal" 129 "a129_combEcu1StatFail" 128 "a128_apsCsError" 127 "a127_apsCntError" 126 "a126_apsMia" 125 "a125_trqSensTrimOutRange" 124 "a124_tempSensStuckInRange" 123 "a123_combEcu2StatFail" 122 "a122_olpActive" 121 "a121_pvtEcuStatCrcError" 120 "a120_pvtEcuStatCntError" 119 "a119_pvtEcuStatMia" 118 "a118_privateBusOff" 117 "a117_ecuStatCrcError" 116 "a116_ecuStatCntError" 115 "a115_ecuStatMia" 114 "a114_gtwConfigMia" 113 "a113_sasStatusError" 112 "a112_sasCsError" 111 "a111_sasCntError" 110 "a110_sasMia" 109 "a109_uiTuneReqCsError" 108 "a108_uiTuneReqCntError" 107 "a107_uiTuneReqMia" 106 "a106_vcFrontTempMia" 105 "a105_vcFrontCsError" 104 "a104_vcFrontCntError" 103 "a103_vcFrontMia" 102 "a102_diCsError" 101 "a101_diCntError" 100 "a100_diMia" 99 "a099_yawRateStatus" 98 "a098_rcmCsError" 97 "a097_rcmCntError" 96 "a096_rcmMia" 95 "a095_espWsStatus" 94 "a094_espWrCsError" 93 "a093_espWrCntError" 92 "a092_espWrMia" 91 "a091_espWsCsError" 90 "a090_espWsCntError" 89 "a089_espWsMia" 88 "a088_dasCsError" 87 "a087_dasCntError" 86 "a086_dasMia" 85 "a085_canBusOff" 84 "a084_eacCancelled" 83 "a083_crcMismatch" 82 "a082_polarityCalError" 81 "a081_coggCompError" 80 "a080_ecuInitArbError" 79 "a079_backupCurrentPlaus" 78 "a078_phaseDisconnectError" 77 "a077_highSideFetError" 76 "a076_tempSensOutofRange" 75 "a075_fspPwrCut" 74 "a074_overHeatProtect" 73 "a073_motParEstError" 72 "a072_motFeedFwdError" 71 "a071_vehSpdCorrError" 70 "a070_hodCorrError" 69 "a069_eacCorrError" 68 "a068_hystCorrError" 67 "a067_yawDampCorrError" 66 "a066_returnCorrError" 65 "a065_trqTarCorrError" 64 "a064_phaseCompCorrError" 63 "a063_dampCorrError" 62 "a062_assistCorrError" 61 "a061_bridgeUv" 60 "a060_battBridgeDiff" 59 "a059_battOvReduced" 58 "a058_battOv" 57 "a057_battUvReduced" 56 "a056_battUv" 55 "a055_floatPointError" 54 "a054_memoryProtectError" 53 "a053_extWatchdogError" 52 "a052_intWatchdogError" 51 "a051_mcuSupError" 50 "a050_mcuSmuError" 49 "a049_piCtrlError" 48 "a048_motPosCalError" 47 "a047_motPosCorrError" 46 "a046_motPos2tempError" 45 "a045_motPos2LogicError" 44 "a044_motPos2MagnetMia" 43 "a043_motPos2Uv" 42 "a042_motPos2ParityError" 41 "a041_motPos1tempError" 40 "a040_motPos1LogicError" 39 "a039_motPos1MagnetMia" 38 "a038_motPos1Uv" 37 "a037_motPos1ParityError" 36 "a036_vbbSupplyOv" 35 "a035_vbbSupplyUv" 34 "a034_vRegError" 33 "a033_vRegOutputOv" 32 "a032_vRegOutputUv" 31 "a031_abnormalShutdown" 30 "a030_phaseWbootUv" 29 "a029_phaseVbootUv" 28 "a028_phaseUbootUv" 27 "a027_phaseWlowOv" 26 "a026_phaseWhighOv" 25 "a025_phaseVlowOv" 24 "a024_phaseVhighOv" 23 "a023_phaseUlowOv" 22 "a022_phaseUhighOv" 21 "a021_phaseWlowUv" 20 "a020_phaseWhighUv" 19 "a019_phaseVlowUv" 18 "a018_phaseVhighUv" 17 "a017_phaseUlowUv" 16 "a016_phaseUhighUv" 15 "a015_gateDriveEeprom" 14 "a014_gateDriveTxError" 13 "a013_gateDriveError" 12 "a012_currentSensCalError" 11 "a011_currentSensError" 10 "a010_trqSensCalError" 9 "a009_sentDiff" 8 "a008_trqSens2Eeprom" 7 "a007_trqSens2Supply" 6 "a006_sent2Error" 5 "a005_sent2Mia" 4 "a004_trqSens1Eeprom" 3 "a003_trqSens1Supply" 2 "a002_sent1Error" 1 "a001_sent1Mia" 0 "ALERT_DO_NOT_USE_ZERO" ;
VAL_ 1426 EPAS3P_alertState 1 "SET" 0 "CLEARED" ;
VAL_ 1426 EPAS3P_a147_transitionReason 2 "MIA" 1 "WSS_FAILURE" 0 "DATA_INTEGRITY" ;
VAL_ 1426 EPAS3P_a160_currentSensorStatus 2 "STATUS_UNKNOWN" 1 "PROBABLE_FAILURE" 0 "NO_ISSUE" ;
VAL_ 1426 EPAS3P_a160_gateDriverStatus 2 "STATUS_UNKNOWN" 1 "PROBABLE_FAILURE" 0 "NO_ISSUE" ;
VAL_ 1426 EPAS3P_a160_highSideDisconnectFe 2 "STATUS_UNKNOWN" 1 "PROBABLE_FAILURE" 0 "NO_ISSUE" ;
VAL_ 1426 EPAS3P_a160_phaseDisconnectFetSt 2 "STATUS_UNKNOWN" 1 "PROBABLE_FAILURE" 0 "NO_ISSUE" ;
VAL_ 1426 EPAS3P_a160_inverterFetStatus 2 "STATUS_UNKNOWN" 1 "PROBABLE_FAILURE" 0 "NO_ISSUE" ;
VAL_ 1426 EPAS3P_a160_hsdFetFailShortTest 2 "NOT_RAN" 1 "FAIL" 0 "PASS" ;
VAL_ 1426 EPAS3P_a160_phaDisconnFailOpenTe 2 "NOT_RAN" 1 "FAIL" 0 "PASS" ;
VAL_ 1426 EPAS3P_a160_phaDisconnFailShortT 2 "NOT_RAN" 1 "FAIL" 0 "PASS" ;
VAL_ 1426 EPAS3P_a160_invFetInitTest 2 "NOT_RAN" 1 "FAIL" 0 "PASS" ;
VAL_ 1426 EPAS3P_a160_gateDrvrInitTest 2 "NOT_RAN" 1 "FAIL" 0 "PASS" ;
